VERSION ""

NS_ :

BS_:

BU_: WCM VPM VLM VKM UVM TIM TEST_TOOL_2 TEST_TOOL_1 TCP TCM TCCM3 TCCM STC SRR_SRR SRR_SLR SRR_RR SRR_RF SRR_LR_CR SRR_LF SIB SDM SCL SBZA_R SBZA_L SBM SADS RadioLow RSC RDCM PTM PDR PA NVM MTCM_R MTCM_L MSM_RR MSM_P MSM_LR MSM_D MSB2 MSB1 MRCM_R MRCM_L MFC LRR_HC LRR LIB1 IPC ICS_Info ICCM HVAC_FP_R HVAC_FP_F HUD_CAN HDLM FCM_LC FCM EPS EOCM_HCP2 EOCM_HCP1 EOCM ELM ECP_X1 ECP_MC ECP_E ECM EBCM DMS DEFC DCM CSM CMMb CMMa CGM BSM_MH BSM BCM ARS ARB APA AOS AMP ALC AHS AHL_AFL AGC

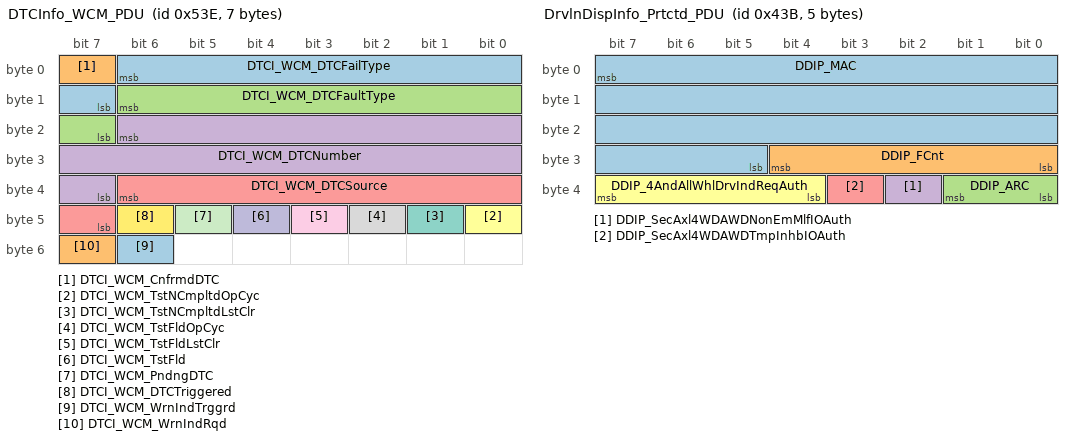
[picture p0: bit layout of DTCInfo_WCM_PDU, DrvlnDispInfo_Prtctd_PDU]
BO_ 1342 DTCInfo_WCM_PDU: 7 WCM
 SG_ DTCI_WCM_DTCFailType : 6|8@0+ (1,0) [0|255] "" CSM,TCP
 SG_ DTCI_WCM_CnfrmdDTC : 7|1@0+ (1,0) [0|1] "" CSM,TCP
 SG_ DTCI_WCM_DTCFaultType : 14|8@0+ (1,0) [0|3] "" CSM,TCP
 SG_ DTCI_WCM_DTCNumber : 22|16@0+ (1,0) [0|65535] "" CSM,TCP
 SG_ DTCI_WCM_DTCSource : 38|8@0+ (1,0) [0|255] "" CGM,CSM,TCP
 SG_ DTCI_WCM_TstNCmpltdOpCyc : 40|1@0+ (1,0) [0|1] "" CSM,TCP
 SG_ DTCI_WCM_TstNCmpltdLstClr : 41|1@0+ (1,0) [0|1] "" CSM,TCP
 SG_ DTCI_WCM_TstFldOpCyc : 42|1@0+ (1,0) [0|1] "" CSM,TCP
 SG_ DTCI_WCM_TstFldLstClr : 43|1@0+ (1,0) [0|1] "" CSM,TCP
 SG_ DTCI_WCM_TstFld : 44|1@0+ (1,0) [0|1] "" CSM,TCP
 SG_ DTCI_WCM_PndngDTC : 45|1@0+ (1,0) [0|1] "" CSM,TCP
 SG_ DTCI_WCM_DTCTriggered : 46|1@0+ (1,0) [0|1] "" CSM,TCP
 SG_ DTCI_WCM_WrnIndTrggrd : 54|1@0+ (1,0) [0|1] "" CSM,TCP
 SG_ DTCI_WCM_WrnIndRqd : 55|1@0+ (1,0) [0|1] "" CSM,TCP

BO_ 1085 DrvlnDispInfo_PCSM_PDU: 8 CGM
 SG_ DrvlnDispInfo_PCSM : 0|64@1+ (1,0) [0|1.84467e+019] "" IPC

BO_ 1083 DrvlnDispInfo_Prtctd_PDU: 5 CGM
 SG_ DDIP_MAC : 7|27@0+ (1,0) [0|1.34218e+008] "" IPC
 SG_ DDIP_FCnt : 28|5@0+ (1,0) [0|31] "" IPC
 SG_ DDIP_ARC : 33|2@0+ (1,0) [0|3] "" IPC
 SG_ DDIP_SecAxl4WDAWDNonEmMlfIOAuth : 34|1@0+ (1,0) [0|1] "" CSM,IPC
 SG_ DDIP_SecAxl4WDAWDTmpInhbIOAuth : 35|1@0+ (1,0) [0|1] "" CSM,IPC,TCP
 SG_ DDIP_4AndAllWhlDrvIndReqAuth : 39|4@0+ (1,0) [0|15] "" IPC

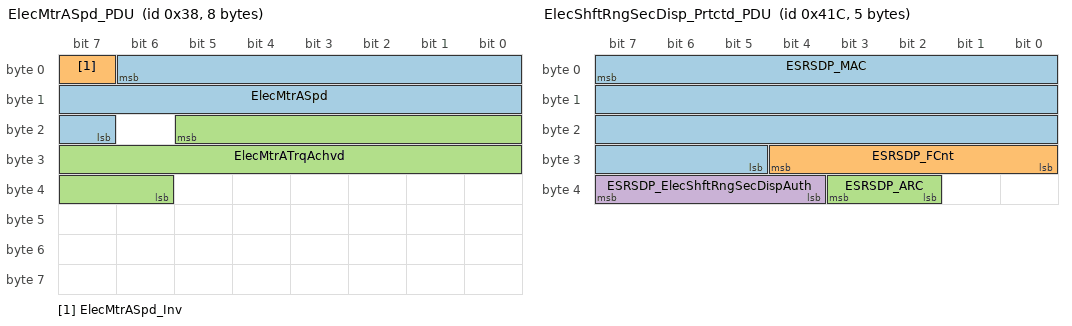
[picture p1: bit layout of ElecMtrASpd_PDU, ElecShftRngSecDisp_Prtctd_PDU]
BO_ 56 ElecMtrASpd_PDU: 8 CGM
 SG_ ElecMtrASpd : 6|16@0- (1,0) [-32768|32767] "RPM" AMP
 SG_ ElecMtrASpd_Inv : 7|1@0+ (1,0) [0|1] "" AMP
 SG_ ElecMtrATrqAchvd : 21|16@0- (0.125,0) [-4096|4095.88] "Nm" AMP

BO_ 1056 ElecShftRngSecDisp_PCSM_PDU: 8 CGM
 SG_ ElecShftRngSecDisp_PCSM : 0|64@1+ (1,0) [0|1.84467e+019] "" IPC

BO_ 1052 ElecShftRngSecDisp_Prtctd_PDU: 5 CGM
 SG_ ESRSDP_MAC : 7|27@0+ (1,0) [0|1.34218e+008] "" IPC
 SG_ ESRSDP_FCnt : 28|5@0+ (1,0) [0|31] "" IPC
 SG_ ESRSDP_ARC : 35|2@0+ (1,0) [0|3] "" IPC
 SG_ ESRSDP_ElecShftRngSecDispAuth : 39|4@0+ (1,0) [0|12] "" CSM,IPC

BO_ 592 ElecStrgColLck_PCSM_PDU: 8 CGM
 SG_ ElecStrgColLck_PCSM : 0|64@1+ (1,0) [0|1.84467e+019] "" IPC

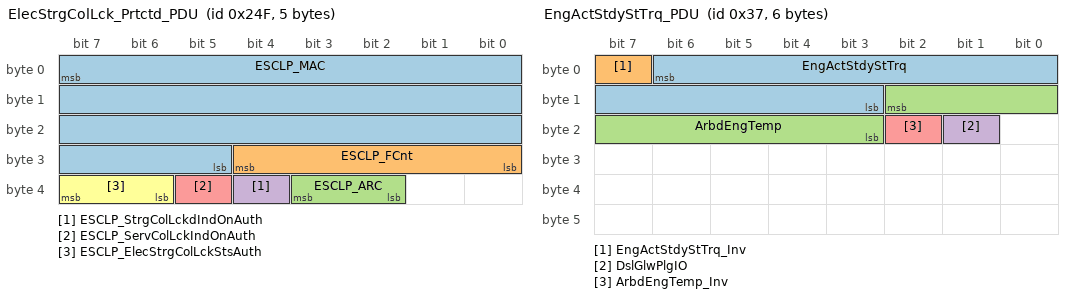
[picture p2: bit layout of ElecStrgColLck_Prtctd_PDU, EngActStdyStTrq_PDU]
BO_ 591 ElecStrgColLck_Prtctd_PDU: 5 CGM
 SG_ ESCLP_MAC : 7|27@0+ (1,0) [0|1.34218e+008] "" IPC
 SG_ ESCLP_FCnt : 28|5@0+ (1,0) [0|31] "" IPC
 SG_ ESCLP_ARC : 35|2@0+ (1,0) [0|3] "" IPC
 SG_ ESCLP_StrgColLckdIndOnAuth : 36|1@0+ (1,0) [0|1] "" IPC
 SG_ ESCLP_ServColLckIndOnAuth : 37|1@0+ (1,0) [0|1] "" IPC
 SG_ ESCLP_ElecStrgColLckStsAuth : 39|2@0+ (1,0) [0|3] "" CSM,IPC

BO_ 55 EngActStdyStTrq_PDU: 6 CGM
 SG_ EngActStdyStTrq : 6|12@0+ (0.5,-848) [-848|1199.5] "Nm" AMP,CSM,IPC,PDR,RadioLow
 SG_ EngActStdyStTrq_Inv : 7|1@0+ (1,0) [0|1] "" AMP,CSM,IPC,PDR
 SG_ ArbdEngTemp : 10|8@0+ (1,-40) [-40|215] "deg C" CSM,IPC,PDR
 SG_ DslGlwPlgIO : 17|1@0+ (1,0) [0|1] "" CSM,IPC
 SG_ ArbdEngTemp_Inv : 18|1@0+ (1,0) [0|1] "" CSM,IPC,PDR

BO_ 1812 EngIdleActvTm_PCSM_PDU: 8 IPC
 SG_ EngIdleActvTm_PCSM : 0|64@1+ (1,0) [0|1.84467e+019] "" CGM

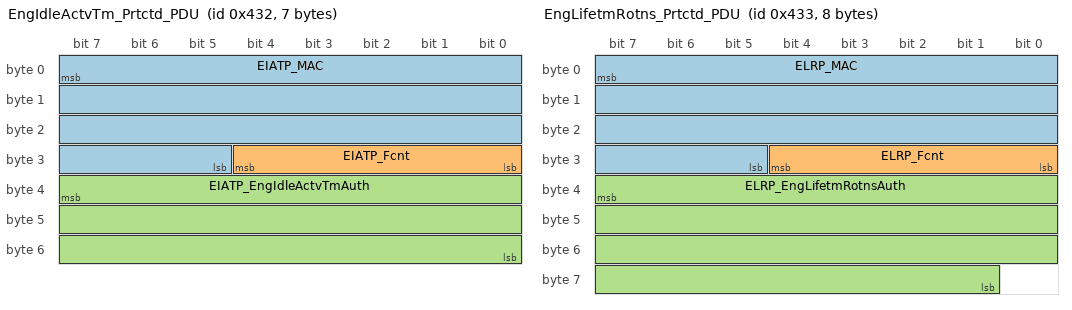
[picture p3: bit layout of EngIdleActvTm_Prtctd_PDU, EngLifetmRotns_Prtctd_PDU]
BO_ 1074 EngIdleActvTm_Prtctd_PDU: 7 IPC
 SG_ EIATP_MAC : 7|27@0+ (1,0) [0|1.34218e+008] "" CGM
 SG_ EIATP_Fcnt : 28|5@0+ (1,0) [0|31] "" CGM
 SG_ EIATP_EngIdleActvTmAuth : 39|24@0+ (1,0) [0|1.67772e+007] "min" CGM,CSM

BO_ 1813 EngLifetmRotns_PCSM_PDU: 8 IPC
 SG_ EngLifetmRotns_PCSM : 0|64@1+ (1,0) [0|1.84467e+019] "" CGM

BO_ 1075 EngLifetmRotns_Prtctd_PDU: 8 IPC
 SG_ ELRP_MAC : 7|27@0+ (1,0) [0|1.34218e+008] "" Vector__XXX
 SG_ ELRP_Fcnt : 28|5@0+ (1,0) [0|31] "" Vector__XXX
 SG_ ELRP_EngLifetmRotnsAuth : 39|31@0+ (1000,0) [0|2.14748e+012] "rotations" CSM

BO_ 1814 EngRunActvTm_PCSM_PDU: 8 IPC
 SG_ EngRunActvTm_PCSM : 0|64@1+ (1,0) [0|1.84467e+019] "" CGM

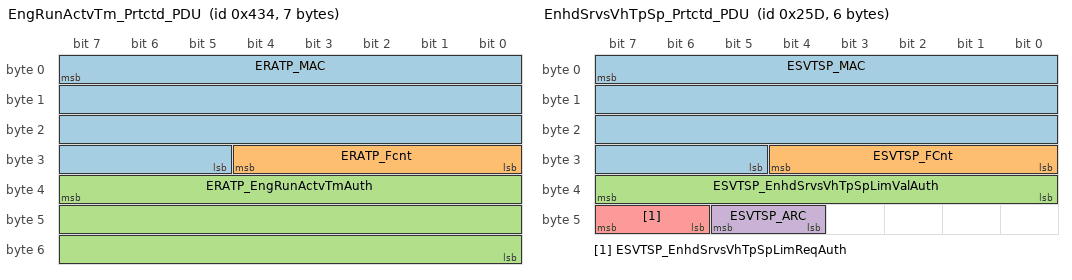
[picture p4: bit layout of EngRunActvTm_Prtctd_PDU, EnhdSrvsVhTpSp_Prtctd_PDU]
BO_ 1076 EngRunActvTm_Prtctd_PDU: 7 IPC
 SG_ ERATP_MAC : 7|27@0+ (1,0) [0|1.34218e+008] "" CGM
 SG_ ERATP_Fcnt : 28|5@0+ (1,0) [0|31] "" CGM
 SG_ ERATP_EngRunActvTmAuth : 39|24@0+ (1,0) [0|1.67772e+007] "min" CGM,CSM

BO_ 1817 EnhdSrvsVhTpSp_PCSM_PDU: 8 TCP
 SG_ EnhdSrvsVhTpSp_PCSM : 0|64@1+ (1,0) [0|1.84467e+019] "" Vector__XXX

BO_ 605 EnhdSrvsVhTpSp_Prtctd_PDU: 6 TCP
 SG_ ESVTSP_MAC : 7|27@0+ (1,0) [0|1.34218e+008] "" Vector__XXX
 SG_ ESVTSP_FCnt : 28|5@0+ (1,0) [0|31] "" Vector__XXX
 SG_ ESVTSP_EnhdSrvsVhTpSpLimValAuth : 39|8@0+ (2,0) [0|510] "km/h" Vector__XXX
 SG_ ESVTSP_ARC : 45|2@0+ (1,0) [0|3] "" Vector__XXX
 SG_ ESVTSP_EnhdSrvsVhTpSpLimReqAuth : 47|2@0+ (1,0) [0|2] "" Vector__XXX

BO_ 1795 FrtTirePrs_PCSM_PDU: 8 CGM
 SG_ FrtTirePrs_PCSM : 0|64@1+ (1,0) [0|1.84467e+019] "" IPC

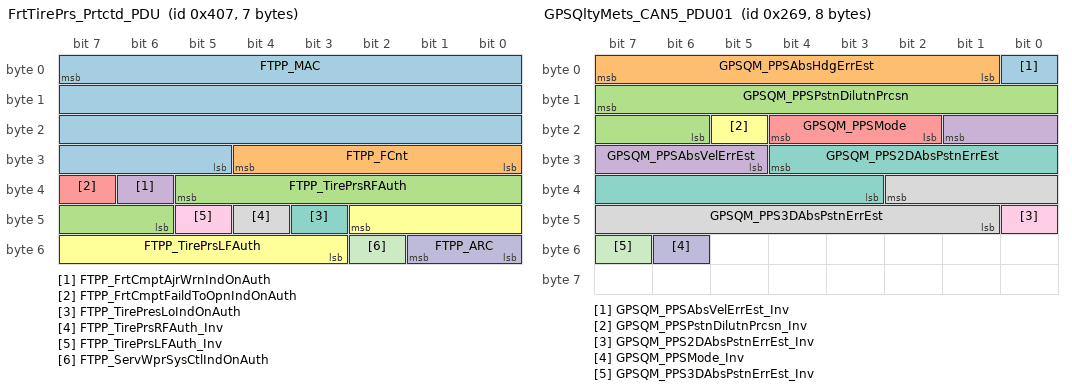
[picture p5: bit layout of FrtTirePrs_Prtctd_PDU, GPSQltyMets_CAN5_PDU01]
BO_ 1031 FrtTirePrs_Prtctd_PDU: 7 CGM
 SG_ FTPP_MAC : 7|27@0+ (1,0) [0|1.34218e+008] "" IPC
 SG_ FTPP_FCnt : 28|5@0+ (1,0) [0|31] "" IPC
 SG_ FTPP_TirePrsRFAuth : 37|8@0+ (4,0) [0|1020] "kPaG" CSM,IPC,PDR,RadioLow,TCP,VKM
 SG_ FTPP_FrtCmptAjrWrnIndOnAuth : 38|1@0+ (1,0) [0|1] "" IPC
 SG_ FTPP_FrtCmptFaildToOpnIndOnAuth : 39|1@0+ (1,0) [0|1] "" IPC
 SG_ FTPP_TirePrsLFAuth : 42|8@0+ (4,0) [0|1020] "kPaG" CSM,IPC,PDR,RadioLow,TCP,VKM
 SG_ FTPP_TirePresLoIndOnAuth : 43|1@0+ (1,0) [0|1] "" CSM,IPC
 SG_ FTPP_TirePrsRFAuth_Inv : 44|1@0+ (1,0) [0|1] "" CSM,IPC,PDR,RadioLow,TCP,VKM
 SG_ FTPP_TirePrsLFAuth_Inv : 45|1@0+ (1,0) [0|1] "" CSM,IPC,PDR,RadioLow,TCP,VKM
 SG_ FTPP_ARC : 49|2@0+ (1,0) [0|3] "" IPC
 SG_ FTPP_ServWprSysCtlIndOnAuth : 50|1@0+ (1,0) [0|1] "" IPC,TCP

BO_ 617 GPSQltyMets_CAN5_PDU01: 8 TCP
 SG_ GPSQM_PPSAbsVelErrEst_Inv : 0|1@0+ (1,0) [0|1] "" CGM
 SG_ GPSQM_PPSAbsHdgErrEst : 7|7@0+ (0.5,0) [0|63.5] "deg" CSM
 SG_ GPSQM_PPSPstnDilutnPrcsn : 15|10@0+ (0.1,0) [0|102.3] "m" CGM,CSM,RadioLow
 SG_ GPSQM_PPSAbsVelErrEst : 17|5@0+ (1,0) [0|31] "km/hr" CGM,CSM
 SG_ GPSQM_PPSMode : 20|3@0+ (1,0) [0|7] "" CSM
 SG_ GPSQM_PPSPstnDilutnPrcsn_Inv : 21|1@0+ (1,0) [0|1] "" CGM,CSM,RadioLow
 SG_ GPSQM_PPS2DAbsPstnErrEst : 28|10@0+ (0.1,0) [0|102.3] "m" CSM
 SG_ GPSQM_PPS3DAbsPstnErrEst : 34|10@0+ (0.1,0) [0|102.3] "m" CSM
 SG_ GPSQM_PPS2DAbsPstnErrEst_Inv : 40|1@0+ (1,0) [0|1] "" CSM
 SG_ GPSQM_PPSMode_Inv : 54|1@0+ (1,0) [0|1] "" CSM
 SG_ GPSQM_PPS3DAbsPstnErrEst_Inv : 55|1@0+ (1,0) [0|1] "" CSM

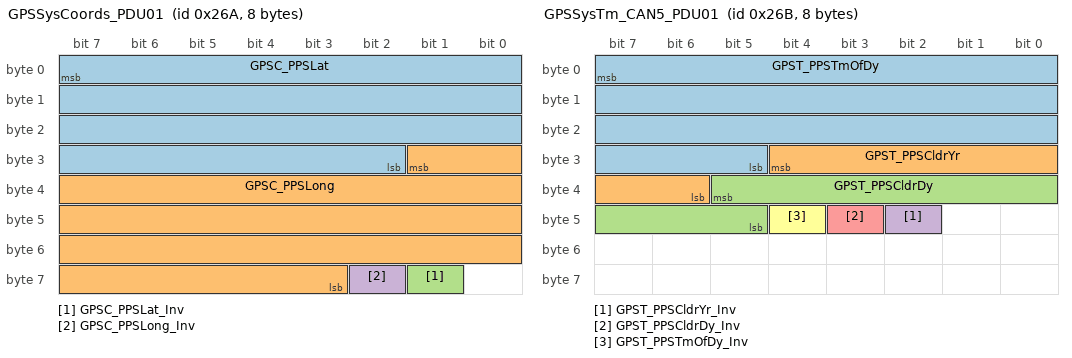
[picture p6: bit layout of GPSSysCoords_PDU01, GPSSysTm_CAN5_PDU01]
BO_ 618 GPSSysCoords_PDU01: 8 TCP
 SG_ GPSC_PPSLat : 7|30@0- (1,0) [-5.36871e+008|5.36871e+008] "ms arc" CGM,CSM,PDR,RadioLow,VKM
 SG_ GPSC_PPSLong : 25|31@0- (1,0) [-1.07374e+009|1.07374e+009] "ms arc" CGM,CSM,PDR,RadioLow,VKM
 SG_ GPSC_PPSLat_Inv : 57|1@0+ (1,0) [0|1] "" CGM,CSM,PDR,RadioLow,VKM
 SG_ GPSC_PPSLong_Inv : 58|1@0+ (1,0) [0|1] "" CGM,CSM,PDR,RadioLow,VKM

BO_ 619 GPSSysTm_CAN5_PDU01: 8 TCP
 SG_ GPST_PPSTmOfDy : 7|27@0+ (1,0) [0|1.34218e+008] "ms" CSM,RadioLow
 SG_ GPST_PPSCldrYr : 28|7@0+ (1,2014) [2014|2141] "year" CSM,RadioLow
 SG_ GPST_PPSCldrDy : 37|9@0+ (1,0) [0|511] "day" CSM,RadioLow
 SG_ GPST_PPSCldrYr_Inv : 42|1@0+ (1,0) [0|1] "" CSM,RadioLow
 SG_ GPST_PPSCldrDy_Inv : 43|1@0+ (1,0) [0|1] "" CSM,RadioLow
 SG_ GPST_PPSTmOfDy_Inv : 44|1@0+ (1,0) [0|1] "" CSM,RadioLow

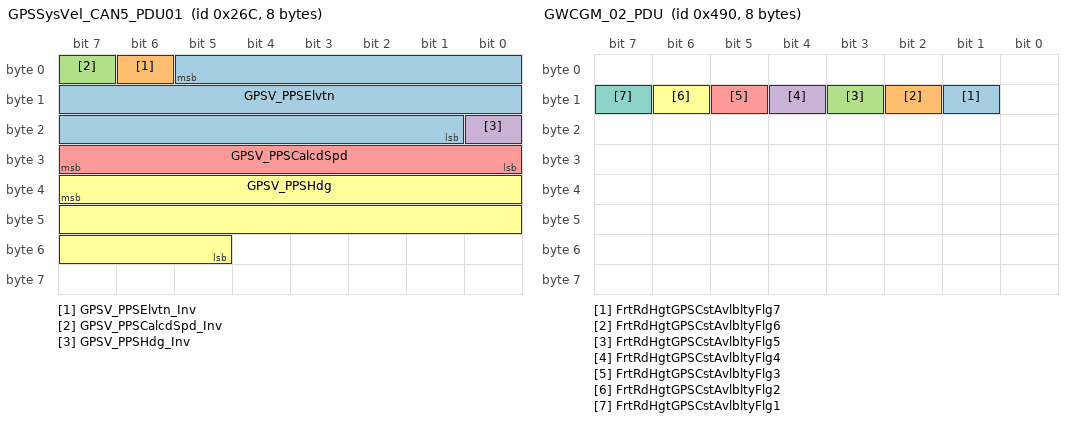
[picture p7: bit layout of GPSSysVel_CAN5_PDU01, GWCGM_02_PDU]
BO_ 620 GPSSysVel_CAN5_PDU01: 8 TCP
 SG_ GPSV_PPSElvtn : 5|21@0+ (1,-100000) [-100000|1.99715e+006] "cm" CGM,CSM,RadioLow
 SG_ GPSV_PPSElvtn_Inv : 6|1@0+ (1,0) [0|1] "" CGM,CSM,RadioLow
 SG_ GPSV_PPSCalcdSpd_Inv : 7|1@0+ (1,0) [0|1] "" CGM,CSM,RadioLow
 SG_ GPSV_PPSHdg_Inv : 16|1@0+ (1,0) [0|1] "" CGM,CSM,RadioLow
 SG_ GPSV_PPSCalcdSpd : 31|8@0+ (1,0) [0|255] "km/h" CGM,CSM,RadioLow
 SG_ GPSV_PPSHdg : 39|19@0+ (0.001,0) [0|524.287] "deg" CGM,CSM,RadioLow

BO_ 1168 GWCGM_02_PDU: 8 CGM
 SG_ FrtRdHgtGPSCstAvlbltyFlg7 : 9|1@0+ (1,0) [0|1] "" CSM,RadioLow
 SG_ FrtRdHgtGPSCstAvlbltyFlg6 : 10|1@0+ (1,0) [0|1] "" CSM,RadioLow
 SG_ FrtRdHgtGPSCstAvlbltyFlg5 : 11|1@0+ (1,0) [0|1] "" CSM,RadioLow
 SG_ FrtRdHgtGPSCstAvlbltyFlg4 : 12|1@0+ (1,0) [0|1] "" CSM,RadioLow
 SG_ FrtRdHgtGPSCstAvlbltyFlg3 : 13|1@0+ (1,0) [0|1] "" CSM,RadioLow
 SG_ FrtRdHgtGPSCstAvlbltyFlg2 : 14|1@0+ (1,0) [0|1] "" CSM,RadioLow
 SG_ FrtRdHgtGPSCstAvlbltyFlg1 : 15|1@0+ (1,0) [0|1] "" CSM,RadioLow

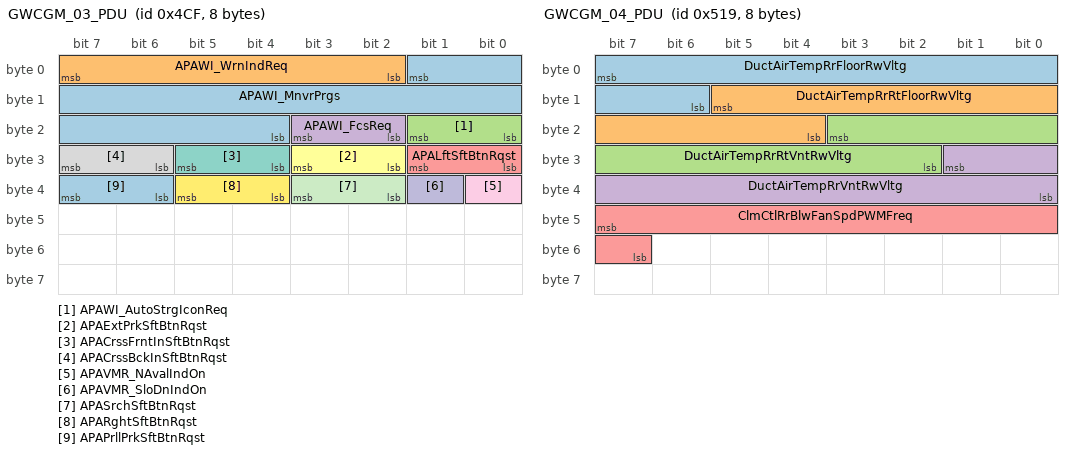
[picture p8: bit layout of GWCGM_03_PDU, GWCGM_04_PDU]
BO_ 1231 GWCGM_03_PDU: 8 CGM
 SG_ APAWI_MnvrPrgs : 1|14@0+ (0.01,0) [0|163.83] "" CSM,IPC,RadioLow
 SG_ APAWI_WrnIndReq : 7|6@0+ (1,0) [0|55] "" CSM,IPC,RadioLow,TCP
 SG_ APAWI_AutoStrgIconReq : 17|2@0+ (1,0) [0|2] "" CSM,IPC,RadioLow
 SG_ APAWI_FcsReq : 19|2@0+ (1,0) [0|2] "" CSM,IPC,RadioLow
 SG_ APALftSftBtnRqst : 25|2@0+ (1,0) [0|3] "" CSM,IPC,RadioLow
 SG_ APAExtPrkSftBtnRqst : 27|2@0+ (1,0) [0|3] "" CSM,RadioLow
 SG_ APACrssFrntInSftBtnRqst : 29|2@0+ (1,0) [0|3] "" CSM,RadioLow
 SG_ APACrssBckInSftBtnRqst : 31|2@0+ (1,0) [0|3] "" CSM,RadioLow
 SG_ APAVMR_NAvalIndOn : 32|1@0+ (1,0) [0|1] "" IPC,TCP
 SG_ APAVMR_SloDnIndOn : 33|1@0+ (1,0) [0|1] "" IPC
 SG_ APASrchSftBtnRqst : 35|2@0+ (1,0) [0|3] "" CSM,RadioLow
 SG_ APARghtSftBtnRqst : 37|2@0+ (1,0) [0|3] "" CSM,IPC,RadioLow
 SG_ APAPrllPrkSftBtnRqst : 39|2@0+ (1,0) [0|3] "" CSM,RadioLow

BO_ 1305 GWCGM_04_PDU: 8 HVAC_FP_R
 SG_ DuctAirTempRrFloorRwVltg : 7|10@0+ (0.005,0) [0|5.115] "Volts" Vector__XXX
 SG_ DuctAirTempRrRtFloorRwVltg : 13|10@0+ (0.005,0) [0|5.115] "Volts" Vector__XXX
 SG_ DuctAirTempRrRtVntRwVltg : 19|10@0+ (0.005,0) [0|5.115] "Volts" Vector__XXX
 SG_ DuctAirTempRrVntRwVltg : 25|10@0+ (0.005,0) [0|5.115] "Volts" Vector__XXX
 SG_ ClmCtlRrBlwFanSpdPWMFreq : 47|9@0+ (1.56863,0) [0|801.568] "Hz" Vector__XXX

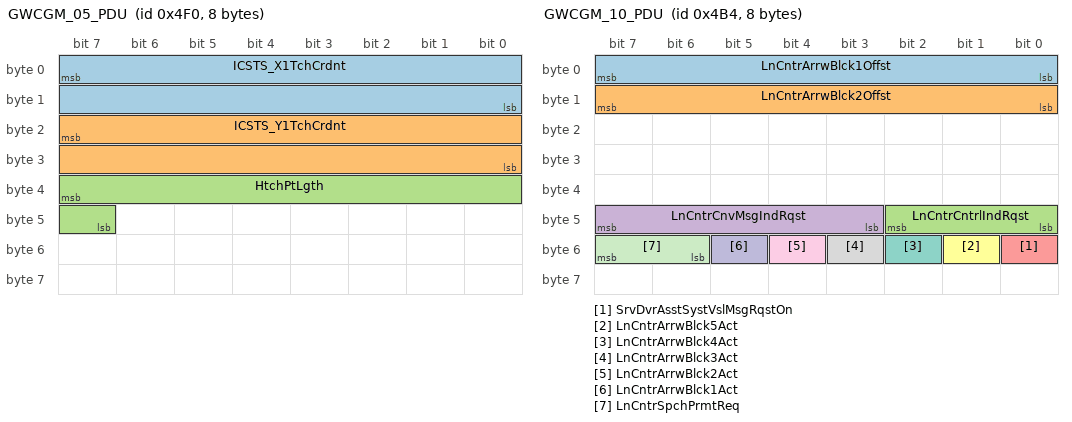
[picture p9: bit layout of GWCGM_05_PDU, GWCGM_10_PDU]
BO_ 1264 GWCGM_05_PDU: 8 CSM
 SG_ ICSTS_X1TchCrdnt : 7|16@0+ (0.001526,0) [0|100.006] "%" RadioLow
 SG_ ICSTS_Y1TchCrdnt : 23|16@0+ (0.001526,0) [0|100.006] "%" RadioLow
 SG_ HtchPtLgth : 39|9@0+ (1,0) [0|511] "cm" Vector__XXX

BO_ 1232 GWCGM_06_PDU: 8 CGM
 SG_ DM2Name : 2|5@0+ (1,0) [0|23] "" CSM,IPC,PDR
 SG_ DM1Name : 7|5@0+ (1,0) [0|23] "" CSM,IPC,PDR
 SG_ DM4Name : 8|5@0+ (1,0) [0|23] "" CSM,IPC,PDR
 SG_ DM3Name : 13|5@0+ (1,0) [0|23] "" CSM,IPC,PDR
 SG_ DM5Name : 19|5@0+ (1,0) [0|23] "" CSM,IPC,PDR
 SG_ DM7Name : 25|5@0+ (1,0) [0|23] "" CSM,IPC,PDR
 SG_ DM6Name : 30|5@0+ (1,0) [0|23] "" CSM,IPC,PDR
 SG_ DM8Name : 36|5@0+ (1,0) [0|23] "" CSM,IPC,PDR
 SG_ DM6Status : 40|1@0+ (1,0) [0|1] "" CSM,IPC,PDR
 SG_ DM5Status : 41|1@0+ (1,0) [0|1] "" CSM,IPC,PDR
 SG_ DM4Status : 42|1@0+ (1,0) [0|1] "" CSM,IPC,PDR
 SG_ DM3Status : 43|1@0+ (1,0) [0|1] "" CSM,IPC,PDR
 SG_ DM2Status : 44|1@0+ (1,0) [0|1] "" CSM,IPC,PDR
 SG_ DM1Status : 45|1@0+ (1,0) [0|1] "" CSM,IPC,PDR
 SG_ EngCmptAjr : 46|1@0+ (1,0) [0|1] "" CSM,IPC,TCP,VKM
 SG_ EngCmptAjr_Inv : 47|1@0+ (1,0) [0|1] "" IPC,VKM
 SG_ FrtStrgeCmptAjr : 53|1@0+ (1,0) [0|1] "" VKM
 SG_ DM8Status : 54|1@0+ (1,0) [0|1] "" CSM,IPC,PDR
 SG_ DM7Status : 55|1@0+ (1,0) [0|1] "" CSM,IPC,PDR

BO_ 1202 GWCGM_07_PDU: 8 CGM
 SG_ BrkPadLifeFrt : 6|7@0+ (1,0) [0|127] "%" CSM,IPC,TCP
 SG_ BrkPadLifeFrt_Inv : 7|1@0+ (1,0) [0|1] "" CSM,IPC,TCP
 SG_ BrkPadLifeRr : 14|7@0+ (1,0) [0|127] "%" CSM,IPC,TCP
 SG_ BrkPadLifeRr_Inv : 15|1@0+ (1,0) [0|1] "" CSM,IPC,TCP
 SG_ ElecPrkBrkSysDisIndReq : 17|3@0+ (1,0) [0|7] "" CSM,IPC
 SG_ EPBStpOnBrkToRelPrkBrkIndReq : 20|3@0+ (1,0) [0|7] "" CSM,IPC
 SG_ BrkPadLifeStsIndReq : 23|3@0+ (1,0) [0|6] "" CSM,IPC,TCP
 SG_ AutoHldDsbldDrOpnIndOn : 24|1@0+ (1,0) [0|1] "" IPC
 SG_ AutoHldAppBrkPedIndOn : 25|1@0+ (1,0) [0|1] "" IPC
 SG_ AutoHldActv : 26|1@0+ (1,0) [0|1] "" IPC
 SG_ ABSActvIndOn : 27|1@0+ (1,0) [0|1] "" CSM,IPC,TCP
 SG_ PerfMdMainMenuTy : 30|3@0+ (1,0) [0|7] "" CSM,RadioLow
 SG_ ESCOffIO : 32|1@0+ (1,0) [0|1] "" CSM,IPC
 SG_ ESCInitIO : 33|1@0+ (1,0) [0|1] "" IPC
 SG_ ESCCmptMdIO : 34|1@0+ (1,0) [0|1] "" IPC
 SG_ BrkPadWrnIO : 35|1@0+ (1,0) [0|1] "" CSM,IPC,TCP
 SG_ BrkPadLifeRrRstAval : 36|1@0+ (1,0) [0|1] "" IPC
 SG_ BrkPadLifeFrtRstAval : 37|1@0+ (1,0) [0|1] "" IPC
 SG_ AutoHldServIndOn : 38|1@0+ (1,0) [0|1] "" IPC
 SG_ AutoHldDsbldStBltIndOn : 39|1@0+ (1,0) [0|1] "" IPC
 SG_ TrlrStbAsstActIO : 40|1@0+ (1,0) [0|1] "" IPC
 SG_ SrvESCMdIO : 41|1@0+ (1,0) [0|1] "" IPC,TCP
 SG_ ServTracCtlIndOn : 42|1@0+ (1,0) [0|1] "" IPC,TCP
 SG_ HillStrtAstActIO : 45|1@0+ (1,0) [0|1] "" CSM,IPC
 SG_ HillRollCntrlActIO : 46|1@0+ (1,0) [0|1] "" CSM,IPC
 SG_ ESCPrfMdIO : 47|1@0+ (1,0) [0|1] "" IPC
 SG_ VehStbEnhcmntCustAv : 52|1@0+ (1,0) [0|1] "" IPC,TCP
 SG_ VehStbEnhcmntCurStat : 53|1@0+ (1,0) [0|1] "" CSM,IPC,PDR,TCP
 SG_ VehStbCompMdCustAv : 54|1@0+ (1,0) [0|1] "" IPC,TCP
 SG_ VehStbCompMdCurStat : 55|1@0+ (1,0) [0|1] "" IPC,TCP

BO_ 1203 GWCGM_08_PDU: 8 CGM
 SG_ FllwgTmDsplyMd : 0|5@0+ (1,0) [0|4] "" CSM,HUD_CAN,IPC
 SG_ FllwgTmIndVal : 7|7@0+ (0.1,0) [0|12.7] "s" CSM,HUD_CAN,IPC,TCP
 SG_ AdpAndCnvntlCruzCtlIndReq : 11|4@0+ (1,0) [0|9] "" CSM,IPC
 SG_ LtAstStsIndRq : 16|3@0+ (1,0) [0|4] "" IPC
 SG_ FCAGpSet : 19|3@0+ (1,0) [0|5] "" CSM,TCP
 SG_ LAOA_LatAsstLDWOptAval : 20|1@0+ (1,0) [0|1] "" IPC
 SG_ LAOA_LatAsstHoLFOptAval : 21|1@0+ (1,0) [0|1] "" IPC
 SG_ LAOA_LatAsstLKAOptAval : 22|1@0+ (1,0) [0|1] "" IPC
 SG_ LAOA_LatAsstOffOptAval : 23|1@0+ (1,0) [0|1] "" IPC
 SG_ PdWrnIndRqst : 25|2@0+ (1,0) [0|3] "" CSM,HUD_CAN,IPC
 SG_ FrwdHdwyVisIndCtl : 27|2@0+ (1,0) [0|2] "" IPC
 SG_ ACCHdwySttng : 29|2@0+ (1,0) [0|2] "" CSM,IPC,TCP
 SG_ FCA_ACCGapSetIndOn : 32|1@0+ (1,0) [0|1] "" IPC
 SG_ ACCTmpUnvIndOn : 33|1@0+ (1,0) [0|1] "" CSM,IPC,TCP
 SG_ ACCSysSlctdMdDspIndOn : 34|1@0+ (1,0) [0|1] "" IPC,TCP
 SG_ ACCShftToPrkBfrExIndOn : 35|1@0+ (1,0) [0|1] "" IPC,TCP
 SG_ ACCRtSpdAdVsIndOn : 36|1@0+ (1,0) [0|1] "" IPC,TCP
 SG_ ACCHdwySttngIndOn : 37|1@0+ (1,0) [0|1] "" TCP
 SG_ ACCDsngIndOn : 38|1@0+ (1,0) [0|1] "" CSM,IPC,TCP
 SG_ ACCDrSlctdSpdIndOn : 39|1@0+ (1,0) [0|1] "" CSM,IPC,TCP
 SG_ LnKpAsstUnAvIndOn : 40|1@0+ (1,0) [0|1] "" CSM,IPC,TCP
 SG_ LnDprtrWrngUnAvIndOn : 41|1@0+ (1,0) [0|1] "" CSM,IPC,TCP
 SG_ FrwdClsnSysIndOn : 42|1@0+ (1,0) [0|1] "" CSM,IPC
 SG_ FrwdCllsnSysUnIndOn : 43|1@0+ (1,0) [0|1] "" CSM,IPC,TCP
 SG_ FrwdCllsnSysRdIndOn : 44|1@0+ (1,0) [0|1] "" CSM,IPC,TCP
 SG_ FrwdCllsnSysOffIndOn : 45|1@0+ (1,0) [0|1] "" CSM,IPC,TCP
 SG_ FrwdCllsnAlrtOffIndOn : 46|1@0+ (1,0) [0|1] "" CSM,IPC,TCP
 SG_ FrtPedtrnBrkgWrnIndOn : 47|1@0+ (1,0) [0|1] "" IPC
 SG_ ACCDrSlctdSpd : 52|12@0+ (0.0625,0) [0|255.938] "km/h" CSM,IPC
 SG_ TnDrvGapAdjUnvIndOn : 53|1@0+ (1,0) [0|1] "" IPC
 SG_ TeenDrvrLnDprtrWrnOffUnvIndOn : 54|1@0+ (1,0) [0|1] "" IPC
 SG_ SrvFrwdCllsnSysIndOn : 55|1@0+ (1,0) [0|1] "" CSM,IPC,TCP

BO_ 1337 GWCGM_09_PDU: 8 TCP
 SG_ HVACTCR_BlwLvlFrt : 1|4@0+ (1,0) [0|15] "Counts" Vector__XXX
 SG_ HVACTCR_ARC : 3|2@0+ (1,0) [0|3] "" Vector__XXX
 SG_ HVACTCR_RrDfgSet : 5|2@0+ (1,0) [0|2] "" Vector__XXX
 SG_ HVACTCR_RecircSet : 7|2@0+ (1,0) [0|2] "" Vector__XXX
 SG_ HVACTCR_AirDstLtSet : 10|4@0+ (1,0) [0|8] "" Vector__XXX
 SG_ HVACTCR_CompSet : 12|2@0+ (1,0) [0|3] "" Vector__XXX
 SG_ HVACTCR_TempFrtLtLvlActv : 13|1@0+ (1,0) [0|1] "" Vector__XXX
 SG_ HVACTCR_AirDstRtSet : 16|4@0+ (1,0) [0|8] "" Vector__XXX
 SG_ HVACTCR_TempFrtRtLvlActv : 17|1@0+ (1,0) [0|1] "" Vector__XXX
 SG_ HVACTCR_RmtClmCtlReqingSets : 18|1@0+ (1,0) [0|1] "" Vector__XXX
 SG_ HVACTCR_FrtAutoSetChg : 19|1@0+ (1,0) [0|1] "" Vector__XXX
 SG_ HVACTCR_PwrSet : 22|3@0+ (1,0) [0|4] "" Vector__XXX
 SG_ HVACTCR_SyncSet : 26|3@0+ (1,0) [0|4] "" Vector__XXX
 SG_ HVACTCR_MaxDefrSet : 28|2@0+ (1,0) [0|2] "" Vector__XXX
 SG_ HVACTCR_TempFrtRtLvl : 32|7@0+ (1,-16) [-16|111] "Counts" Vector__XXX
 SG_ HVACTCR_TempFrtLtLvl : 39|7@0+ (1,-16) [-16|111] "Counts" Vector__XXX
 SG_ RmtTrlrLtngSeqReq : 40|2@0+ (1,0) [0|2] "" Vector__XXX
 SG_ HVACTCR_BlwLvlFrtActv : 41|1@0+ (1,0) [0|1] "" Vector__XXX
 SG_ TeleAlrmVisReq : 52|2@0+ (1,0) [0|2] "" Vector__XXX
 SG_ TeleAlrmHrnReq : 54|2@0+ (1,0) [0|2] "" Vector__XXX

BO_ 1204 GWCGM_10_PDU: 8 CGM
 SG_ LnCntrArrwBlck1Offst : 7|8@0- (1,0) [-128|127] "" TCP
 SG_ LnCntrArrwBlck2Offst : 15|8@0- (1,0) [-128|127] "" TCP
 SG_ LnCntrCntrlIndRqst : 42|3@0+ (1,0) [0|5] "" CSM,IPC
 SG_ LnCntrCnvMsgIndRqst : 47|5@0+ (1,0) [0|21] "" CSM,TCP
 SG_ SrvDvrAsstSystVslMsgRqstOn : 48|1@0+ (1,0) [0|1] "" IPC,TCP
 SG_ LnCntrArrwBlck5Act : 49|1@0+ (1,0) [0|1] "" TCP
 SG_ LnCntrArrwBlck4Act : 50|1@0+ (1,0) [0|1] "" TCP
 SG_ LnCntrArrwBlck3Act : 51|1@0+ (1,0) [0|1] "" TCP
 SG_ LnCntrArrwBlck2Act : 52|1@0+ (1,0) [0|1] "" TCP
 SG_ LnCntrArrwBlck1Act : 53|1@0+ (1,0) [0|1] "" TCP
 SG_ LnCntrSpchPrmtReq : 55|2@0+ (1,0) [0|2] "" CSM,TCP

BO_ 1306 GWCGM_11_PDU: 8 HVAC_FP_R
 SG_ ReqTmpChgRRRr : 0|7@0- (1,0) [-64|63] "" Vector__XXX
 SG_ ReqTmpChgRLRr : 7|7@0- (1,0) [-64|63] "" Vector__XXX
 SG_ ReqTmpLvlRLRr : 9|7@0+ (1,-16) [-16|111] "" Vector__XXX
 SG_ ReqTmpLvlRRRr : 18|7@0+ (1,-16) [-16|111] "" Vector__XXX
 SG_ ReqBlwLvlChgRrRr : 27|5@0- (1,0) [-16|15] "" Vector__XXX
 SG_ ReqAirDstRRRr : 34|4@0+ (1,0) [0|8] "" Vector__XXX
 SG_ ReqAirDstRLRr : 38|4@0+ (1,0) [0|8] "" Vector__XXX
 SG_ ReqAirDstChgNxtRLRr : 40|1@0+ (1,0) [0|1] "" Vector__XXX
 SG_ RrAirHandlingDrActrPwrFdbk : 42|2@0+ (1,0) [0|2] "" Vector__XXX
 SG_ ReqBlwLvlRrRr : 46|4@0+ (1,0) [0|15] "" Vector__XXX
 SG_ RrHVACCtrlInitFin : 48|1@0+ (1,0) [0|1] "" Vector__XXX
 SG_ ReqTmpLvlRRAtvRr : 49|1@0+ (1,0) [0|1] "" Vector__XXX
 SG_ ReqTmpLvlRLAtvRr : 50|1@0+ (1,0) [0|1] "" Vector__XXX
 SG_ ReqSYNC_RrChgRr : 51|1@0+ (1,0) [0|1] "" Vector__XXX
 SG_ ReqRrHVAC_PwrChgRr : 52|1@0+ (1,0) [0|1] "" Vector__XXX
 SG_ ReqRrAutoRr : 53|1@0+ (1,0) [0|1] "" Vector__XXX
 SG_ ReqBlwLvlRrAtvRr : 54|1@0+ (1,0) [0|1] "" Vector__XXX
 SG_ ReqAirDstChgNxtRRRr : 55|1@0+ (1,0) [0|1] "" Vector__XXX

BO_ 1205 GWCGM_12_PDU: 8 CGM
 SG_ TSMCurrSpdLim : 7|8@0+ (1,0) [0|255] "" CSM,HUD_CAN,IPC
 SG_ TSMEurDispSgn2Mn : 9|6@0+ (1,0) [0|54] "" HUD_CAN,IPC
 SG_ TSMEurDispSgn1Mn : 15|6@0+ (1,0) [0|54] "" HUD_CAN,IPC
 SG_ TSMUSAndCADispSgn1Mn : 19|6@0+ (1,0) [0|45] "" CSM,HUD_CAN,IPC
 SG_ TSMUSAndCADispSgn2Mn : 29|6@0+ (1,0) [0|45] "" CSM,HUD_CAN,IPC
 SG_ TSMEurDispSgn2AddOn : 35|4@0+ (1,0) [0|15] "" HUD_CAN,IPC
 SG_ TSMEurDispSgn1AddOn : 39|4@0+ (1,0) [0|15] "" HUD_CAN,IPC
 SG_ FrwdVsFlDtcnIndOn : 40|1@0+ (1,0) [0|1] "" CSM,IPC
 SG_ FrwdVsAdvWthrIndOn : 41|1@0+ (1,0) [0|1] "" CSM,IPC
 SG_ TSMUSAndCADispSgn2AddOn : 44|3@0+ (1,0) [0|5] "" CSM,HUD_CAN,IPC
 SG_ TSMUSAndCADispSgn1AddOn : 47|3@0+ (1,0) [0|5] "" CSM,HUD_CAN,IPC
 SG_ TrffcLgtAsstHUDWrnIndOn : 48|1@0+ (1,0) [0|1] "" HUD_CAN,IPC
 SG_ TrffcLgtAsstClstrWrnIndOn : 49|1@0+ (1,0) [0|1] "" HUD_CAN,IPC
 SG_ TSMSgnNtfnIndOn : 50|1@0+ (1,0) [0|1] "" HUD_CAN,IPC
 SG_ TSMPDAMnSgnFlshgReq : 51|1@0+ (1,0) [0|1] "" IPC
 SG_ TSMNoEntryIndOn : 52|1@0+ (1,0) [0|1] "" HUD_CAN,IPC
 SG_ TSMIcePsblIndOn : 53|1@0+ (1,0) [0|1] "" IPC
 SG_ TSMAddTrfSgnAvIndOn : 54|1@0+ (1,0) [0|1] "" HUD_CAN,IPC
 SG_ FrwdVsFllBlckIndOn : 55|1@0+ (1,0) [0|1] "" CSM,IPC
 SG_ TrffcLgtAsstRLADWrnIndOn : 63|1@0+ (1,0) [0|1] "" HUD_CAN,IPC

BO_ 1233 GWCGM_13_PDU: 8 CGM
 SG_ FrtRdHgtGPSCstCurrSetVal : 7|3@0+ (1,0) [0|7] "" CSM,RadioLow
 SG_ FrtRdHgtGPSCstSetAval : 35|1@0+ (1,0) [0|1] "" CSM,RadioLow

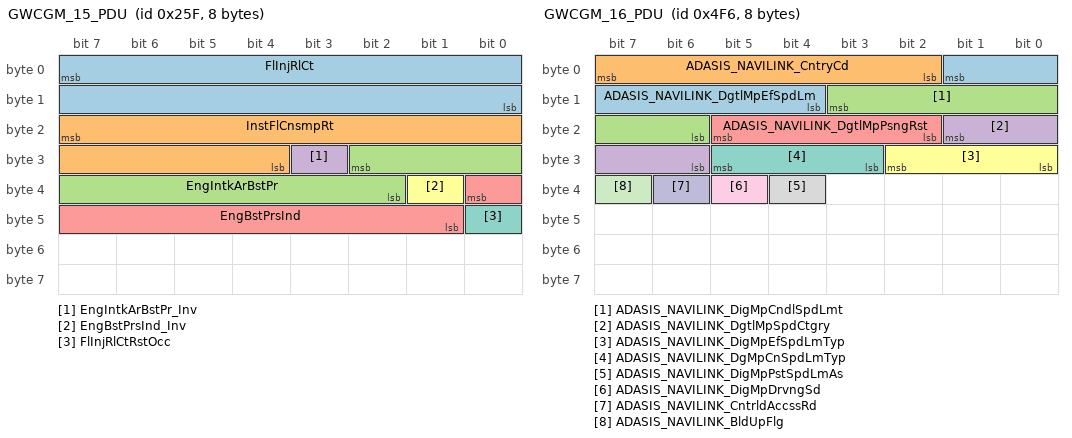
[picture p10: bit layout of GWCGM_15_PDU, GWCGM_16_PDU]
BO_ 607 GWCGM_15_PDU: 8 CGM
 SG_ FlInjRlCt : 7|16@0+ (3.05176e-05,0) [0|1.99997] "liters" CSM,IPC,TCP
 SG_ InstFlCnsmpRt : 23|12@0+ (0.025,0) [0|102.375] "ltrs/hr" CSM,IPC
 SG_ EngIntkArBstPr : 26|9@0+ (1,-110) [-110|401] "kPa" CSM,IPC,PDR
 SG_ EngIntkArBstPr_Inv : 27|1@0+ (1,0) [0|1] "" CSM,IPC,PDR
 SG_ EngBstPrsInd : 32|8@0+ (0.392157,0) [0|100] "%" CSM,IPC,PDR
 SG_ EngBstPrsInd_Inv : 33|1@0+ (1,0) [0|1] "" CSM,IPC,PDR
 SG_ FlInjRlCtRstOcc : 40|1@0+ (1,0) [0|1] "" CSM,IPC,TCP

BO_ 1270 GWCGM_16_PDU: 8 CSM
 SG_ ADASIS_NAVILINK_DgtlMpEfSpdLm : 1|6@0+ (1,0) [0|31] "" Vector__XXX
 SG_ ADASIS_NAVILINK_CntryCd : 7|6@0+ (1,0) [0|46] "" Vector__XXX
 SG_ ADASIS_NAVILINK_DigMpCndlSpdLmt : 11|6@0+ (1,0) [0|31] "" Vector__XXX
 SG_ ADASIS_NAVILINK_DgtlMpSpdCtgry : 17|4@0+ (1,0) [0|8] "" Vector__XXX
 SG_ ADASIS_NAVILINK_DgtlMpPsngRst : 21|4@0+ (1,0) [0|7] "" Vector__XXX
 SG_ ADASIS_NAVILINK_DigMpEfSpdLmTyp : 26|3@0+ (1,0) [0|7] "" Vector__XXX
 SG_ ADASIS_NAVILINK_DgMpCnSpdLmTyp : 29|3@0+ (1,0) [0|7] "" Vector__XXX
 SG_ ADASIS_NAVILINK_DigMpPstSpdLmAs : 36|1@0+ (1,0) [0|1] "" Vector__XXX
 SG_ ADASIS_NAVILINK_DigMpDrvngSd : 37|1@0+ (1,0) [0|1] "" Vector__XXX
 SG_ ADASIS_NAVILINK_CntrldAccssRd : 38|1@0+ (1,0) [0|1] "" Vector__XXX
 SG_ ADASIS_NAVILINK_BldUpFlg : 39|1@0+ (1,0) [0|1] "" Vector__XXX

BO_ 1234 GWCGM_17_PDU: 8 CGM
 SG_ CustMdDrvlCstmCurSetVal : 1|3@0+ (1,0) [0|7] "" CSM,RadioLow,TCP
 SG_ CustMdBrkPdlCstmCurSetVal : 4|3@0+ (1,0) [0|7] "" CSM,RadioLow
 SG_ CustMdActAeroCstmCurSetVal : 7|3@0+ (1,0) [0|7] "" CSM,RadioLow
 SG_ CustMdRideHghtCstmCurSetVal : 8|3@0+ (1,0) [0|7] "" CSM,RadioLow
 SG_ CustMdPTCstmPndSetVal : 11|3@0+ (1,0) [0|7] "" CSM,RadioLow
 SG_ CustMdPTCstmCurSetVal : 14|3@0+ (1,0) [0|7] "" CSM,RadioLow
 SG_ CustMdSpnCstmCurSetVal : 18|3@0+ (1,0) [0|7] "" CSM,RadioLow,TCP
 SG_ CustMdSndCstmCurSetVal : 21|3@0+ (1,0) [0|7] "" CSM,RadioLow
 SG_ CustMdBrkPdlCstmSetAv : 24|1@0+ (1,0) [0|1] "" CSM,RadioLow
 SG_ CustMdActAeroCstmSetAv : 25|1@0+ (1,0) [0|1] "" CSM,RadioLow
 SG_ CustMdTrcStbCstmCurSetVal : 28|3@0+ (1,0) [0|7] "" CSM,RadioLow
 SG_ CustMdStrCstmCurSetVal : 31|3@0+ (1,0) [0|7] "" CSM,RadioLow,TCP
 SG_ CustMdTrcStbCstmSetAv : 33|1@0+ (1,0) [0|1] "" CSM,RadioLow
 SG_ CustMdStrCstmSetAv : 34|1@0+ (1,0) [0|1] "" CSM,RadioLow,TCP
 SG_ CustMdSpnCstmSetAv : 35|1@0+ (1,0) [0|1] "" CSM,RadioLow,TCP
 SG_ CustMdSndCstmSetAv : 36|1@0+ (1,0) [0|1] "" CSM,RadioLow
 SG_ CustMdRideHghtCstmSetAv : 37|1@0+ (1,0) [0|1] "" CSM,RadioLow
 SG_ CustMdPTCstmSetAv : 38|1@0+ (1,0) [0|1] "" CSM,RadioLow
 SG_ CustMdDrvlCstmSetAv : 39|1@0+ (1,0) [0|1] "" CSM,RadioLow,TCP

BO_ 1235 GWCGM_18_PDU: 8 CGM
 SG_ PrsnlMdActAeroCstmCurSetVal : 1|3@0+ (1,0) [0|7] "" CSM,RadioLow
 SG_ ExtdHillStrtAstCustCurSetVal : 4|3@0+ (1,0) [0|7] "" CSM,RadioLow
 SG_ DisPrfMdRq : 7|3@0+ (1,0) [0|7] "" IPC
 SG_ PrsnlMdRideHghtCstmCurSetVal : 8|3@0+ (1,0) [0|7] "" CSM,RadioLow
 SG_ PrsnlMdDrvlCstmCurSetVal : 11|3@0+ (1,0) [0|7] "" CSM,RadioLow,TCP
 SG_ PrsnlMdBrkPdlCstmCurSetVal : 14|3@0+ (1,0) [0|7] "" CSM,RadioLow
 SG_ PrsnlMdSpnCstmCurSetVal : 18|3@0+ (1,0) [0|7] "" CSM,RadioLow,TCP
 SG_ PrsnlMdSndCstmCurSetVal : 21|3@0+ (1,0) [0|7] "" CSM,RadioLow
 SG_ PrsnlMdRideHghtCstmSetAv : 24|1@0+ (1,0) [0|1] "" CSM,RadioLow
 SG_ PrsnlMdDrvlCstmSetAv : 25|1@0+ (1,0) [0|1] "" CSM,RadioLow,TCP
 SG_ PrsnlMdBrkPdlCstmSetAv : 26|1@0+ (1,0) [0|1] "" CSM,RadioLow
 SG_ PrsnlMdActAeroCstmSetAv : 27|1@0+ (1,0) [0|1] "" CSM,RadioLow
 SG_ ExtdHillStrtAstCustSetAvl : 28|1@0+ (1,0) [0|1] "" CSM,RadioLow
 SG_ PrsnlMdStrCstmCurSetVal : 31|3@0+ (1,0) [0|7] "" CSM,RadioLow,TCP
 SG_ TrlrBrkDtd : 36|1@0+ (1,0) [0|1] "" CSM,IPC
 SG_ PrsnlMdStrCstmSetAv : 37|1@0+ (1,0) [0|1] "" CSM,RadioLow,TCP
 SG_ PrsnlMdSpnCstmSetAv : 38|1@0+ (1,0) [0|1] "" CSM,RadioLow,TCP
 SG_ PrsnlMdSndCstmSetAv : 39|1@0+ (1,0) [0|1] "" CSM,RadioLow

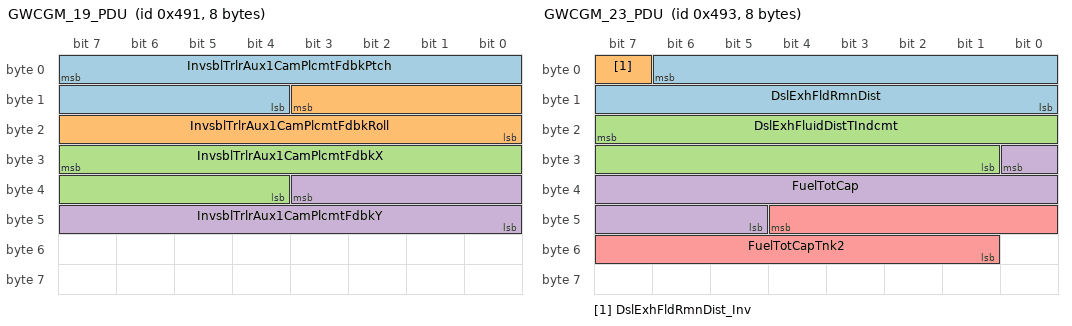
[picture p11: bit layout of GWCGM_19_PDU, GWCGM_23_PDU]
BO_ 1169 GWCGM_19_PDU: 8 CGM
 SG_ InvsblTrlrAux1CamPlcmtFdbkPtch : 7|12@0+ (0.1,-180) [-180|229.5] "degrees" CSM
 SG_ InvsblTrlrAux1CamPlcmtFdbkRoll : 11|12@0+ (0.1,-180) [-180|229.5] "degrees" CSM
 SG_ InvsblTrlrAux1CamPlcmtFdbkX : 31|12@0+ (0.1,-150) [-150|259.5] "cm" CSM
 SG_ InvsblTrlrAux1CamPlcmtFdbkY : 35|12@0+ (0.1,-200) [-200|209.5] "cm" CSM

BO_ 1170 GWCGM_20_PDU: 8 CGM
 SG_ JckKnfDtnCstAvlFlg1 : 0|1@0+ (1,0) [0|1] "" CSM,RadioLow
 SG_ CrgBedVwAutoLgtCstAvlFlg7 : 1|1@0+ (1,0) [0|1] "" CSM,RadioLow
 SG_ CrgBedVwAutoLgtCstAvlFlg6 : 2|1@0+ (1,0) [0|1] "" CSM,RadioLow
 SG_ CrgBedVwAutoLgtCstAvlFlg5 : 3|1@0+ (1,0) [0|1] "" CSM,RadioLow
 SG_ CrgBedVwAutoLgtCstAvlFlg4 : 4|1@0+ (1,0) [0|1] "" CSM,RadioLow
 SG_ CrgBedVwAutoLgtCstAvlFlg3 : 5|1@0+ (1,0) [0|1] "" CSM,RadioLow
 SG_ CrgBedVwAutoLgtCstAvlFlg2 : 6|1@0+ (1,0) [0|1] "" CSM,RadioLow
 SG_ CrgBedVwAutoLgtCstAvlFlg1 : 7|1@0+ (1,0) [0|1] "" CSM,RadioLow
 SG_ RrVwPrkAstSymCsAvlFlg2 : 8|1@0+ (1,0) [0|1] "" CSM,RadioLow
 SG_ RrVwPrkAstSymCsAvlFlg1 : 9|1@0+ (1,0) [0|1] "" CSM,RadioLow
 SG_ JckKnfDtnCstAvlFlg7 : 10|1@0+ (1,0) [0|1] "" CSM,RadioLow
 SG_ JckKnfDtnCstAvlFlg6 : 11|1@0+ (1,0) [0|1] "" CSM,RadioLow
 SG_ JckKnfDtnCstAvlFlg5 : 12|1@0+ (1,0) [0|1] "" CSM,RadioLow
 SG_ JckKnfDtnCstAvlFlg4 : 13|1@0+ (1,0) [0|1] "" CSM,RadioLow
 SG_ JckKnfDtnCstAvlFlg3 : 14|1@0+ (1,0) [0|1] "" CSM,RadioLow
 SG_ JckKnfDtnCstAvlFlg2 : 15|1@0+ (1,0) [0|1] "" CSM,RadioLow
 SG_ SrrndVwLghtCsAvlFlg3 : 16|1@0+ (1,0) [0|1] "" CSM,RadioLow
 SG_ SrrndVwLghtCsAvlFlg2 : 17|1@0+ (1,0) [0|1] "" CSM,RadioLow
 SG_ SrrndVwLghtCsAvlFlg1 : 18|1@0+ (1,0) [0|1] "" CSM,RadioLow
 SG_ RrVwPrkAstSymCsAvlFlg7 : 19|1@0+ (1,0) [0|1] "" CSM,RadioLow
 SG_ RrVwPrkAstSymCsAvlFlg6 : 20|1@0+ (1,0) [0|1] "" CSM,RadioLow
 SG_ RrVwPrkAstSymCsAvlFlg5 : 21|1@0+ (1,0) [0|1] "" CSM,RadioLow
 SG_ RrVwPrkAstSymCsAvlFlg4 : 22|1@0+ (1,0) [0|1] "" CSM,RadioLow
 SG_ RrVwPrkAstSymCsAvlFlg3 : 23|1@0+ (1,0) [0|1] "" CSM,RadioLow
 SG_ TrlrMirVidEnblCstAvlFlg4 : 24|1@0+ (1,0) [0|1] "" CSM,RadioLow
 SG_ TrlrMirVidEnblCstAvlFlg3 : 25|1@0+ (1,0) [0|1] "" CSM,RadioLow
 SG_ TrlrMirVidEnblCstAvlFlg2 : 26|1@0+ (1,0) [0|1] "" CSM,RadioLow
 SG_ TrlrMirVidEnblCstAvlFlg1 : 27|1@0+ (1,0) [0|1] "" CSM,RadioLow
 SG_ SrrndVwLghtCsAvlFlg7 : 28|1@0+ (1,0) [0|1] "" CSM,RadioLow
 SG_ SrrndVwLghtCsAvlFlg6 : 29|1@0+ (1,0) [0|1] "" CSM,RadioLow
 SG_ SrrndVwLghtCsAvlFlg5 : 30|1@0+ (1,0) [0|1] "" CSM,RadioLow
 SG_ SrrndVwLghtCsAvlFlg4 : 31|1@0+ (1,0) [0|1] "" CSM,RadioLow
 SG_ TrlrMirVidGdlnsCstAvlFlg5 : 32|1@0+ (1,0) [0|1] "" CSM,RadioLow
 SG_ TrlrMirVidGdlnsCstAvlFlg4 : 33|1@0+ (1,0) [0|1] "" CSM,RadioLow
 SG_ TrlrMirVidGdlnsCstAvlFlg3 : 34|1@0+ (1,0) [0|1] "" CSM,RadioLow
 SG_ TrlrMirVidGdlnsCstAvlFlg2 : 35|1@0+ (1,0) [0|1] "" CSM,RadioLow
 SG_ TrlrMirVidGdlnsCstAvlFlg1 : 36|1@0+ (1,0) [0|1] "" CSM,RadioLow
 SG_ TrlrMirVidEnblCstAvlFlg7 : 37|1@0+ (1,0) [0|1] "" CSM,RadioLow
 SG_ TrlrMirVidEnblCstAvlFlg6 : 38|1@0+ (1,0) [0|1] "" CSM,RadioLow
 SG_ TrlrMirVidEnblCstAvlFlg5 : 39|1@0+ (1,0) [0|1] "" CSM,RadioLow
 SG_ TrlrMirVidGdlnsCstAvlFlg7 : 46|1@0+ (1,0) [0|1] "" CSM,RadioLow
 SG_ TrlrMirVidGdlnsCstAvlFlg6 : 47|1@0+ (1,0) [0|1] "" CSM,RadioLow

BO_ 1195 GWCGM_21_PDU: 8 CGM
 SG_ IndTmpStngLvlFR : 0|7@0+ (1,0) [0|127] "" CSM,HVAC_FP_F,RadioLow
 SG_ IndTmpStngLvlFL : 7|7@0+ (1,0) [0|127] "" CSM,HVAC_FP_F,RadioLow
 SG_ IndTmpStngLvlRL : 9|7@0+ (1,0) [0|127] "" CSM,HVAC_FP_F,HVAC_FP_R,RadioLow
 SG_ IndTmpStngLvlRR : 18|7@0+ (1,0) [0|127] "" CSM,HVAC_FP_F,HVAC_FP_R,RadioLow
 SG_ IndTmpStngStFR : 24|3@0+ (1,0) [0|4] "" CSM,HVAC_FP_F,RadioLow
 SG_ IndTmpStngStFL : 27|3@0+ (1,0) [0|4] "" CSM,HVAC_FP_F,RadioLow
 SG_ IndTmpStngStRR : 34|3@0+ (1,0) [0|4] "" CSM,HVAC_FP_F,HVAC_FP_R,RadioLow
 SG_ IndTmpStngStRL : 37|3@0+ (1,0) [0|4] "" CSM,HVAC_FP_F,HVAC_FP_R,RadioLow
 SG_ NoRtDetWrngChmEvSt : 41|2@0+ (1,0) [0|2] "" IPC
 SG_ ManlPrkLmpChmEvtSt : 43|2@0+ (1,0) [0|2] "" IPC
 SG_ LDCLDlydLkChmEvSt : 45|2@0+ (1,0) [0|2] "" IPC
 SG_ KeyInRmdrChmEvntSt : 47|2@0+ (1,0) [0|2] "" IPC
 SG_ PwrRrClsrObstclChmEvntStat : 49|2@0+ (1,0) [0|2] "" CSM,IPC
 SG_ PwrRrClsrNtfnChmEvntStat : 51|2@0+ (1,0) [0|2] "" CSM,IPC
 SG_ PwrRrClsrNormOpChmEvntStat : 53|2@0+ (1,0) [0|2] "" CSM,IPC
 SG_ OneSidedPrkLmpActvnChmEvtSt : 55|2@0+ (1,0) [0|2] "" IPC
 SG_ StrgLckd : 57|1@0+ (1,0) [0|1] "" ICS_Info
 SG_ WlkAwyLkInhbtChmEvSt : 59|2@0+ (1,0) [0|2] "" IPC
 SG_ ShfttoPrkChmEvntSt : 61|2@0+ (1,0) [0|2] "" IPC
 SG_ RemLtInVhWrngChmEvSt : 63|2@0+ (1,0) [0|2] "" IPC

BO_ 1196 GWCGM_22_PDU: 8 CGM
 SG_ IndAirDstFR : 3|4@0+ (1,0) [0|9] "" CSM,HVAC_FP_F,HVAC_FP_R,RadioLow
 SG_ IndAirDstFL : 7|4@0+ (1,0) [0|9] "" CSM,HVAC_FP_F,HVAC_FP_R,IPC,RadioLow
 SG_ IndBlwStngLvlRr : 11|4@0+ (1,0) [0|15] "" CSM,HVAC_FP_F,HVAC_FP_R,RadioLow
 SG_ IndBlwStngLvlFrt : 15|4@0+ (1,0) [0|15] "" CSM,HVAC_FP_F,RadioLow
 SG_ IndBlwStngStFrt : 17|2@0+ (1,0) [0|2] "" CSM,HVAC_FP_F,RadioLow
 SG_ IndRecircStng : 25|2@0+ (1,0) [0|2] "" CSM,HVAC_FP_F,RadioLow
 SG_ IndCompStng : 27|2@0+ (1,0) [0|3] "" CSM,HVAC_FP_F,IPC,RadioLow
 SG_ IndClmMdStng : 29|2@0+ (1,0) [0|3] "" CSM,HVAC_FP_F,RadioLow
 SG_ IndBlwStngStRr : 31|2@0+ (1,0) [0|2] "" CSM,HVAC_FP_F,HVAC_FP_R,RadioLow
 SG_ IndAirDstRL : 32|4@0+ (1,0) [0|8] "" CSM,HVAC_FP_F,HVAC_FP_R,RadioLow
 SG_ IndSYNC_Rr : 33|1@0+ (1,0) [0|1] "" CSM,HVAC_FP_F,HVAC_FP_R,RadioLow
 SG_ IndSYNC_All : 34|1@0+ (1,0) [0|1] "" CSM,HVAC_FP_F,HVAC_FP_R,RadioLow
 SG_ IndRrWndDfgStng : 35|1@0+ (1,0) [0|1] "" CSM,HVAC_FP_F,IPC,RadioLow
 SG_ IndRrHVAC_On : 36|1@0+ (1,0) [0|1] "" CSM,HVAC_FP_F,HVAC_FP_R,RadioLow
 SG_ IndRrHVAC_Lckd : 37|1@0+ (1,0) [0|1] "" CSM,HVAC_FP_F,HVAC_FP_R,RadioLow
 SG_ IndHtdFrtWshldSet : 38|1@0+ (1,0) [0|1] "" HVAC_FP_F
 SG_ IndFrtHVAC_On : 39|1@0+ (1,0) [0|1] "" CSM,HVAC_FP_F,RadioLow
 SG_ IndAirDstRR : 44|4@0+ (1,0) [0|8] "" CSM,HVAC_FP_F,HVAC_FP_R,RadioLow

BO_ 1171 GWCGM_23_PDU: 8 CGM
 SG_ DslExhFldRmnDist : 6|15@0+ (2,0) [0|65534] "km" CSM,IPC,TCP
 SG_ DslExhFldRmnDist_Inv : 7|1@0+ (1,0) [0|1] "" CSM,IPC,TCP
 SG_ DslExhFluidDistTIndcmt : 23|15@0+ (2,0) [0|65534] "km" IPC
 SG_ FuelTotCap : 24|12@0+ (0.125,0) [0|511.875] "liters" CSM,IPC,TCP
 SG_ FuelTotCapTnk2 : 44|12@0+ (0.125,0) [0|511.875] "liters" CSM,IPC

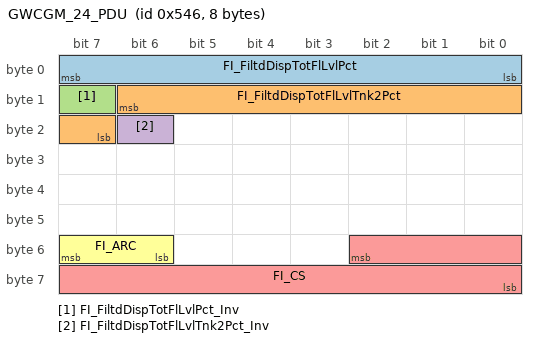
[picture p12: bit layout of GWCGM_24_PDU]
BO_ 1350 GWCGM_24_PDU: 8 CGM
 SG_ FI_FiltdDispTotFlLvlPct : 7|8@0+ (0.3921,0) [0|99.9855] "%" CSM,IPC,PDR,RadioLow,TCP,VKM
 SG_ FI_FiltdDispTotFlLvlTnk2Pct : 14|8@0+ (0.3921,0) [0|99.9855] "%" CSM,IPC,RadioLow,TCP,VKM
 SG_ FI_FiltdDispTotFlLvlPct_Inv : 15|1@0+ (1,0) [0|1] "" CSM,IPC,PDR,RadioLow,TCP,VKM
 SG_ FI_FiltdDispTotFlLvlTnk2Pct_Inv : 22|1@0+ (1,0) [0|1] "" CSM,IPC,TCP,VKM
 SG_ FI_CS : 50|11@0+ (1,0) [0|2047] "" IPC
 SG_ FI_ARC : 55|2@0+ (1,0) [0|3] "" IPC

BO_ 1206 GWCGM_25_PDU: 8 CGM
 SG_ EngIntAirTmp : 6|8@0+ (1,-40) [-40|215] "deg C" CSM,PDR,TCP
 SG_ EngIntAirTmp_Inv : 7|1@0+ (1,0) [0|1] "" CSM,PDR,TCP
 SG_ ASIRI_Ind08 : 8|1@0+ (1,0) [0|1] "" CSM,TCP
 SG_ ASIRI_Ind06 : 9|1@0+ (1,0) [0|1] "" CSM,TCP
 SG_ ASIRI_Ind04 : 10|1@0+ (1,0) [0|1] "" CSM,TCP
 SG_ ASIRI_Ind01 : 11|1@0+ (1,0) [0|1] "" CSM,TCP
 SG_ ASIRI_Ind05 : 12|1@0+ (1,0) [0|1] "" CSM,TCP
 SG_ ASIRI_Ind07 : 13|1@0+ (1,0) [0|1] "" CSM,TCP
 SG_ ASIRI_Ind02 : 14|1@0+ (1,0) [0|1] "" CSM,TCP
 SG_ VhSpdCntlSystmTyp : 16|3@0+ (1,0) [0|2] "" IPC
 SG_ MnlTrnsIndReq : 19|3@0+ (1,0) [0|3] "" IPC
 SG_ EngEmsRltMlfIndRq : 22|3@0+ (1,0) [0|4] "" CSM,IPC
 SG_ ASIRI_Ind03 : 23|1@0+ (1,0) [0|1] "" CSM,TCP
 SG_ ElecShfPriTransCtlrMalfIndOn : 24|1@0+ (1,0) [0|1] "" IPC
 SG_ ElecShfPriShfToDrvTryAgnIndOn : 25|1@0+ (1,0) [0|1] "" IPC
 SG_ EngCmptHotWrnIndReq : 27|2@0+ (1,0) [0|3] "" IPC
 SG_ ElecShftPrTwoGrsSelIndRq : 29|2@0+ (1,0) [0|3] "" IPC
 SG_ ElecShftPrLtdPrfMdIO : 32|1@0+ (1,0) [0|1] "" IPC
 SG_ ElecShftPrHldShftLevEngRngIO : 33|1@0+ (1,0) [0|1] "" IPC
 SG_ ElecShftPrDrPrkIntShftAtmpIO : 34|1@0+ (1,0) [0|1] "" IPC
 SG_ ElecShftPrDrIntShftAtmpIO : 35|1@0+ (1,0) [0|1] "" IPC
 SG_ ElecShftPrDrExitIO : 36|1@0+ (1,0) [0|1] "" IPC
 SG_ ElecShftPrDrDoorStIndIO : 37|1@0+ (1,0) [0|1] "" IPC
 SG_ ElecShftPrAtPrkIO : 38|1@0+ (1,0) [0|1] "" IPC
 SG_ ElecShfPriTrnVehOffForPrkIndOn : 39|1@0+ (1,0) [0|1] "" IPC
 SG_ EngOilChngIO : 40|1@0+ (1,0) [0|1] "" CSM,IPC,RadioLow,TCP,VKM
 SG_ EngNEmsnsRltMlfnAct : 41|1@0+ (1,0) [0|1] "" CSM,IPC
 SG_ EngHtStpEngIO : 42|1@0+ (1,0) [0|1] "" CSM,IPC,TCP
 SG_ EngHtFlEnrchmntIO : 43|1@0+ (1,0) [0|1] "" CSM,IPC,TCP
 SG_ EngCstFlCtOffAct : 44|1@0+ (1,0) [0|1] "" CSM,IPC
 SG_ ElecShftPrTrnMlfIO : 45|1@0+ (1,0) [0|1] "" IPC
 SG_ ElecShftPrRngInvRqIO : 46|1@0+ (1,0) [0|1] "" IPC
 SG_ ElecShftPrPrkInvRqIO : 47|1@0+ (1,0) [0|1] "" IPC
 SG_ GenFld : 48|1@0+ (1,0) [0|1] "" CSM,IPC,TCP
 SG_ EngWtrInFlIO : 49|1@0+ (1,0) [0|1] "" CSM,IPC,TCP
 SG_ EngSpdLmtnMdAct : 50|1@0+ (1,0) [0|1] "" CSM,IPC
 SG_ EngShtdwnPndgIO : 51|1@0+ (1,0) [0|1] "" CSM,IPC,TCP
 SG_ EngOilStrvtnIO : 52|1@0+ (1,0) [0|1] "" CSM,IPC
 SG_ EngOilPrsLwIO : 53|1@0+ (1,0) [0|1] "" CSM,IPC,TCP
 SG_ EngOilLvlLwIO : 54|1@0+ (1,0) [0|1] "" CSM,IPC,RadioLow,TCP,VKM
 SG_ EngOilHotIO : 55|1@0+ (1,0) [0|1] "" CSM,IPC
 SG_ TrnsSkpShftIO : 60|1@0+ (1,0) [0|1] "" CSM,IPC
 SG_ PTWrmgWtToShftIO : 61|1@0+ (1,0) [0|1] "" CSM
 SG_ PTExPrtclFltrWrnIO : 62|1@0+ (1,0) [0|1] "" CSM,IPC,TCP
 SG_ PTExPrtclFltrWrn2IO : 63|1@0+ (1,0) [0|1] "" CSM,IPC,TCP

BO_ 1207 GWCGM_26_PDU: 8 CGM
 SG_ CrsSpdLmtrDrvSelSpd : 7|12@0+ (0.0625,0) [0|255.938] "km / h" CSM,IPC
 SG_ DslExFldCnWrngIndRq : 11|4@0+ (1,0) [0|15] "" IPC
 SG_ DslExNxEmWrngIndRq : 19|4@0+ (1,0) [0|15] "" IPC
 SG_ DslExFldTpWrngIndRq : 23|4@0+ (1,0) [0|15] "" IPC
 SG_ DslExhFldWrngIdRqER : 27|4@0+ (1,0) [0|15] "" IPC,TCP
 SG_ DslExhFldQlyWrngIReq : 31|4@0+ (1,0) [0|15] "" IPC
 SG_ DslExhFldDiagWrnIdRq : 33|3@0+ (1,0) [0|7] "" IPC
 SG_ DrvrSeltdSpdLmtrIndReq : 36|3@0+ (1,0) [0|4] "" IPC
 SG_ CnvntlCruzCtlIndReq : 39|3@0+ (1,0) [0|5] "" CSM,IPC
 SG_ ACCompCmnd : 40|1@0+ (1,0) [0|1] "" CSM,TCP
 SG_ DslEmnsOBDMrkt : 42|2@0+ (1,0) [0|1] "" IPC
 SG_ DrSlctdSpdLmtrStSpdLmtRchd : 44|2@0+ (1,0) [0|3] "" IPC,TCP
 SG_ DrSlctdSpdLmtrSetTypActv : 46|2@0+ (1,0) [0|3] "" CSM,IPC,TCP
 SG_ ElecShfPriRdcSpdForReqdShfIndOn : 48|1@0+ (1,0) [0|1] "" IPC
 SG_ CbnHtrWrmUpIndOn : 49|1@0+ (1,0) [0|1] "" IPC
 SG_ DrSlctdSpdLmtrEnbld : 50|1@0+ (1,0) [0|1] "" CSM,IPC,TCP
 SG_ DrSlctdSpdLmtrActv : 51|1@0+ (1,0) [0|1] "" CSM,IPC,TCP
 SG_ CkFlFilrCapIO : 52|1@0+ (1,0) [0|1] "" CSM,IPC
 SG_ Bat12VSysUnStab : 53|1@0+ (1,0) [0|1] "" IPC
 SG_ AppCltchAutSrtIO : 54|1@0+ (1,0) [0|1] "" CSM,IPC
 SG_ AirCndOffIO : 55|1@0+ (1,0) [0|1] "" CSM,IPC,TCP

BO_ 1173 GWCGM_27_PDU: 8 CGM
 SG_ EBDFld : 0|1@0+ (1,0) [0|1] "" CSM
 SG_ CustMdTrcStbCstmAvFlg7 : 1|1@0+ (1,0) [0|1] "" CSM,RadioLow
 SG_ CustMdTrcStbCstmAvFlg6 : 2|1@0+ (1,0) [0|1] "" CSM,RadioLow
 SG_ CustMdTrcStbCstmAvFlg5 : 3|1@0+ (1,0) [0|1] "" CSM,RadioLow
 SG_ CustMdTrcStbCstmAvFlg4 : 4|1@0+ (1,0) [0|1] "" CSM,RadioLow
 SG_ CustMdTrcStbCstmAvFlg3 : 5|1@0+ (1,0) [0|1] "" CSM,RadioLow
 SG_ CustMdTrcStbCstmAvFlg2 : 6|1@0+ (1,0) [0|1] "" CSM,RadioLow
 SG_ CustMdTrcStbCstmAvFlg1 : 7|1@0+ (1,0) [0|1] "" CSM,RadioLow
 SG_ PrsnlMdActAeroCstmAvFlg1 : 8|1@0+ (1,0) [0|1] "" CSM,RadioLow
 SG_ ExtdHillStrtAstCustAvlFlg7 : 9|1@0+ (1,0) [0|1] "" CSM,RadioLow
 SG_ ExtdHillStrtAstCustAvlFlg6 : 10|1@0+ (1,0) [0|1] "" CSM,RadioLow
 SG_ ExtdHillStrtAstCustAvlFlg5 : 11|1@0+ (1,0) [0|1] "" CSM,RadioLow
 SG_ ExtdHillStrtAstCustAvlFlg4 : 12|1@0+ (1,0) [0|1] "" CSM,RadioLow
 SG_ ExtdHillStrtAstCustAvlFlg3 : 13|1@0+ (1,0) [0|1] "" CSM,RadioLow
 SG_ ExtdHillStrtAstCustAvlFlg2 : 14|1@0+ (1,0) [0|1] "" CSM,RadioLow
 SG_ ExtdHillStrtAstCustAvlFlg1 : 15|1@0+ (1,0) [0|1] "" CSM,RadioLow
 SG_ PrsnlMdBrkPdlCstmAvFlg2 : 16|1@0+ (1,0) [0|1] "" CSM,RadioLow
 SG_ PrsnlMdBrkPdlCstmAvFlg1 : 17|1@0+ (1,0) [0|1] "" CSM,RadioLow
 SG_ PrsnlMdActAeroCstmAvFlg7 : 18|1@0+ (1,0) [0|1] "" CSM,RadioLow
 SG_ PrsnlMdActAeroCstmAvFlg6 : 19|1@0+ (1,0) [0|1] "" CSM,RadioLow
 SG_ PrsnlMdActAeroCstmAvFlg5 : 20|1@0+ (1,0) [0|1] "" CSM,RadioLow
 SG_ PrsnlMdActAeroCstmAvFlg4 : 21|1@0+ (1,0) [0|1] "" CSM,RadioLow
 SG_ PrsnlMdActAeroCstmAvFlg3 : 22|1@0+ (1,0) [0|1] "" CSM,RadioLow
 SG_ PrsnlMdActAeroCstmAvFlg2 : 23|1@0+ (1,0) [0|1] "" CSM,RadioLow
 SG_ PrsnlMdDrvlCstmAvFlg3 : 24|1@0+ (1,0) [0|1] "" CSM,RadioLow,TCP
 SG_ PrsnlMdDrvlCstmAvFlg2 : 25|1@0+ (1,0) [0|1] "" CSM,RadioLow,TCP
 SG_ PrsnlMdDrvlCstmAvFlg1 : 26|1@0+ (1,0) [0|1] "" CSM,RadioLow,TCP
 SG_ PrsnlMdBrkPdlCstmAvFlg7 : 27|1@0+ (1,0) [0|1] "" CSM,RadioLow
 SG_ PrsnlMdBrkPdlCstmAvFlg6 : 28|1@0+ (1,0) [0|1] "" CSM,RadioLow
 SG_ PrsnlMdBrkPdlCstmAvFlg5 : 29|1@0+ (1,0) [0|1] "" CSM,RadioLow
 SG_ PrsnlMdBrkPdlCstmAvFlg4 : 30|1@0+ (1,0) [0|1] "" CSM,RadioLow
 SG_ PrsnlMdBrkPdlCstmAvFlg3 : 31|1@0+ (1,0) [0|1] "" CSM,RadioLow
 SG_ PrsnlMdRideHghtCstmAvFlg4 : 32|1@0+ (1,0) [0|1] "" CSM,RadioLow
 SG_ PrsnlMdRideHghtCstmAvFlg3 : 33|1@0+ (1,0) [0|1] "" CSM,RadioLow
 SG_ PrsnlMdRideHghtCstmAvFlg2 : 34|1@0+ (1,0) [0|1] "" CSM,RadioLow
 SG_ PrsnlMdRideHghtCstmAvFlg1 : 35|1@0+ (1,0) [0|1] "" CSM,RadioLow
 SG_ PrsnlMdDrvlCstmAvFlg7 : 36|1@0+ (1,0) [0|1] "" CSM,RadioLow,TCP
 SG_ PrsnlMdDrvlCstmAvFlg6 : 37|1@0+ (1,0) [0|1] "" CSM,RadioLow,TCP
 SG_ PrsnlMdDrvlCstmAvFlg5 : 38|1@0+ (1,0) [0|1] "" CSM,RadioLow,TCP
 SG_ PrsnlMdDrvlCstmAvFlg4 : 39|1@0+ (1,0) [0|1] "" CSM,RadioLow,TCP
 SG_ PrsnlMdSndCstmAvFlg5 : 40|1@0+ (1,0) [0|1] "" CSM,RadioLow
 SG_ PrsnlMdSndCstmAvFlg4 : 41|1@0+ (1,0) [0|1] "" CSM,RadioLow
 SG_ PrsnlMdSndCstmAvFlg3 : 42|1@0+ (1,0) [0|1] "" CSM,RadioLow
 SG_ PrsnlMdSndCstmAvFlg2 : 43|1@0+ (1,0) [0|1] "" CSM,RadioLow
 SG_ PrsnlMdSndCstmAvFlg1 : 44|1@0+ (1,0) [0|1] "" CSM,RadioLow
 SG_ PrsnlMdRideHghtCstmAvFlg7 : 45|1@0+ (1,0) [0|1] "" CSM,RadioLow
 SG_ PrsnlMdRideHghtCstmAvFlg6 : 46|1@0+ (1,0) [0|1] "" CSM,RadioLow
 SG_ PrsnlMdRideHghtCstmAvFlg5 : 47|1@0+ (1,0) [0|1] "" CSM,RadioLow
 SG_ PrsnlMdSpnCstmAvFlg6 : 48|1@0+ (1,0) [0|1] "" CSM,RadioLow,TCP
 SG_ PrsnlMdSpnCstmAvFlg5 : 49|1@0+ (1,0) [0|1] "" CSM,RadioLow,TCP
 SG_ PrsnlMdSpnCstmAvFlg4 : 50|1@0+ (1,0) [0|1] "" CSM,RadioLow,TCP
 SG_ PrsnlMdSpnCstmAvFlg3 : 51|1@0+ (1,0) [0|1] "" CSM,RadioLow,TCP
 SG_ PrsnlMdSpnCstmAvFlg2 : 52|1@0+ (1,0) [0|1] "" CSM,RadioLow,TCP
 SG_ PrsnlMdSpnCstmAvFlg1 : 53|1@0+ (1,0) [0|1] "" CSM,RadioLow,TCP
 SG_ PrsnlMdSndCstmAvFlg7 : 54|1@0+ (1,0) [0|1] "" CSM,RadioLow
 SG_ PrsnlMdSndCstmAvFlg6 : 55|1@0+ (1,0) [0|1] "" CSM,RadioLow
 SG_ PrsnlMdStrCstmAvFlg7 : 56|1@0+ (1,0) [0|1] "" CSM,RadioLow,TCP
 SG_ PrsnlMdStrCstmAvFlg6 : 57|1@0+ (1,0) [0|1] "" CSM,RadioLow,TCP
 SG_ PrsnlMdStrCstmAvFlg5 : 58|1@0+ (1,0) [0|1] "" CSM,RadioLow,TCP
 SG_ PrsnlMdStrCstmAvFlg4 : 59|1@0+ (1,0) [0|1] "" CSM,RadioLow,TCP
 SG_ PrsnlMdStrCstmAvFlg3 : 60|1@0+ (1,0) [0|1] "" CSM,RadioLow,TCP
 SG_ PrsnlMdStrCstmAvFlg2 : 61|1@0+ (1,0) [0|1] "" CSM,RadioLow,TCP
 SG_ PrsnlMdStrCstmAvFlg1 : 62|1@0+ (1,0) [0|1] "" CSM,RadioLow,TCP
 SG_ PrsnlMdSpnCstmAvFlg7 : 63|1@0+ (1,0) [0|1] "" CSM,RadioLow,TCP

BO_ 1174 GWCGM_28_PDU: 8 CGM
 SG_ CustMdActAeroCstmAvFlg6 : 0|1@0+ (1,0) [0|1] "" CSM,RadioLow
 SG_ CustMdActAeroCstmAvFlg5 : 1|1@0+ (1,0) [0|1] "" CSM,RadioLow
 SG_ CustMdActAeroCstmAvFlg4 : 2|1@0+ (1,0) [0|1] "" CSM,RadioLow
 SG_ CustMdActAeroCstmAvFlg3 : 3|1@0+ (1,0) [0|1] "" CSM,RadioLow
 SG_ CustMdActAeroCstmAvFlg2 : 4|1@0+ (1,0) [0|1] "" CSM,RadioLow
 SG_ CustMdActAeroCstmAvFlg1 : 5|1@0+ (1,0) [0|1] "" CSM,RadioLow
 SG_ BrkFldLvlSt : 7|2@0+ (1,0) [0|2] "" CSM,TCP
 SG_ CustMdBrkPdlCstmAvFlg7 : 8|1@0+ (1,0) [0|1] "" CSM,RadioLow
 SG_ CustMdBrkPdlCstmAvFlg6 : 9|1@0+ (1,0) [0|1] "" CSM,RadioLow
 SG_ CustMdBrkPdlCstmAvFlg5 : 10|1@0+ (1,0) [0|1] "" CSM,RadioLow
 SG_ CustMdBrkPdlCstmAvFlg4 : 11|1@0+ (1,0) [0|1] "" CSM,RadioLow
 SG_ CustMdBrkPdlCstmAvFlg3 : 12|1@0+ (1,0) [0|1] "" CSM,RadioLow
 SG_ CustMdBrkPdlCstmAvFlg2 : 13|1@0+ (1,0) [0|1] "" CSM,RadioLow
 SG_ CustMdBrkPdlCstmAvFlg1 : 14|1@0+ (1,0) [0|1] "" CSM,RadioLow
 SG_ CustMdActAeroCstmAvFlg7 : 15|1@0+ (1,0) [0|1] "" CSM,RadioLow
 SG_ CustMdPTCstmAvFlg1 : 16|1@0+ (1,0) [0|1] "" CSM,RadioLow
 SG_ CustMdDrvlCstmAvFlg7 : 17|1@0+ (1,0) [0|1] "" CSM,RadioLow,TCP
 SG_ CustMdDrvlCstmAvFlg6 : 18|1@0+ (1,0) [0|1] "" CSM,RadioLow,TCP
 SG_ CustMdDrvlCstmAvFlg5 : 19|1@0+ (1,0) [0|1] "" CSM,RadioLow,TCP
 SG_ CustMdDrvlCstmAvFlg4 : 20|1@0+ (1,0) [0|1] "" CSM,RadioLow,TCP
 SG_ CustMdDrvlCstmAvFlg3 : 21|1@0+ (1,0) [0|1] "" CSM,RadioLow,TCP
 SG_ CustMdDrvlCstmAvFlg2 : 22|1@0+ (1,0) [0|1] "" CSM,RadioLow,TCP
 SG_ CustMdDrvlCstmAvFlg1 : 23|1@0+ (1,0) [0|1] "" CSM,RadioLow,TCP
 SG_ CustMdRideHghtCstmAvFlg2 : 24|1@0+ (1,0) [0|1] "" CSM,RadioLow
 SG_ CustMdRideHghtCstmAvFlg1 : 25|1@0+ (1,0) [0|1] "" CSM,RadioLow
 SG_ CustMdPTCstmAvFlg7 : 26|1@0+ (1,0) [0|1] "" CSM,RadioLow
 SG_ CustMdPTCstmAvFlg6 : 27|1@0+ (1,0) [0|1] "" CSM,RadioLow
 SG_ CustMdPTCstmAvFlg5 : 28|1@0+ (1,0) [0|1] "" CSM,RadioLow
 SG_ CustMdPTCstmAvFlg4 : 29|1@0+ (1,0) [0|1] "" CSM,RadioLow
 SG_ CustMdPTCstmAvFlg3 : 30|1@0+ (1,0) [0|1] "" CSM,RadioLow
 SG_ CustMdPTCstmAvFlg2 : 31|1@0+ (1,0) [0|1] "" CSM,RadioLow
 SG_ CustMdSndCstmAvFlg3 : 32|1@0+ (1,0) [0|1] "" CSM,RadioLow
 SG_ CustMdSndCstmAvFlg2 : 33|1@0+ (1,0) [0|1] "" CSM,RadioLow
 SG_ CustMdSndCstmAvFlg1 : 34|1@0+ (1,0) [0|1] "" CSM,RadioLow
 SG_ CustMdRideHghtCstmAvFlg7 : 35|1@0+ (1,0) [0|1] "" CSM,RadioLow
 SG_ CustMdRideHghtCstmAvFlg6 : 36|1@0+ (1,0) [0|1] "" CSM,RadioLow
 SG_ CustMdRideHghtCstmAvFlg5 : 37|1@0+ (1,0) [0|1] "" CSM,RadioLow
 SG_ CustMdRideHghtCstmAvFlg4 : 38|1@0+ (1,0) [0|1] "" CSM,RadioLow
 SG_ CustMdRideHghtCstmAvFlg3 : 39|1@0+ (1,0) [0|1] "" CSM,RadioLow
 SG_ CustMdSpnCstmAvFlg4 : 40|1@0+ (1,0) [0|1] "" CSM,RadioLow,TCP
 SG_ CustMdSpnCstmAvFlg3 : 41|1@0+ (1,0) [0|1] "" CSM,RadioLow,TCP
 SG_ CustMdSpnCstmAvFlg2 : 42|1@0+ (1,0) [0|1] "" CSM,RadioLow,TCP
 SG_ CustMdSpnCstmAvFlg1 : 43|1@0+ (1,0) [0|1] "" CSM,RadioLow,TCP
 SG_ CustMdSndCstmAvFlg7 : 44|1@0+ (1,0) [0|1] "" CSM,RadioLow
 SG_ CustMdSndCstmAvFlg6 : 45|1@0+ (1,0) [0|1] "" CSM,RadioLow
 SG_ CustMdSndCstmAvFlg5 : 46|1@0+ (1,0) [0|1] "" CSM,RadioLow
 SG_ CustMdSndCstmAvFlg4 : 47|1@0+ (1,0) [0|1] "" CSM,RadioLow
 SG_ CustMdStrCstmAvFlg5 : 48|1@0+ (1,0) [0|1] "" CSM,RadioLow,TCP
 SG_ CustMdStrCstmAvFlg4 : 49|1@0+ (1,0) [0|1] "" CSM,RadioLow,TCP
 SG_ CustMdStrCstmAvFlg3 : 50|1@0+ (1,0) [0|1] "" CSM,RadioLow,TCP
 SG_ CustMdStrCstmAvFlg2 : 51|1@0+ (1,0) [0|1] "" CSM,RadioLow,TCP
 SG_ CustMdStrCstmAvFlg1 : 52|1@0+ (1,0) [0|1] "" CSM,RadioLow,TCP
 SG_ CustMdSpnCstmAvFlg7 : 53|1@0+ (1,0) [0|1] "" CSM,RadioLow,TCP
 SG_ CustMdSpnCstmAvFlg6 : 54|1@0+ (1,0) [0|1] "" CSM,RadioLow,TCP
 SG_ CustMdSpnCstmAvFlg5 : 55|1@0+ (1,0) [0|1] "" CSM,RadioLow,TCP
 SG_ CustMdStrCstmAvFlg7 : 62|1@0+ (1,0) [0|1] "" CSM,RadioLow,TCP
 SG_ CustMdStrCstmAvFlg6 : 63|1@0+ (1,0) [0|1] "" CSM,RadioLow,TCP

BA_DEF_ SG_  "SignalType" STRING ;
BA_DEF_ SG_  "SignalLongName" STRING ;
BA_DEF_ BO_  "GenMsgCycleTime" INT 0 10000;
BA_DEF_ BO_  "GenMsgSendType" ENUM "cyclicX","spontanX","cyclicIfActiveX","spontanWithDelay","cyclicAndSpontanX","cyclicAndSpontanWithDelay","spontanWithRepetition","cyclicIfActiveAndSpontanWD";
BA_DEF_DEF_  "SignalType" "";
BA_DEF_DEF_  "SignalLongName" "";
BA_DEF_DEF_  "GenMsgCycleTime" 0;
BA_DEF_DEF_  "GenMsgSendType" "cyclicX";
BA_ "GenMsgCycleTime" BO_ 1342 1000;
BA_ "GenMsgCycleTime" BO_ 1083 250;
BA_ "GenMsgCycleTime" BO_ 56 12.5;
BA_ "GenMsgCycleTime" BO_ 1052 250;
BA_ "GenMsgCycleTime" BO_ 591 250;
BA_ "GenMsgCycleTime" BO_ 55 12.5;
BA_ "GenMsgCycleTime" BO_ 1812 3500;
BA_ "GenMsgCycleTime" BO_ 1074 1000;
BA_ "GenMsgCycleTime" BO_ 1813 3500;
BA_ "GenMsgCycleTime" BO_ 1075 1000;
BA_ "GenMsgCycleTime" BO_ 1814 3500;
BA_ "GenMsgCycleTime" BO_ 1076 1000;
BA_ "GenMsgCycleTime" BO_ 605 250;
BA_ "GenMsgCycleTime" BO_ 1795 3500;
BA_ "GenMsgCycleTime" BO_ 1031 1000;
BA_ "GenMsgCycleTime" BO_ 617 100;
BA_ "GenMsgCycleTime" BO_ 618 100;
BA_ "GenMsgCycleTime" BO_ 619 100;
BA_ "GenMsgCycleTime" BO_ 620 100;
BA_ "GenMsgCycleTime" BO_ 1168 1000;
BA_ "GenMsgCycleTime" BO_ 1231 1000;
BA_ "GenMsgCycleTime" BO_ 1305 1000;
BA_ "GenMsgCycleTime" BO_ 1264 1000;
BA_ "GenMsgCycleTime" BO_ 1232 1000;
BA_ "GenMsgCycleTime" BO_ 1202 1000;
BA_ "GenMsgCycleTime" BO_ 1203 1000;
BA_ "GenMsgCycleTime" BO_ 1337 100;
BA_ "GenMsgCycleTime" BO_ 1204 1000;
BA_ "GenMsgCycleTime" BO_ 1306 1000;
BA_ "GenMsgCycleTime" BO_ 1205 1000;
BA_ "GenMsgCycleTime" BO_ 1233 1000;
BA_ "GenMsgCycleTime" BO_ 607 100;
BA_ "GenMsgCycleTime" BO_ 1270 1000;
BA_ "GenMsgCycleTime" BO_ 1234 1000;
BA_ "GenMsgCycleTime" BO_ 1235 1000;
BA_ "GenMsgCycleTime" BO_ 1169 1000;
BA_ "GenMsgCycleTime" BO_ 1170 1000;
BA_ "GenMsgCycleTime" BO_ 1195 1000;
BA_ "GenMsgCycleTime" BO_ 1196 1000;
BA_ "GenMsgCycleTime" BO_ 1171 1000;
BA_ "GenMsgCycleTime" BO_ 1350 1000;
BA_ "GenMsgCycleTime" BO_ 1206 1000;
BA_ "GenMsgCycleTime" BO_ 1207 1000;
BA_ "GenMsgCycleTime" BO_ 1173 1000;
BA_ "GenMsgCycleTime" BO_ 1174 1000;
BA_ "SignalLongName" SG_ 1342 DTCI_WCM_DTCFailType "Diagnostic Trouble Code Information Extended - WCM : Diagnostic Trouble Code Failure Type";
BA_ "SignalType" SG_ 1342 DTCI_WCM_CnfrmdDTC "ENM";
BA_ "SignalLongName" SG_ 1342 DTCI_WCM_CnfrmdDTC "Diagnostic Trouble Code Information Extended - WCM : Confirmed DTC";
BA_ "SignalType" SG_ 1342 DTCI_WCM_DTCFaultType "ENM";
BA_ "SignalLongName" SG_ 1342 DTCI_WCM_DTCFaultType "Diagnostic Trouble Code Information Extended - WCM : Diagnostic Trouble Code Fault Type";
BA_ "SignalLongName" SG_ 1342 DTCI_WCM_DTCNumber "Diagnostic Trouble Code Information Extended - WCM : Diagnostic Trouble Code Number";
BA_ "SignalLongName" SG_ 1342 DTCI_WCM_DTCSource "Diagnostic Trouble Code Information Extended - WCM : Diagnostic Trouble Code Source";
BA_ "SignalType" SG_ 1342 DTCI_WCM_TstNCmpltdOpCyc "ENM";
BA_ "SignalLongName" SG_ 1342 DTCI_WCM_TstNCmpltdOpCyc "Diagnostic Trouble Code Information Extended - WCM : Test Not Completed This Operation Cycle";
BA_ "SignalType" SG_ 1342 DTCI_WCM_TstNCmpltdLstClr "ENM";
BA_ "SignalLongName" SG_ 1342 DTCI_WCM_TstNCmpltdLstClr "Diagnostic Trouble Code Information Extended - WCM : Test Not Completed Since Last Clear";
BA_ "SignalType" SG_ 1342 DTCI_WCM_TstFldOpCyc "ENM";
BA_ "SignalLongName" SG_ 1342 DTCI_WCM_TstFldOpCyc "Diagnostic Trouble Code Information Extended - WCM : Test Failed This Operation Cycle";
BA_ "SignalType" SG_ 1342 DTCI_WCM_TstFldLstClr "ENM";
BA_ "SignalLongName" SG_ 1342 DTCI_WCM_TstFldLstClr "Diagnostic Trouble Code Information Extended - WCM : Test Failed Since Last Clear";
BA_ "SignalType" SG_ 1342 DTCI_WCM_TstFld "ENM";
BA_ "SignalLongName" SG_ 1342 DTCI_WCM_TstFld "Diagnostic Trouble Code Information Extended - WCM : Test Failed";
BA_ "SignalType" SG_ 1342 DTCI_WCM_PndngDTC "ENM";
BA_ "SignalLongName" SG_ 1342 DTCI_WCM_PndngDTC "Diagnostic Trouble Code Information Extended - WCM : Pending DTC";
BA_ "SignalType" SG_ 1342 DTCI_WCM_DTCTriggered "ENM";
BA_ "SignalLongName" SG_ 1342 DTCI_WCM_DTCTriggered "Diagnostic Trouble Code Information Extended - WCM : Diagnostic Trouble Code Triggered";
BA_ "SignalType" SG_ 1342 DTCI_WCM_WrnIndTrggrd "ENM";
BA_ "SignalLongName" SG_ 1342 DTCI_WCM_WrnIndTrggrd "Diagnostic Trouble Code Information Extended - WCM : Warning Indicator Triggered";
BA_ "SignalType" SG_ 1342 DTCI_WCM_WrnIndRqd "ENM";
BA_ "SignalLongName" SG_ 1342 DTCI_WCM_WrnIndRqd "Diagnostic Trouble Code Information Extended - WCM : Warning Indicator Requested";
BA_ "SignalLongName" SG_ 1085 DrvlnDispInfo_PCSM "Driveline Display Information Protected Counter Sync Message";
BA_ "SignalLongName" SG_ 1083 DDIP_MAC "Driveline Display Information Protected : MAC";
BA_ "SignalLongName" SG_ 1083 DDIP_FCnt "Driveline Display Information Protected : Freshness Counter";
BA_ "SignalLongName" SG_ 1083 DDIP_ARC "Driveline Display Information Protected : Alive Rolling Count";
BA_ "SignalType" SG_ 1083 DDIP_SecAxl4WDAWDNonEmMlfIOAuth "ENM";
BA_ "SignalLongName" SG_ 1083 DDIP_SecAxl4WDAWDNonEmMlfIOAuth "Driveline Display Information Protected : Secondary Axle 4WD AWD Non emissions Malfunction Indication On Authenticated";
BA_ "SignalType" SG_ 1083 DDIP_SecAxl4WDAWDTmpInhbIOAuth "ENM";
BA_ "SignalLongName" SG_ 1083 DDIP_SecAxl4WDAWDTmpInhbIOAuth "Driveline Display Information Protected : Secondary Axle 4WD AWD Temporary Inhibit Indication On Authenticated";
BA_ "SignalType" SG_ 1083 DDIP_4AndAllWhlDrvIndReqAuth "ENM";
BA_ "SignalLongName" SG_ 1083 DDIP_4AndAllWhlDrvIndReqAuth "Driveline Display Information Protected : Four and All Wheel Drive Indication Request Authenticated";
BA_ "SignalLongName" SG_ 56 ElecMtrASpd "Electric Motor A Speed";
BA_ "SignalType" SG_ 56 ElecMtrASpd_Inv "ENM";
BA_ "SignalLongName" SG_ 56 ElecMtrASpd_Inv "Electric Motor A Speed Invalid";
BA_ "SignalLongName" SG_ 56 ElecMtrATrqAchvd "Electric Motor A Torque Achieved";
BA_ "SignalLongName" SG_ 1056 ElecShftRngSecDisp_PCSM "Electronic Shift Range Secondary Display Protected Counter Sync Message";
BA_ "SignalLongName" SG_ 1052 ESRSDP_MAC "Electronic Shift Range Secondary Display Protected : MAC";
BA_ "SignalLongName" SG_ 1052 ESRSDP_FCnt "Electronic Shift Range Secondary Display Protected : Freshness Counter";
BA_ "SignalLongName" SG_ 1052 ESRSDP_ARC "Electronic Shift Range Secondary Display Protected : Alive Rolling Count";
BA_ "SignalType" SG_ 1052 ESRSDP_ElecShftRngSecDispAuth "ENM";
BA_ "SignalLongName" SG_ 1052 ESRSDP_ElecShftRngSecDispAuth "Electronic Shift Range Secondary Display Protected : Electronic Shift Range Secondary Display Authenticated";
BA_ "SignalLongName" SG_ 592 ElecStrgColLck_PCSM "Electric Steering Column Lock Protected Counter Sync Message";
BA_ "SignalLongName" SG_ 591 ESCLP_MAC "Electric Steering Column Lock Protected : MAC";
BA_ "SignalLongName" SG_ 591 ESCLP_FCnt "Electric Steering Column Lock Protected : Freshness Counter";
BA_ "SignalLongName" SG_ 591 ESCLP_ARC "Electric Steering Column Lock Protected : Alive Rolling Count";
BA_ "SignalType" SG_ 591 ESCLP_StrgColLckdIndOnAuth "ENM";
BA_ "SignalLongName" SG_ 591 ESCLP_StrgColLckdIndOnAuth "Electric Steering Column Lock Protected : Steering Column Locked Indication On Authenticated";
BA_ "SignalType" SG_ 591 ESCLP_ServColLckIndOnAuth "ENM";
BA_ "SignalLongName" SG_ 591 ESCLP_ServColLckIndOnAuth "Electric Steering Column Lock Protected : Service Column Lock Indication On Authenticated";
BA_ "SignalType" SG_ 591 ESCLP_ElecStrgColLckStsAuth "ENM";
BA_ "SignalLongName" SG_ 591 ESCLP_ElecStrgColLckStsAuth "Electric Steering Column Lock Protected : Electric Steering Column Lock Status Authenticated";
BA_ "SignalLongName" SG_ 55 EngActStdyStTrq "Engine Actual Steady State Torque";
BA_ "SignalType" SG_ 55 EngActStdyStTrq_Inv "ENM";
BA_ "SignalLongName" SG_ 55 EngActStdyStTrq_Inv "Engine Actual Steady State Torque Invalid";
BA_ "SignalLongName" SG_ 55 ArbdEngTemp "Arbitrated Engine Temperature";
BA_ "SignalType" SG_ 55 DslGlwPlgIO "ENM";
BA_ "SignalLongName" SG_ 55 DslGlwPlgIO "Diesel Glow Plug Indication On";
BA_ "SignalType" SG_ 55 ArbdEngTemp_Inv "ENM";
BA_ "SignalLongName" SG_ 55 ArbdEngTemp_Inv "Arbitrated Engine Temperature Invalid";
BA_ "SignalLongName" SG_ 1812 EngIdleActvTm_PCSM "Engine Idle Active Time Protected Counter Sync Message";
BA_ "SignalLongName" SG_ 1074 EIATP_MAC "Engine Idle Active Time Protected : MAC";
BA_ "SignalLongName" SG_ 1074 EIATP_Fcnt "Engine Idle Active Time Protected : Freshness Counter";
BA_ "SignalLongName" SG_ 1074 EIATP_EngIdleActvTmAuth "Engine Idle Active Time Protected : Engine Idle Active Time Authenticated";
BA_ "SignalLongName" SG_ 1813 EngLifetmRotns_PCSM "Engine Life time Rotations Protected Counter Sync Message";
BA_ "SignalLongName" SG_ 1075 ELRP_MAC "Engine Life time Rotations Protected : MAC";
BA_ "SignalLongName" SG_ 1075 ELRP_Fcnt "Engine Life time Rotations Protected : Freshness Counter";
BA_ "SignalLongName" SG_ 1075 ELRP_EngLifetmRotnsAuth "Engine Life time Rotations Protected : Engine Life time Rotations Authenticated";
BA_ "SignalLongName" SG_ 1814 EngRunActvTm_PCSM "Engine Run Active Time Protected Counter Sync Message";
BA_ "SignalLongName" SG_ 1076 ERATP_MAC "Engine Run Active Time Protected : MAC";
BA_ "SignalLongName" SG_ 1076 ERATP_Fcnt "Engine Run Active Time Protected : Freshness Counter";
BA_ "SignalLongName" SG_ 1076 ERATP_EngRunActvTmAuth "Engine Run Active Time Protected : Engine Run Active Time Authenticated";
BA_ "SignalLongName" SG_ 1817 EnhdSrvsVhTpSp_PCSM "Enhanced Services Vehicle Top Speed Protected Counter Sync Message";
BA_ "SignalLongName" SG_ 605 ESVTSP_MAC "Enhanced Services Vehicle Top Speed Protected : MAC";
BA_ "SignalLongName" SG_ 605 ESVTSP_FCnt "Enhanced Services Vehicle Top Speed Protected : Freshness Counter";
BA_ "SignalLongName" SG_ 605 ESVTSP_EnhdSrvsVhTpSpLimValAuth "Enhanced Services Vehicle Top Speed Protected : Enhanced Services Vehicle Top Speed Limit Value Authenticated";
BA_ "SignalLongName" SG_ 605 ESVTSP_ARC "Enhanced Services Vehicle Top Speed Protected : Alive Rolling Count";
BA_ "SignalType" SG_ 605 ESVTSP_EnhdSrvsVhTpSpLimReqAuth "ENM";
BA_ "SignalLongName" SG_ 605 ESVTSP_EnhdSrvsVhTpSpLimReqAuth "Enhanced Services Vehicle Top Speed Protected : Enhanced Services Vehicle Top Speed Limit Request Authenticated";
BA_ "SignalLongName" SG_ 1795 FrtTirePrs_PCSM "Front Tire Pressure Protected Counter Sync Message";
BA_ "SignalLongName" SG_ 1031 FTPP_MAC "Front Tire Pressure Protected : MAC";
BA_ "SignalLongName" SG_ 1031 FTPP_FCnt "Front Tire Pressure Protected : Freshness Counter";
BA_ "SignalLongName" SG_ 1031 FTPP_TirePrsRFAuth "Front Tire Pressure Protected : Tire Pressure Right Front Authenticated";
BA_ "SignalType" SG_ 1031 FTPP_FrtCmptAjrWrnIndOnAuth "ENM";
BA_ "SignalLongName" SG_ 1031 FTPP_FrtCmptAjrWrnIndOnAuth "Front Tire Pressure Protected : Front Compartment Ajar Warning Indication On Authenticated";
BA_ "SignalType" SG_ 1031 FTPP_FrtCmptFaildToOpnIndOnAuth "ENM";
BA_ "SignalLongName" SG_ 1031 FTPP_FrtCmptFaildToOpnIndOnAuth "Front Tire Pressure Protected : Front Compartment Failed to Open Indication On Authenticated";
BA_ "SignalLongName" SG_ 1031 FTPP_TirePrsLFAuth "Front Tire Pressure Protected : Tire Pressure Left Front Authenticated";
BA_ "SignalType" SG_ 1031 FTPP_TirePresLoIndOnAuth "ENM";
BA_ "SignalLongName" SG_ 1031 FTPP_TirePresLoIndOnAuth "Front Tire Pressure Protected : Tire Pressure Low Indication On Authenticated";
BA_ "SignalType" SG_ 1031 FTPP_TirePrsRFAuth_Inv "ENM";
BA_ "SignalLongName" SG_ 1031 FTPP_TirePrsRFAuth_Inv "Front Tire Pressure Protected : Tire Pressure Right Front Authenticated Invalid";
BA_ "SignalType" SG_ 1031 FTPP_TirePrsLFAuth_Inv "ENM";
BA_ "SignalLongName" SG_ 1031 FTPP_TirePrsLFAuth_Inv "Front Tire Pressure Protected : Tire Pressure Left Front Authenticated Invalid";
BA_ "SignalLongName" SG_ 1031 FTPP_ARC "Front Tire Pressure Protected : Alive Rolling Count";
BA_ "SignalType" SG_ 1031 FTPP_ServWprSysCtlIndOnAuth "ENM";
BA_ "SignalLongName" SG_ 1031 FTPP_ServWprSysCtlIndOnAuth "Front Tire Pressure Protected : Service Wiper System Control Indication On Authenticated";
BA_ "SignalType" SG_ 617 GPSQM_PPSAbsVelErrEst_Inv "ENM";
BA_ "SignalLongName" SG_ 617 GPSQM_PPSAbsVelErrEst_Inv "Global Positioning System Quality Metrics : Precise Positioning System Absolute Velocity Error Estimate Invalid";
BA_ "SignalLongName" SG_ 617 GPSQM_PPSAbsHdgErrEst "Global Positioning System Quality Metrics : Precise Positioning System Absolute Heading Error Estimate";
BA_ "SignalLongName" SG_ 617 GPSQM_PPSPstnDilutnPrcsn "Global Positioning System Quality Metrics : Precise Positioning System Position Dilution of Precision";
BA_ "SignalLongName" SG_ 617 GPSQM_PPSAbsVelErrEst "Global Positioning System Quality Metrics : Precise Positioning System Absolute Velocity Error Estimate";
BA_ "SignalType" SG_ 617 GPSQM_PPSMode "ENM";
BA_ "SignalLongName" SG_ 617 GPSQM_PPSMode "Global Positioning System Quality Metrics : Precise Positioning System Mode";
BA_ "SignalType" SG_ 617 GPSQM_PPSPstnDilutnPrcsn_Inv "ENM";
BA_ "SignalLongName" SG_ 617 GPSQM_PPSPstnDilutnPrcsn_Inv "Global Positioning System Quality Metrics : Precise Positioning System Position Dilution of Precision Invalid";
BA_ "SignalLongName" SG_ 617 GPSQM_PPS2DAbsPstnErrEst "Global Positioning System Quality Metrics : Precise Positioning System 2D Absolute Position Error Estimate";
BA_ "SignalLongName" SG_ 617 GPSQM_PPS3DAbsPstnErrEst "Global Positioning System Quality Metrics : Precise Positioning System 3D Absolute Position Error Estimate";
BA_ "SignalType" SG_ 617 GPSQM_PPS2DAbsPstnErrEst_Inv "ENM";
BA_ "SignalLongName" SG_ 617 GPSQM_PPS2DAbsPstnErrEst_Inv "Global Positioning System Quality Metrics : Precise Positioning System 2D Absolute Position Error Estimate Invalid";
BA_ "SignalType" SG_ 617 GPSQM_PPSMode_Inv "ENM";
BA_ "SignalLongName" SG_ 617 GPSQM_PPSMode_Inv "Global Positioning System Quality Metrics : Precise Positioning System Mode Invalid";
BA_ "SignalType" SG_ 617 GPSQM_PPS3DAbsPstnErrEst_Inv "ENM";
BA_ "SignalLongName" SG_ 617 GPSQM_PPS3DAbsPstnErrEst_Inv "Global Positioning System Quality Metrics : Precise Positioning System 3D Absolute Position Error Estimate Invalid";
BA_ "SignalLongName" SG_ 618 GPSC_PPSLat "Global Positioning System Coordinates : Precise Positioning System Latitude";
BA_ "SignalLongName" SG_ 618 GPSC_PPSLong "Global Positioning System Coordinates : Precise Positioning System Longitude";
BA_ "SignalType" SG_ 618 GPSC_PPSLat_Inv "ENM";
BA_ "SignalLongName" SG_ 618 GPSC_PPSLat_Inv "Global Positioning System Coordinates : Precise Positioning System Latitude Invalid";
BA_ "SignalType" SG_ 618 GPSC_PPSLong_Inv "ENM";
BA_ "SignalLongName" SG_ 618 GPSC_PPSLong_Inv "Global Positioning System Coordinates : Precise Positioning System Longitude Invalid";
BA_ "SignalLongName" SG_ 619 GPST_PPSTmOfDy "Global Positioning System Time : Precise Positioning System Time of Day";
BA_ "SignalLongName" SG_ 619 GPST_PPSCldrYr "Global Positioning System Time : Precise Positioning System Calendar Year";
BA_ "SignalLongName" SG_ 619 GPST_PPSCldrDy "Global Positioning System Time : Precise Positioning System Calendar Day";
BA_ "SignalType" SG_ 619 GPST_PPSCldrYr_Inv "ENM";
BA_ "SignalLongName" SG_ 619 GPST_PPSCldrYr_Inv "Global Positioning System Time : Precise Positioning System Calendar Year Invalid";
BA_ "SignalType" SG_ 619 GPST_PPSCldrDy_Inv "ENM";
BA_ "SignalLongName" SG_ 619 GPST_PPSCldrDy_Inv "Global Positioning System Time : Precise Positioning System Calendar Day Invalid";
BA_ "SignalType" SG_ 619 GPST_PPSTmOfDy_Inv "ENM";
BA_ "SignalLongName" SG_ 619 GPST_PPSTmOfDy_Inv "Global Positioning System Time : Precise Positioning System Time of Day Invalid";
BA_ "SignalLongName" SG_ 620 GPSV_PPSElvtn "Global Positioning System Velocity : Precise Positioning System Elevation";
BA_ "SignalType" SG_ 620 GPSV_PPSElvtn_Inv "ENM";
BA_ "SignalLongName" SG_ 620 GPSV_PPSElvtn_Inv "Global Positioning System Velocity : Precise Positioning System Elevation Invalid";
BA_ "SignalType" SG_ 620 GPSV_PPSCalcdSpd_Inv "ENM";
BA_ "SignalLongName" SG_ 620 GPSV_PPSCalcdSpd_Inv "Global Positioning System Velocity : Precise Positioning System Calculated Speed Invalid";
BA_ "SignalType" SG_ 620 GPSV_PPSHdg_Inv "ENM";
BA_ "SignalLongName" SG_ 620 GPSV_PPSHdg_Inv "Global Positioning System Velocity : Precise Positioning System Heading Invalid";
BA_ "SignalLongName" SG_ 620 GPSV_PPSCalcdSpd "Global Positioning System Velocity : Precise Positioning System Calculated Speed";
BA_ "SignalLongName" SG_ 620 GPSV_PPSHdg "Global Positioning System Velocity : Precise Positioning System Heading";
BA_ "SignalType" SG_ 1168 FrtRdHgtGPSCstAvlbltyFlg7 "ENM";
BA_ "SignalLongName" SG_ 1168 FrtRdHgtGPSCstAvlbltyFlg7 "Front Ride Height GPS Customization Availability Flag 7";
BA_ "SignalType" SG_ 1168 FrtRdHgtGPSCstAvlbltyFlg6 "ENM";
BA_ "SignalLongName" SG_ 1168 FrtRdHgtGPSCstAvlbltyFlg6 "Front Ride Height GPS Customization Availability Flag 6";
BA_ "SignalType" SG_ 1168 FrtRdHgtGPSCstAvlbltyFlg5 "ENM";
BA_ "SignalLongName" SG_ 1168 FrtRdHgtGPSCstAvlbltyFlg5 "Front Ride Height GPS Customization Availability Flag 5";
BA_ "SignalType" SG_ 1168 FrtRdHgtGPSCstAvlbltyFlg4 "ENM";
BA_ "SignalLongName" SG_ 1168 FrtRdHgtGPSCstAvlbltyFlg4 "Front Ride Height GPS Customization Availability Flag 4";
BA_ "SignalType" SG_ 1168 FrtRdHgtGPSCstAvlbltyFlg3 "ENM";
BA_ "SignalLongName" SG_ 1168 FrtRdHgtGPSCstAvlbltyFlg3 "Front Ride Height GPS Customization Availability Flag 3";
BA_ "SignalType" SG_ 1168 FrtRdHgtGPSCstAvlbltyFlg2 "ENM";
BA_ "SignalLongName" SG_ 1168 FrtRdHgtGPSCstAvlbltyFlg2 "Front Ride Height GPS Customization Availability Flag 2";
BA_ "SignalType" SG_ 1168 FrtRdHgtGPSCstAvlbltyFlg1 "ENM";
BA_ "SignalLongName" SG_ 1168 FrtRdHgtGPSCstAvlbltyFlg1 "Front Ride Height GPS Customization Availability Flag 1";
BA_ "SignalLongName" SG_ 1231 APAWI_MnvrPrgs "Advanced Park Assist Warning Indications : Advanced Park Assist Maneuver Progress";
BA_ "SignalType" SG_ 1231 APAWI_WrnIndReq "ENM";
BA_ "SignalLongName" SG_ 1231 APAWI_WrnIndReq "Advanced Park Assist Warning Indications : Advanced Park Assist Warning Indication Request";
BA_ "SignalType" SG_ 1231 APAWI_AutoStrgIconReq "ENM";
BA_ "SignalLongName" SG_ 1231 APAWI_AutoStrgIconReq "Advanced Park Assist Warning Indications : Advanced Park Assist Auto Steering Icon Request";
BA_ "SignalType" SG_ 1231 APAWI_FcsReq "ENM";
BA_ "SignalLongName" SG_ 1231 APAWI_FcsReq "Advanced Park Assist Warning Indications : Advanced Park Assist Focus Request";
BA_ "SignalType" SG_ 1231 APALftSftBtnRqst "ENM";
BA_ "SignalLongName" SG_ 1231 APALftSftBtnRqst "Advanced Park Assist Left Soft Button Request";
BA_ "SignalType" SG_ 1231 APAExtPrkSftBtnRqst "ENM";
BA_ "SignalLongName" SG_ 1231 APAExtPrkSftBtnRqst "Advanced Park Assist Exit Park Soft Button Request";
BA_ "SignalType" SG_ 1231 APACrssFrntInSftBtnRqst "ENM";
BA_ "SignalLongName" SG_ 1231 APACrssFrntInSftBtnRqst "Advanced Park Assist Cross Front-In Soft Button Reques";
BA_ "SignalType" SG_ 1231 APACrssBckInSftBtnRqst "ENM";
BA_ "SignalLongName" SG_ 1231 APACrssBckInSftBtnRqst "Advanced Park Assist Cross Back-In Soft Button Request";
BA_ "SignalType" SG_ 1231 APAVMR_NAvalIndOn "ENM";
BA_ "SignalLongName" SG_ 1231 APAVMR_NAvalIndOn "Advanced Park Assist Visual Message Requests : Advanced Park Assist Not Available Indication On";
BA_ "SignalType" SG_ 1231 APAVMR_SloDnIndOn "ENM";
BA_ "SignalLongName" SG_ 1231 APAVMR_SloDnIndOn "Advanced Park Assist Visual Message Requests : Advanced Park Assist Slow Down Indication On";
BA_ "SignalType" SG_ 1231 APASrchSftBtnRqst "ENM";
BA_ "SignalLongName" SG_ 1231 APASrchSftBtnRqst "Advanced Park Assist Searching Soft Button Request";
BA_ "SignalType" SG_ 1231 APARghtSftBtnRqst "ENM";
BA_ "SignalLongName" SG_ 1231 APARghtSftBtnRqst "Advanced Park Assist Right Soft Button Request";
BA_ "SignalType" SG_ 1231 APAPrllPrkSftBtnRqst "ENM";
BA_ "SignalLongName" SG_ 1231 APAPrllPrkSftBtnRqst "Advanced Park Assist Parallel Parking Soft Button Request";
BA_ "SignalLongName" SG_ 1305 DuctAirTempRrFloorRwVltg "Duct Air Temperature Rear Floor Raw Voltage";
BA_ "SignalLongName" SG_ 1305 DuctAirTempRrRtFloorRwVltg "Duct Air Temperature Rear Right Floor Raw Voltage";
BA_ "SignalLongName" SG_ 1305 DuctAirTempRrRtVntRwVltg "Duct Air Temperature Rear Right Vent Raw Voltage";
BA_ "SignalLongName" SG_ 1305 DuctAirTempRrVntRwVltg "Duct Air Temperature Rear Vent Raw Voltage";
BA_ "SignalLongName" SG_ 1305 ClmCtlRrBlwFanSpdPWMFreq "Climate Control Rear Blower Fan Speed PWM Frequency";
BA_ "SignalLongName" SG_ 1264 ICSTS_X1TchCrdnt "Integrated Center Stack Touch Status : X1 Touch Coordinate";
BA_ "SignalLongName" SG_ 1264 ICSTS_Y1TchCrdnt "Integrated Center Stack Touch Status : Y1 Touch Coordinate";
BA_ "SignalLongName" SG_ 1264 HtchPtLgth "Hitching Point Length";
BA_ "SignalType" SG_ 1232 DM2Name "ENM";
BA_ "SignalLongName" SG_ 1232 DM2Name "Drive Mode 2 Name";
BA_ "SignalType" SG_ 1232 DM1Name "ENM";
BA_ "SignalLongName" SG_ 1232 DM1Name "Drive Mode 1 Name";
BA_ "SignalType" SG_ 1232 DM4Name "ENM";
BA_ "SignalLongName" SG_ 1232 DM4Name "Drive Mode 4 Name";
BA_ "SignalType" SG_ 1232 DM3Name "ENM";
BA_ "SignalLongName" SG_ 1232 DM3Name "Drive Mode 3 Name";
BA_ "SignalType" SG_ 1232 DM5Name "ENM";
BA_ "SignalLongName" SG_ 1232 DM5Name "Drive Mode 5 Name";
BA_ "SignalType" SG_ 1232 DM7Name "ENM";
BA_ "SignalLongName" SG_ 1232 DM7Name "Drive Mode 7 Name";
BA_ "SignalType" SG_ 1232 DM6Name "ENM";
BA_ "SignalLongName" SG_ 1232 DM6Name "Drive Mode 6 Name";
BA_ "SignalType" SG_ 1232 DM8Name "ENM";
BA_ "SignalLongName" SG_ 1232 DM8Name "Drive Mode 8 Name";
BA_ "SignalType" SG_ 1232 DM6Status "ENM";
BA_ "SignalLongName" SG_ 1232 DM6Status "Drive Mode 6 Status";
BA_ "SignalType" SG_ 1232 DM5Status "ENM";
BA_ "SignalLongName" SG_ 1232 DM5Status "Drive Mode 5 Status";
BA_ "SignalType" SG_ 1232 DM4Status "ENM";
BA_ "SignalLongName" SG_ 1232 DM4Status "Drive Mode 4 Status";
BA_ "SignalType" SG_ 1232 DM3Status "ENM";
BA_ "SignalLongName" SG_ 1232 DM3Status "Drive Mode 3 Status";
BA_ "SignalType" SG_ 1232 DM2Status "ENM";
BA_ "SignalLongName" SG_ 1232 DM2Status "Drive Mode 2 Status";
BA_ "SignalType" SG_ 1232 DM1Status "ENM";
BA_ "SignalLongName" SG_ 1232 DM1Status "Drive Mode 1 Status";
BA_ "SignalType" SG_ 1232 EngCmptAjr "ENM";
BA_ "SignalLongName" SG_ 1232 EngCmptAjr "Engine Compartment Ajar";
BA_ "SignalType" SG_ 1232 EngCmptAjr_Inv "ENM";
BA_ "SignalLongName" SG_ 1232 EngCmptAjr_Inv "Engine Compartment Ajar Invalid";
BA_ "SignalType" SG_ 1232 FrtStrgeCmptAjr "ENM";
BA_ "SignalLongName" SG_ 1232 FrtStrgeCmptAjr "Front Storage Compartment Ajar";
BA_ "SignalType" SG_ 1232 DM8Status "ENM";
BA_ "SignalLongName" SG_ 1232 DM8Status "Drive Mode 8 Status";
BA_ "SignalType" SG_ 1232 DM7Status "ENM";
BA_ "SignalLongName" SG_ 1232 DM7Status "Drive Mode 7 Status";
BA_ "SignalLongName" SG_ 1202 BrkPadLifeFrt "Brake Pad Life Front";
BA_ "SignalType" SG_ 1202 BrkPadLifeFrt_Inv "ENM";
BA_ "SignalLongName" SG_ 1202 BrkPadLifeFrt_Inv "Brake Pad Life Front Invalid";
BA_ "SignalLongName" SG_ 1202 BrkPadLifeRr "Brake Pad Life Rear";
BA_ "SignalType" SG_ 1202 BrkPadLifeRr_Inv "ENM";
BA_ "SignalLongName" SG_ 1202 BrkPadLifeRr_Inv "Brake Pad Life Rear Invalid";
BA_ "SignalType" SG_ 1202 ElecPrkBrkSysDisIndReq "ENM";
BA_ "SignalLongName" SG_ 1202 ElecPrkBrkSysDisIndReq "Electric Park Brake System Display Indication Request";
BA_ "SignalType" SG_ 1202 EPBStpOnBrkToRelPrkBrkIndReq "ENM";
BA_ "SignalLongName" SG_ 1202 EPBStpOnBrkToRelPrkBrkIndReq "Electric Park Brake Step On Brake To Release Park Brake Indication Request";
BA_ "SignalType" SG_ 1202 BrkPadLifeStsIndReq "ENM";
BA_ "SignalLongName" SG_ 1202 BrkPadLifeStsIndReq "Brake Pad Life Status Indication Request";
BA_ "SignalType" SG_ 1202 AutoHldDsbldDrOpnIndOn "ENM";
BA_ "SignalLongName" SG_ 1202 AutoHldDsbldDrOpnIndOn "Auto Hold Disabled Door Open Indication On";
BA_ "SignalType" SG_ 1202 AutoHldAppBrkPedIndOn "ENM";
BA_ "SignalLongName" SG_ 1202 AutoHldAppBrkPedIndOn "Auto Hold Apply Brake Pedal Indication On";
BA_ "SignalType" SG_ 1202 AutoHldActv "ENM";
BA_ "SignalLongName" SG_ 1202 AutoHldActv "Auto Hold Active";
BA_ "SignalType" SG_ 1202 ABSActvIndOn "ENM";
BA_ "SignalLongName" SG_ 1202 ABSActvIndOn "Antilock Braking System Active Indication On";
BA_ "SignalType" SG_ 1202 PerfMdMainMenuTy "ENM";
BA_ "SignalLongName" SG_ 1202 PerfMdMainMenuTy "Performance Mode Main Menu Type";
BA_ "SignalType" SG_ 1202 ESCOffIO "ENM";
BA_ "SignalLongName" SG_ 1202 ESCOffIO "Electronic Stability Control Off Indication On";
BA_ "SignalType" SG_ 1202 ESCInitIO "ENM";
BA_ "SignalLongName" SG_ 1202 ESCInitIO "Electronic Stability Control Initializing Indication On";
BA_ "SignalType" SG_ 1202 ESCCmptMdIO "ENM";
BA_ "SignalLongName" SG_ 1202 ESCCmptMdIO "ElectronicStabilityControlCompetitiveModeIndicationOn";
BA_ "SignalType" SG_ 1202 BrkPadWrnIO "ENM";
BA_ "SignalLongName" SG_ 1202 BrkPadWrnIO "Brake Pad Worn Indication On";
BA_ "SignalType" SG_ 1202 BrkPadLifeRrRstAval "ENM";
BA_ "SignalLongName" SG_ 1202 BrkPadLifeRrRstAval "Brake Pad Life Rear Reset Available";
BA_ "SignalType" SG_ 1202 BrkPadLifeFrtRstAval "ENM";
BA_ "SignalLongName" SG_ 1202 BrkPadLifeFrtRstAval "Brake Pad Life Front Reset Available";
BA_ "SignalType" SG_ 1202 AutoHldServIndOn "ENM";
BA_ "SignalLongName" SG_ 1202 AutoHldServIndOn "Auto Hold Service Indication On";
BA_ "SignalType" SG_ 1202 AutoHldDsbldStBltIndOn "ENM";
BA_ "SignalLongName" SG_ 1202 AutoHldDsbldStBltIndOn "Auto Hold Disabled Seatbelt Indication On";
BA_ "SignalType" SG_ 1202 TrlrStbAsstActIO "ENM";
BA_ "SignalLongName" SG_ 1202 TrlrStbAsstActIO "TrailerStabilityAssistActiveIndicationOn";
BA_ "SignalType" SG_ 1202 SrvESCMdIO "ENM";
BA_ "SignalLongName" SG_ 1202 SrvESCMdIO "Service Electronic Stability Control Indication On";
BA_ "SignalType" SG_ 1202 ServTracCtlIndOn "ENM";
BA_ "SignalLongName" SG_ 1202 ServTracCtlIndOn "Service Traction Control Indication On";
BA_ "SignalType" SG_ 1202 HillStrtAstActIO "ENM";
BA_ "SignalLongName" SG_ 1202 HillStrtAstActIO "Hill Start Assist\??Active Indication On";
BA_ "SignalType" SG_ 1202 HillRollCntrlActIO "ENM";
BA_ "SignalLongName" SG_ 1202 HillRollCntrlActIO "Hill Rollback Control Active Indication On";
BA_ "SignalType" SG_ 1202 ESCPrfMdIO "ENM";
BA_ "SignalLongName" SG_ 1202 ESCPrfMdIO "Electronic Stability Control Performance Mode Indication On";
BA_ "SignalType" SG_ 1202 VehStbEnhcmntCustAv "ENM";
BA_ "SignalLongName" SG_ 1202 VehStbEnhcmntCustAv "Vehicle Stability Enhancement Customization Available";
BA_ "SignalType" SG_ 1202 VehStbEnhcmntCurStat "ENM";
BA_ "SignalLongName" SG_ 1202 VehStbEnhcmntCurStat "Vehicle Stability Enhancement Current State";
BA_ "SignalType" SG_ 1202 VehStbCompMdCustAv "ENM";
BA_ "SignalLongName" SG_ 1202 VehStbCompMdCustAv "Vehicle Stability Competitive Mode Customization Available";
BA_ "SignalType" SG_ 1202 VehStbCompMdCurStat "ENM";
BA_ "SignalLongName" SG_ 1202 VehStbCompMdCurStat "Vehicle Stability Competitive Mode Current State";
BA_ "SignalType" SG_ 1203 FllwgTmDsplyMd "ENM";
BA_ "SignalLongName" SG_ 1203 FllwgTmDsplyMd "Following Time Display Mode";
BA_ "SignalLongName" SG_ 1203 FllwgTmIndVal "Following Time Indicator Value";
BA_ "SignalType" SG_ 1203 AdpAndCnvntlCruzCtlIndReq "ENM";
BA_ "SignalLongName" SG_ 1203 AdpAndCnvntlCruzCtlIndReq "Adaptive and Conventional Cruise Control Indication Request";
BA_ "SignalType" SG_ 1203 LtAstStsIndRq "ENM";
BA_ "SignalLongName" SG_ 1203 LtAstStsIndRq "Lateral Assist Status Indication Request";
BA_ "SignalType" SG_ 1203 FCAGpSet "ENM";
BA_ "SignalLongName" SG_ 1203 FCAGpSet "Forward Collision Alert Gap Setting";
BA_ "SignalType" SG_ 1203 LAOA_LatAsstLDWOptAval "ENM";
BA_ "SignalLongName" SG_ 1203 LAOA_LatAsstLDWOptAval "Lateral Assist Options Available : LDW";
BA_ "SignalType" SG_ 1203 LAOA_LatAsstHoLFOptAval "ENM";
BA_ "SignalLongName" SG_ 1203 LAOA_LatAsstHoLFOptAval "Lateral Assist Options Available : HoLF";
BA_ "SignalType" SG_ 1203 LAOA_LatAsstLKAOptAval "ENM";
BA_ "SignalLongName" SG_ 1203 LAOA_LatAsstLKAOptAval "Lateral Assist Options Available : LKA";
BA_ "SignalType" SG_ 1203 LAOA_LatAsstOffOptAval "ENM";
BA_ "SignalLongName" SG_ 1203 LAOA_LatAsstOffOptAval "Lateral Assist Options Available : Off";
BA_ "SignalType" SG_ 1203 PdWrnIndRqst "ENM";
BA_ "SignalLongName" SG_ 1203 PdWrnIndRqst "Pedestrian Warning Indication Request";
BA_ "SignalType" SG_ 1203 FrwdHdwyVisIndCtl "ENM";
BA_ "SignalLongName" SG_ 1203 FrwdHdwyVisIndCtl "Forward Headway Visual Indicator Control";
BA_ "SignalType" SG_ 1203 ACCHdwySttng "ENM";
BA_ "SignalLongName" SG_ 1203 ACCHdwySttng "Adaptive Cruise Control Headway Setting";
BA_ "SignalType" SG_ 1203 FCA_ACCGapSetIndOn "ENM";
BA_ "SignalLongName" SG_ 1203 FCA_ACCGapSetIndOn "Forward Collision Alert Adaptive Cruise Control Gap Setting Indication On";
BA_ "SignalType" SG_ 1203 ACCTmpUnvIndOn "ENM";
BA_ "SignalLongName" SG_ 1203 ACCTmpUnvIndOn "Adaptive Cruise Control Temporary Unavailable Indication On";
BA_ "SignalType" SG_ 1203 ACCSysSlctdMdDspIndOn "ENM";
BA_ "SignalLongName" SG_ 1203 ACCSysSlctdMdDspIndOn "Adaptive Cruise Control System Selected Mode Display Indication On";
BA_ "SignalType" SG_ 1203 ACCShftToPrkBfrExIndOn "ENM";
BA_ "SignalLongName" SG_ 1203 ACCShftToPrkBfrExIndOn "Adaptive Cruise Control Shift To Park Before Exiting Vehicle Indication On";
BA_ "SignalType" SG_ 1203 ACCRtSpdAdVsIndOn "ENM";
BA_ "SignalLongName" SG_ 1203 ACCRtSpdAdVsIndOn "Adaptive Cruise Control Route Speed Adaptation Visual Indication On";
BA_ "SignalType" SG_ 1203 ACCHdwySttngIndOn "ENM";
BA_ "SignalLongName" SG_ 1203 ACCHdwySttngIndOn "Adaptive Cruise Control Headway Setting Indication On";
BA_ "SignalType" SG_ 1203 ACCDsngIndOn "ENM";
BA_ "SignalLongName" SG_ 1203 ACCDsngIndOn "Adaptive Cruise Control Disengaging Indication On";
BA_ "SignalType" SG_ 1203 ACCDrSlctdSpdIndOn "ENM";
BA_ "SignalLongName" SG_ 1203 ACCDrSlctdSpdIndOn "Adaptive Cruise Control Driver Selected Speed Indication On";
BA_ "SignalType" SG_ 1203 LnKpAsstUnAvIndOn "ENM";
BA_ "SignalLongName" SG_ 1203 LnKpAsstUnAvIndOn "LaneKeepAssistUnavailableIndicationOn";
BA_ "SignalType" SG_ 1203 LnDprtrWrngUnAvIndOn "ENM";
BA_ "SignalLongName" SG_ 1203 LnDprtrWrngUnAvIndOn "LaneDepartureWarningUnavailableIndicationOn";
BA_ "SignalType" SG_ 1203 FrwdClsnSysIndOn "ENM";
BA_ "SignalLongName" SG_ 1203 FrwdClsnSysIndOn "Forward Collision System Indication On";
BA_ "SignalType" SG_ 1203 FrwdCllsnSysUnIndOn "ENM";
BA_ "SignalLongName" SG_ 1203 FrwdCllsnSysUnIndOn "Forward Collision System Unavailable Indication On";
BA_ "SignalType" SG_ 1203 FrwdCllsnSysRdIndOn "ENM";
BA_ "SignalLongName" SG_ 1203 FrwdCllsnSysRdIndOn "Forward Collision System Reduced Indication On";
BA_ "SignalType" SG_ 1203 FrwdCllsnSysOffIndOn "ENM";
BA_ "SignalLongName" SG_ 1203 FrwdCllsnSysOffIndOn "Forward Collision System Off Indication On";
BA_ "SignalType" SG_ 1203 FrwdCllsnAlrtOffIndOn "ENM";
BA_ "SignalLongName" SG_ 1203 FrwdCllsnAlrtOffIndOn "Forward Collision Alert Off Indication On";
BA_ "SignalType" SG_ 1203 FrtPedtrnBrkgWrnIndOn "ENM";
BA_ "SignalLongName" SG_ 1203 FrtPedtrnBrkgWrnIndOn "Front Pedestrian Braking Warning Indication On";
BA_ "SignalLongName" SG_ 1203 ACCDrSlctdSpd "Adaptive Cruise Control Driver Selected Speed";
BA_ "SignalType" SG_ 1203 TnDrvGapAdjUnvIndOn "ENM";
BA_ "SignalLongName" SG_ 1203 TnDrvGapAdjUnvIndOn "Teen Driver Gap Adjust Unavailable Indication On";
BA_ "SignalType" SG_ 1203 TeenDrvrLnDprtrWrnOffUnvIndOn "ENM";
BA_ "SignalLongName" SG_ 1203 TeenDrvrLnDprtrWrnOffUnvIndOn "Teen Driver Lane Departure Warning Off Unavailable Indication On";
BA_ "SignalType" SG_ 1203 SrvFrwdCllsnSysIndOn "ENM";
BA_ "SignalLongName" SG_ 1203 SrvFrwdCllsnSysIndOn "Service Forward Collision System Indication On";
BA_ "SignalLongName" SG_ 1337 HVACTCR_BlwLvlFrt "HVAC Telematics Controls Request : Blower Level Front";
BA_ "SignalLongName" SG_ 1337 HVACTCR_ARC "HVAC Telematics Controls Request : Alive Rolling Count";
BA_ "SignalType" SG_ 1337 HVACTCR_RrDfgSet "ENM";
BA_ "SignalLongName" SG_ 1337 HVACTCR_RrDfgSet "HVAC Telematics Controls Request : Rear Defog Setting";
BA_ "SignalType" SG_ 1337 HVACTCR_RecircSet "ENM";
BA_ "SignalLongName" SG_ 1337 HVACTCR_RecircSet "HVAC Telematics Controls Request : Recirculation Setting";
BA_ "SignalType" SG_ 1337 HVACTCR_AirDstLtSet "ENM";
BA_ "SignalLongName" SG_ 1337 HVACTCR_AirDstLtSet "HVAC Telematics Controls Request : Air Distribution Left Setting";
BA_ "SignalType" SG_ 1337 HVACTCR_CompSet "ENM";
BA_ "SignalLongName" SG_ 1337 HVACTCR_CompSet "HVAC Telematics Controls Request : Compressor Setting";
BA_ "SignalType" SG_ 1337 HVACTCR_TempFrtLtLvlActv "ENM";
BA_ "SignalLongName" SG_ 1337 HVACTCR_TempFrtLtLvlActv "HVAC Telematics Controls Request : Temperature Front Left Level Active";
BA_ "SignalType" SG_ 1337 HVACTCR_AirDstRtSet "ENM";
BA_ "SignalLongName" SG_ 1337 HVACTCR_AirDstRtSet "HVAC Telematics Controls Request : Air Distribution Right Setting";
BA_ "SignalType" SG_ 1337 HVACTCR_TempFrtRtLvlActv "ENM";
BA_ "SignalLongName" SG_ 1337 HVACTCR_TempFrtRtLvlActv "HVAC Telematics Controls Request : Temperature Front Right Level Active";
BA_ "SignalType" SG_ 1337 HVACTCR_RmtClmCtlReqingSets "ENM";
BA_ "SignalLongName" SG_ 1337 HVACTCR_RmtClmCtlReqingSets "HVAC Telematics Controls Request : Remote Climate Control Requesting Settings";
BA_ "SignalType" SG_ 1337 HVACTCR_FrtAutoSetChg "ENM";
BA_ "SignalLongName" SG_ 1337 HVACTCR_FrtAutoSetChg "HVAC Telematics Controls Request : Front Auto Setting Change";
BA_ "SignalType" SG_ 1337 HVACTCR_PwrSet "ENM";
BA_ "SignalLongName" SG_ 1337 HVACTCR_PwrSet "HVAC Telematics Controls Request : Power Setting";
BA_ "SignalType" SG_ 1337 HVACTCR_SyncSet "ENM";
BA_ "SignalLongName" SG_ 1337 HVACTCR_SyncSet "HVAC Telematics Controls Request : Sync Setting";
BA_ "SignalType" SG_ 1337 HVACTCR_MaxDefrSet "ENM";
BA_ "SignalLongName" SG_ 1337 HVACTCR_MaxDefrSet "HVAC Telematics Controls Request : Max Defrost Setting";
BA_ "SignalLongName" SG_ 1337 HVACTCR_TempFrtRtLvl "HVAC Telematics Controls Request : Temperature Front Right Level";
BA_ "SignalLongName" SG_ 1337 HVACTCR_TempFrtLtLvl "HVAC Telematics Controls Request : Temperature Front Left Level";
BA_ "SignalType" SG_ 1337 RmtTrlrLtngSeqReq "ENM";
BA_ "SignalLongName" SG_ 1337 RmtTrlrLtngSeqReq "Remote Trailer Lighting Sequence Request";
BA_ "SignalType" SG_ 1337 HVACTCR_BlwLvlFrtActv "ENM";
BA_ "SignalLongName" SG_ 1337 HVACTCR_BlwLvlFrtActv "HVAC Telematics Controls Request : Blower Level Front Active";
BA_ "SignalType" SG_ 1337 TeleAlrmVisReq "ENM";
BA_ "SignalLongName" SG_ 1337 TeleAlrmVisReq "TelematicsAlarmVisualRequest";
BA_ "SignalType" SG_ 1337 TeleAlrmHrnReq "ENM";
BA_ "SignalLongName" SG_ 1337 TeleAlrmHrnReq "TelematicsAlarmHornRequest";
BA_ "SignalLongName" SG_ 1204 LnCntrArrwBlck1Offst "Lane Centering Arrow Block 1 Offset";
BA_ "SignalLongName" SG_ 1204 LnCntrArrwBlck2Offst "Lane Centering Arrow Block 2 Offset";
BA_ "SignalType" SG_ 1204 LnCntrCntrlIndRqst "ENM";
BA_ "SignalLongName" SG_ 1204 LnCntrCntrlIndRqst "Lane Centering Control Indication Request";
BA_ "SignalType" SG_ 1204 LnCntrCnvMsgIndRqst "ENM";
BA_ "SignalLongName" SG_ 1204 LnCntrCnvMsgIndRqst "Lane Centering Convenience Message Indication Request";
BA_ "SignalType" SG_ 1204 SrvDvrAsstSystVslMsgRqstOn "ENM";
BA_ "SignalLongName" SG_ 1204 SrvDvrAsstSystVslMsgRqstOn "Service Driver Assist System Visual Message Request On";
BA_ "SignalType" SG_ 1204 LnCntrArrwBlck5Act "ENM";
BA_ "SignalLongName" SG_ 1204 LnCntrArrwBlck5Act "Lane Centering Arrow Block 5 Active";
BA_ "SignalType" SG_ 1204 LnCntrArrwBlck4Act "ENM";
BA_ "SignalLongName" SG_ 1204 LnCntrArrwBlck4Act "Lane Centering Arrow Block 4 Active";
BA_ "SignalType" SG_ 1204 LnCntrArrwBlck3Act "ENM";
BA_ "SignalLongName" SG_ 1204 LnCntrArrwBlck3Act "Lane Centering Arrow Block 3 Active";
BA_ "SignalType" SG_ 1204 LnCntrArrwBlck2Act "ENM";
BA_ "SignalLongName" SG_ 1204 LnCntrArrwBlck2Act "Lane Centering Arrow Block 2 Active";
BA_ "SignalType" SG_ 1204 LnCntrArrwBlck1Act "ENM";
BA_ "SignalLongName" SG_ 1204 LnCntrArrwBlck1Act "Lane Centering Arrow Block 1 Active";
BA_ "SignalType" SG_ 1204 LnCntrSpchPrmtReq "ENM";
BA_ "SignalLongName" SG_ 1204 LnCntrSpchPrmtReq "Lane Centering Speech Prompt Request";
BA_ "SignalLongName" SG_ 1306 ReqTmpChgRRRr "Request Temperature Change Rear Right Rear";
BA_ "SignalLongName" SG_ 1306 ReqTmpChgRLRr "Request Temperature Change Rear Left Rear";
BA_ "SignalLongName" SG_ 1306 ReqTmpLvlRLRr "Request Temperature Level Rear Left Rear";
BA_ "SignalLongName" SG_ 1306 ReqTmpLvlRRRr "Request Temperature Level Rear Right Rear";
BA_ "SignalLongName" SG_ 1306 ReqBlwLvlChgRrRr "Request Blower Level Change Rear Rear";
BA_ "SignalType" SG_ 1306 ReqAirDstRRRr "ENM";
BA_ "SignalLongName" SG_ 1306 ReqAirDstRRRr "Request Air Distribution Rear Right Rear";
BA_ "SignalType" SG_ 1306 ReqAirDstRLRr "ENM";
BA_ "SignalLongName" SG_ 1306 ReqAirDstRLRr "Request Air Distribution Rear Left Rear";
BA_ "SignalType" SG_ 1306 ReqAirDstChgNxtRLRr "ENM";
BA_ "SignalLongName" SG_ 1306 ReqAirDstChgNxtRLRr "Request Air Distribution Change Next Rear Left Rear";
BA_ "SignalType" SG_ 1306 RrAirHandlingDrActrPwrFdbk "ENM";
BA_ "SignalLongName" SG_ 1306 RrAirHandlingDrActrPwrFdbk "Rear Air Handling Door Actuator Power Feedback";
BA_ "SignalLongName" SG_ 1306 ReqBlwLvlRrRr "Request Blower Level Rear Rear";
BA_ "SignalType" SG_ 1306 RrHVACCtrlInitFin "ENM";
BA_ "SignalLongName" SG_ 1306 RrHVACCtrlInitFin "Rear HVAC Control Initialization Finished";
BA_ "SignalType" SG_ 1306 ReqTmpLvlRRAtvRr "ENM";
BA_ "SignalLongName" SG_ 1306 ReqTmpLvlRRAtvRr "Request Temperature Level Rear Right Active Rear";
BA_ "SignalType" SG_ 1306 ReqTmpLvlRLAtvRr "ENM";
BA_ "SignalLongName" SG_ 1306 ReqTmpLvlRLAtvRr "Request Temperature Level Rear Left Active Rear";
BA_ "SignalType" SG_ 1306 ReqSYNC_RrChgRr "ENM";
BA_ "SignalLongName" SG_ 1306 ReqSYNC_RrChgRr "Request SYNC Rear Change Rear";
BA_ "SignalType" SG_ 1306 ReqRrHVAC_PwrChgRr "ENM";
BA_ "SignalLongName" SG_ 1306 ReqRrHVAC_PwrChgRr "Request Rear HVAC Power Change Rear";
BA_ "SignalType" SG_ 1306 ReqRrAutoRr "ENM";
BA_ "SignalLongName" SG_ 1306 ReqRrAutoRr "Request Rear Auto Rear";
BA_ "SignalType" SG_ 1306 ReqBlwLvlRrAtvRr "ENM";
BA_ "SignalLongName" SG_ 1306 ReqBlwLvlRrAtvRr "Request Blower Level Rear Active Rear";
BA_ "SignalType" SG_ 1306 ReqAirDstChgNxtRRRr "ENM";
BA_ "SignalLongName" SG_ 1306 ReqAirDstChgNxtRRRr "Request Air Distribution Change Next Rear Right Rear";
BA_ "SignalLongName" SG_ 1205 TSMCurrSpdLim "Traffic Sign Memory Current Speed Limit";
BA_ "SignalType" SG_ 1205 TSMEurDispSgn2Mn "ENM";
BA_ "SignalLongName" SG_ 1205 TSMEurDispSgn2Mn "Traffic Sign Memory Europe Display Europe Sign 2 Main";
BA_ "SignalType" SG_ 1205 TSMEurDispSgn1Mn "ENM";
BA_ "SignalLongName" SG_ 1205 TSMEurDispSgn1Mn "Traffic Sign Memory Europe Display Sign 1 Main";
BA_ "SignalType" SG_ 1205 TSMUSAndCADispSgn1Mn "ENM";
BA_ "SignalLongName" SG_ 1205 TSMUSAndCADispSgn1Mn "Traffic Sign Memory US and Canada Display Sign 1 Main";
BA_ "SignalType" SG_ 1205 TSMUSAndCADispSgn2Mn "ENM";
BA_ "SignalLongName" SG_ 1205 TSMUSAndCADispSgn2Mn "Traffic Sign Memory US and Canada Display Sign 2 Main";
BA_ "SignalType" SG_ 1205 TSMEurDispSgn2AddOn "ENM";
BA_ "SignalLongName" SG_ 1205 TSMEurDispSgn2AddOn "Traffic Sign Memory Display Sign 2 Add-On";
BA_ "SignalType" SG_ 1205 TSMEurDispSgn1AddOn "ENM";
BA_ "SignalLongName" SG_ 1205 TSMEurDispSgn1AddOn "Traffic Sign Memory Europe Display Sign 1 Add-On";
BA_ "SignalType" SG_ 1205 FrwdVsFlDtcnIndOn "ENM";
BA_ "SignalLongName" SG_ 1205 FrwdVsFlDtcnIndOn "Front Vision Failure Detection Indication On";
BA_ "SignalType" SG_ 1205 FrwdVsAdvWthrIndOn "ENM";
BA_ "SignalLongName" SG_ 1205 FrwdVsAdvWthrIndOn "Front Vision Adverse Weather Indication On";
BA_ "SignalType" SG_ 1205 TSMUSAndCADispSgn2AddOn "ENM";
BA_ "SignalLongName" SG_ 1205 TSMUSAndCADispSgn2AddOn "Traffic Sign Memory US and Canada Display Sign 2 Add On";
BA_ "SignalType" SG_ 1205 TSMUSAndCADispSgn1AddOn "ENM";
BA_ "SignalLongName" SG_ 1205 TSMUSAndCADispSgn1AddOn "Traffic Sign Memory US and Canada Display Sign 1 Add On";
BA_ "SignalType" SG_ 1205 TrffcLgtAsstHUDWrnIndOn "ENM";
BA_ "SignalLongName" SG_ 1205 TrffcLgtAsstHUDWrnIndOn "Traffic Light Assist Heads up Display Warning Indication On";
BA_ "SignalType" SG_ 1205 TrffcLgtAsstClstrWrnIndOn "ENM";
BA_ "SignalLongName" SG_ 1205 TrffcLgtAsstClstrWrnIndOn "Traffic Light Assist Cluster Warning Indication On";
BA_ "SignalType" SG_ 1205 TSMSgnNtfnIndOn "ENM";
BA_ "SignalLongName" SG_ 1205 TSMSgnNtfnIndOn "Traffic Sign Memory Sign Notification Indication On";
BA_ "SignalType" SG_ 1205 TSMPDAMnSgnFlshgReq "ENM";
BA_ "SignalLongName" SG_ 1205 TSMPDAMnSgnFlshgReq "Traffic Sign Memory PDA Main Sign Flashing Request";
BA_ "SignalType" SG_ 1205 TSMNoEntryIndOn "ENM";
BA_ "SignalLongName" SG_ 1205 TSMNoEntryIndOn "Traffic Sign Memory No Entry Indication On";
BA_ "SignalType" SG_ 1205 TSMIcePsblIndOn "ENM";
BA_ "SignalLongName" SG_ 1205 TSMIcePsblIndOn "Traffic Sign Memory Ice Possible Indication On";
BA_ "SignalType" SG_ 1205 TSMAddTrfSgnAvIndOn "ENM";
BA_ "SignalLongName" SG_ 1205 TSMAddTrfSgnAvIndOn "Traffic Sign Memory Additional Traffic Signs Available Indication On";
BA_ "SignalType" SG_ 1205 FrwdVsFllBlckIndOn "ENM";
BA_ "SignalLongName" SG_ 1205 FrwdVsFllBlckIndOn "Front Vision Full Blockage Indication On";
BA_ "SignalType" SG_ 1205 TrffcLgtAsstRLADWrnIndOn "ENM";
BA_ "SignalLongName" SG_ 1205 TrffcLgtAsstRLADWrnIndOn "Traffic Light Assist Reflective Light Auxiliary Display Warning Indication On";
BA_ "SignalType" SG_ 1233 FrtRdHgtGPSCstCurrSetVal "ENM";
BA_ "SignalLongName" SG_ 1233 FrtRdHgtGPSCstCurrSetVal "Front Ride Height GPS Customization Current Setting Value";
BA_ "SignalType" SG_ 1233 FrtRdHgtGPSCstSetAval "ENM";
BA_ "SignalLongName" SG_ 1233 FrtRdHgtGPSCstSetAval "Front Ride Height GPS Customization Setting Available";
BA_ "SignalLongName" SG_ 607 FlInjRlCt "Fuel Injected Rolling Count";
BA_ "SignalLongName" SG_ 607 InstFlCnsmpRt "Instantaneous Fuel Consumption Rate";
BA_ "SignalLongName" SG_ 607 EngIntkArBstPr "Engine Intake Air Boost Pressure";
BA_ "SignalType" SG_ 607 EngIntkArBstPr_Inv "ENM";
BA_ "SignalLongName" SG_ 607 EngIntkArBstPr_Inv "Engine Intake Air Boost Pressure Invalid";
BA_ "SignalLongName" SG_ 607 EngBstPrsInd "Engine Boost Pressure Indication";
BA_ "SignalType" SG_ 607 EngBstPrsInd_Inv "ENM";
BA_ "SignalLongName" SG_ 607 EngBstPrsInd_Inv "Engine Boost Pressure Indication Invalid";
BA_ "SignalType" SG_ 607 FlInjRlCtRstOcc "ENM";
BA_ "SignalLongName" SG_ 607 FlInjRlCtRstOcc "Fuel Injected Rolling Count Reset Occurred";
BA_ "SignalType" SG_ 1270 ADASIS_NAVILINK_DgtlMpEfSpdLm "ENM";
BA_ "SignalLongName" SG_ 1270 ADASIS_NAVILINK_DgtlMpEfSpdLm "ADASIS NAVILINK Digital Map Effective Speed Limit";
BA_ "SignalType" SG_ 1270 ADASIS_NAVILINK_CntryCd "ENM";
BA_ "SignalLongName" SG_ 1270 ADASIS_NAVILINK_CntryCd "ADASIS NAVILINK Country Code";
BA_ "SignalType" SG_ 1270 ADASIS_NAVILINK_DigMpCndlSpdLmt "ENM";
BA_ "SignalLongName" SG_ 1270 ADASIS_NAVILINK_DigMpCndlSpdLmt "ADASIS NAVILINK Digital Map Conditional Speed Limit";
BA_ "SignalType" SG_ 1270 ADASIS_NAVILINK_DgtlMpSpdCtgry "ENM";
BA_ "SignalLongName" SG_ 1270 ADASIS_NAVILINK_DgtlMpSpdCtgry "ADASIS NAVILINK Digital Map Speed Category";
BA_ "SignalType" SG_ 1270 ADASIS_NAVILINK_DgtlMpPsngRst "ENM";
BA_ "SignalLongName" SG_ 1270 ADASIS_NAVILINK_DgtlMpPsngRst "ADASIS NAVILINK Digital Map Passing Restriction";
BA_ "SignalType" SG_ 1270 ADASIS_NAVILINK_DigMpEfSpdLmTyp "ENM";
BA_ "SignalLongName" SG_ 1270 ADASIS_NAVILINK_DigMpEfSpdLmTyp "ADASIS NAVILINK Digital Map Effective Speed Limit Type";
BA_ "SignalType" SG_ 1270 ADASIS_NAVILINK_DgMpCnSpdLmTyp "ENM";
BA_ "SignalLongName" SG_ 1270 ADASIS_NAVILINK_DgMpCnSpdLmTyp "ADASIS NAVILINK Digital Map Conditional Speed Limit Type";
BA_ "SignalType" SG_ 1270 ADASIS_NAVILINK_DigMpPstSpdLmAs "ENM";
BA_ "SignalLongName" SG_ 1270 ADASIS_NAVILINK_DigMpPstSpdLmAs "ADASIS NAVILINK Digital Map Posted Speed Limit Assured";
BA_ "SignalType" SG_ 1270 ADASIS_NAVILINK_DigMpDrvngSd "ENM";
BA_ "SignalLongName" SG_ 1270 ADASIS_NAVILINK_DigMpDrvngSd "ADASIS NAVILINK Digital Map Driving Side";
BA_ "SignalType" SG_ 1270 ADASIS_NAVILINK_CntrldAccssRd "ENM";
BA_ "SignalLongName" SG_ 1270 ADASIS_NAVILINK_CntrldAccssRd "ADASIS NAVILINK Controlled Access Road";
BA_ "SignalType" SG_ 1270 ADASIS_NAVILINK_BldUpFlg "ENM";
BA_ "SignalLongName" SG_ 1270 ADASIS_NAVILINK_BldUpFlg "ADASIS NAVILINK Build Up Flag";
BA_ "SignalType" SG_ 1234 CustMdDrvlCstmCurSetVal "ENM";
BA_ "SignalLongName" SG_ 1234 CustMdDrvlCstmCurSetVal "Custom Mode Driveline Customization Current Setting Value";
BA_ "SignalType" SG_ 1234 CustMdBrkPdlCstmCurSetVal "ENM";
BA_ "SignalLongName" SG_ 1234 CustMdBrkPdlCstmCurSetVal "Custom Mode Brake Pedal Customization Current Setting Value";
BA_ "SignalType" SG_ 1234 CustMdActAeroCstmCurSetVal "ENM";
BA_ "SignalLongName" SG_ 1234 CustMdActAeroCstmCurSetVal "Custom Mode Active Aero Customization Current Setting Value";
BA_ "SignalType" SG_ 1234 CustMdRideHghtCstmCurSetVal "ENM";
BA_ "SignalLongName" SG_ 1234 CustMdRideHghtCstmCurSetVal "Custom Mode Ride Height Customization Current Setting Value";
BA_ "SignalType" SG_ 1234 CustMdPTCstmPndSetVal "ENM";
BA_ "SignalLongName" SG_ 1234 CustMdPTCstmPndSetVal "Custom Mode Powertrain Customization Pending Setting Value";
BA_ "SignalType" SG_ 1234 CustMdPTCstmCurSetVal "ENM";
BA_ "SignalLongName" SG_ 1234 CustMdPTCstmCurSetVal "Custom Mode Powertrain Customization Current Setting Value";
BA_ "SignalType" SG_ 1234 CustMdSpnCstmCurSetVal "ENM";
BA_ "SignalLongName" SG_ 1234 CustMdSpnCstmCurSetVal "Custom Mode Suspension Customization Current Setting Value";
BA_ "SignalType" SG_ 1234 CustMdSndCstmCurSetVal "ENM";
BA_ "SignalLongName" SG_ 1234 CustMdSndCstmCurSetVal "Custom Mode Sound Customization Current Setting Value";
BA_ "SignalType" SG_ 1234 CustMdBrkPdlCstmSetAv "ENM";
BA_ "SignalLongName" SG_ 1234 CustMdBrkPdlCstmSetAv "Custom Mode Brake Pedal Customization Setting Available";
BA_ "SignalType" SG_ 1234 CustMdActAeroCstmSetAv "ENM";
BA_ "SignalLongName" SG_ 1234 CustMdActAeroCstmSetAv "Custom Mode Active Aero Customization Setting Available";
BA_ "SignalType" SG_ 1234 CustMdTrcStbCstmCurSetVal "ENM";
BA_ "SignalLongName" SG_ 1234 CustMdTrcStbCstmCurSetVal "Custom Mode Traction Stability Customization Current Setting Value";
BA_ "SignalType" SG_ 1234 CustMdStrCstmCurSetVal "ENM";
BA_ "SignalLongName" SG_ 1234 CustMdStrCstmCurSetVal "Custom Mode Steering Customization Current Setting Value";
BA_ "SignalType" SG_ 1234 CustMdTrcStbCstmSetAv "ENM";
BA_ "SignalLongName" SG_ 1234 CustMdTrcStbCstmSetAv "Custom Mode Traction Stability Customization Setting Available";
BA_ "SignalType" SG_ 1234 CustMdStrCstmSetAv "ENM";
BA_ "SignalLongName" SG_ 1234 CustMdStrCstmSetAv "Custom Mode Steering Customization Setting Available";
BA_ "SignalType" SG_ 1234 CustMdSpnCstmSetAv "ENM";
BA_ "SignalLongName" SG_ 1234 CustMdSpnCstmSetAv "Custom Mode Suspension Customization Setting Available";
BA_ "SignalType" SG_ 1234 CustMdSndCstmSetAv "ENM";
BA_ "SignalLongName" SG_ 1234 CustMdSndCstmSetAv "Custom Mode Sound Customization Setting Available";
BA_ "SignalType" SG_ 1234 CustMdRideHghtCstmSetAv "ENM";
BA_ "SignalLongName" SG_ 1234 CustMdRideHghtCstmSetAv "Custom Mode Ride Height Customization Setting Available";
BA_ "SignalType" SG_ 1234 CustMdPTCstmSetAv "ENM";
BA_ "SignalLongName" SG_ 1234 CustMdPTCstmSetAv "Custom Mode Powertrain Customization Setting Available";
BA_ "SignalType" SG_ 1234 CustMdDrvlCstmSetAv "ENM";
BA_ "SignalLongName" SG_ 1234 CustMdDrvlCstmSetAv "Custom Mode Driveline Customization Setting Available";
BA_ "SignalType" SG_ 1235 PrsnlMdActAeroCstmCurSetVal "ENM";
BA_ "SignalLongName" SG_ 1235 PrsnlMdActAeroCstmCurSetVal "Personal Mode Active Aero Customization Current Setting Value";
BA_ "SignalType" SG_ 1235 ExtdHillStrtAstCustCurSetVal "ENM";
BA_ "SignalLongName" SG_ 1235 ExtdHillStrtAstCustCurSetVal "Extended Hill Start Assist Customization Current Setting Value";
BA_ "SignalType" SG_ 1235 DisPrfMdRq "ENM";
BA_ "SignalLongName" SG_ 1235 DisPrfMdRq "Display Performance Mode Request";
BA_ "SignalType" SG_ 1235 PrsnlMdRideHghtCstmCurSetVal "ENM";
BA_ "SignalLongName" SG_ 1235 PrsnlMdRideHghtCstmCurSetVal "Personal Mode Ride Height Customization Current Setting Value";
BA_ "SignalType" SG_ 1235 PrsnlMdDrvlCstmCurSetVal "ENM";
BA_ "SignalLongName" SG_ 1235 PrsnlMdDrvlCstmCurSetVal "Personal Mode Driveline Customization Current Setting Value";
BA_ "SignalType" SG_ 1235 PrsnlMdBrkPdlCstmCurSetVal "ENM";
BA_ "SignalLongName" SG_ 1235 PrsnlMdBrkPdlCstmCurSetVal "Personal Mode Brake Pedal Customization Current Setting Value";
BA_ "SignalType" SG_ 1235 PrsnlMdSpnCstmCurSetVal "ENM";
BA_ "SignalLongName" SG_ 1235 PrsnlMdSpnCstmCurSetVal "Personal Mode Suspension Customization Current Setting Value";
BA_ "SignalType" SG_ 1235 PrsnlMdSndCstmCurSetVal "ENM";
BA_ "SignalLongName" SG_ 1235 PrsnlMdSndCstmCurSetVal "Personal Mode Sound Customization Current Setting Value";
BA_ "SignalType" SG_ 1235 PrsnlMdRideHghtCstmSetAv "ENM";
BA_ "SignalLongName" SG_ 1235 PrsnlMdRideHghtCstmSetAv "Personal Mode Ride Height Customization Setting Available";
BA_ "SignalType" SG_ 1235 PrsnlMdDrvlCstmSetAv "ENM";
BA_ "SignalLongName" SG_ 1235 PrsnlMdDrvlCstmSetAv "Personal Mode Driveline Customization Setting Available";
BA_ "SignalType" SG_ 1235 PrsnlMdBrkPdlCstmSetAv "ENM";
BA_ "SignalLongName" SG_ 1235 PrsnlMdBrkPdlCstmSetAv "Personal Mode Brake Pedal Customization Setting Available";
BA_ "SignalType" SG_ 1235 PrsnlMdActAeroCstmSetAv "ENM";
BA_ "SignalLongName" SG_ 1235 PrsnlMdActAeroCstmSetAv "Personal Mode Active Aero Customization Setting Available";
BA_ "SignalType" SG_ 1235 ExtdHillStrtAstCustSetAvl "ENM";
BA_ "SignalLongName" SG_ 1235 ExtdHillStrtAstCustSetAvl "Extended Hill Start Assist Customization Setting Available";
BA_ "SignalType" SG_ 1235 PrsnlMdStrCstmCurSetVal "ENM";
BA_ "SignalLongName" SG_ 1235 PrsnlMdStrCstmCurSetVal "Personal Mode Steering Customization Current Setting Value";
BA_ "SignalType" SG_ 1235 TrlrBrkDtd "ENM";
BA_ "SignalLongName" SG_ 1235 TrlrBrkDtd "Trailer Brakes Detected";
BA_ "SignalType" SG_ 1235 PrsnlMdStrCstmSetAv "ENM";
BA_ "SignalLongName" SG_ 1235 PrsnlMdStrCstmSetAv "Personal Mode Steering Customization Setting Available";
BA_ "SignalType" SG_ 1235 PrsnlMdSpnCstmSetAv "ENM";
BA_ "SignalLongName" SG_ 1235 PrsnlMdSpnCstmSetAv "Personal Mode Suspension Customization Setting Available";
BA_ "SignalType" SG_ 1235 PrsnlMdSndCstmSetAv "ENM";
BA_ "SignalLongName" SG_ 1235 PrsnlMdSndCstmSetAv "Personal Mode Sound Customization Setting Available";
BA_ "SignalLongName" SG_ 1169 InvsblTrlrAux1CamPlcmtFdbkPtch "Invisible Trailer Aux1 Camera Placement Feedback Pitch";
BA_ "SignalLongName" SG_ 1169 InvsblTrlrAux1CamPlcmtFdbkRoll "Invisible Trailer Aux1 Camera Placement Feedback Roll";
BA_ "SignalLongName" SG_ 1169 InvsblTrlrAux1CamPlcmtFdbkX "Invisible Trailer Aux1 Camera Placement Feedback X";
BA_ "SignalLongName" SG_ 1169 InvsblTrlrAux1CamPlcmtFdbkY "Invisible Trailer Aux1 Camera Placement Feedback Y";
BA_ "SignalType" SG_ 1170 JckKnfDtnCstAvlFlg1 "ENM";
BA_ "SignalLongName" SG_ 1170 JckKnfDtnCstAvlFlg1 "Jack Knife Detection Customization Availability Flag 1";
BA_ "SignalType" SG_ 1170 CrgBedVwAutoLgtCstAvlFlg7 "ENM";
BA_ "SignalLongName" SG_ 1170 CrgBedVwAutoLgtCstAvlFlg7 "Cargo Bed View Auto Lighting Customization Availability Flag 7";
BA_ "SignalType" SG_ 1170 CrgBedVwAutoLgtCstAvlFlg6 "ENM";
BA_ "SignalLongName" SG_ 1170 CrgBedVwAutoLgtCstAvlFlg6 "Cargo Bed View Auto Lighting Customization Availability Flag 6";
BA_ "SignalType" SG_ 1170 CrgBedVwAutoLgtCstAvlFlg5 "ENM";
BA_ "SignalLongName" SG_ 1170 CrgBedVwAutoLgtCstAvlFlg5 "Cargo Bed View Auto Lighting Customization Availability Flag 5";
BA_ "SignalType" SG_ 1170 CrgBedVwAutoLgtCstAvlFlg4 "ENM";
BA_ "SignalLongName" SG_ 1170 CrgBedVwAutoLgtCstAvlFlg4 "Cargo Bed View Auto Lighting Customization Availability Flag 4";
BA_ "SignalType" SG_ 1170 CrgBedVwAutoLgtCstAvlFlg3 "ENM";
BA_ "SignalLongName" SG_ 1170 CrgBedVwAutoLgtCstAvlFlg3 "Cargo Bed View Auto Lighting Customization Availability Flag 3";
BA_ "SignalType" SG_ 1170 CrgBedVwAutoLgtCstAvlFlg2 "ENM";
BA_ "SignalLongName" SG_ 1170 CrgBedVwAutoLgtCstAvlFlg2 "Cargo Bed View Auto Lighting Customization Availability Flag 2";
BA_ "SignalType" SG_ 1170 CrgBedVwAutoLgtCstAvlFlg1 "ENM";
BA_ "SignalLongName" SG_ 1170 CrgBedVwAutoLgtCstAvlFlg1 "Cargo Bed View Auto Lighting Customization Availability Flag 1";
BA_ "SignalType" SG_ 1170 RrVwPrkAstSymCsAvlFlg2 "ENM";
BA_ "SignalLongName" SG_ 1170 RrVwPrkAstSymCsAvlFlg2 "RearViewParkAssistSymbolCustomizationAvailabilityFlag2";
BA_ "SignalType" SG_ 1170 RrVwPrkAstSymCsAvlFlg1 "ENM";
BA_ "SignalLongName" SG_ 1170 RrVwPrkAstSymCsAvlFlg1 "RearViewParkAssistSymbolCustomizationAvailabilityFlag1";
BA_ "SignalType" SG_ 1170 JckKnfDtnCstAvlFlg7 "ENM";
BA_ "SignalLongName" SG_ 1170 JckKnfDtnCstAvlFlg7 "Jack Knife Detection Customization Availability Flag 7";
BA_ "SignalType" SG_ 1170 JckKnfDtnCstAvlFlg6 "ENM";
BA_ "SignalLongName" SG_ 1170 JckKnfDtnCstAvlFlg6 "Jack Knife Detection Customization Availability Flag 6";
BA_ "SignalType" SG_ 1170 JckKnfDtnCstAvlFlg5 "ENM";
BA_ "SignalLongName" SG_ 1170 JckKnfDtnCstAvlFlg5 "Jack Knife Detection Customization Availability Flag 5";
BA_ "SignalType" SG_ 1170 JckKnfDtnCstAvlFlg4 "ENM";
BA_ "SignalLongName" SG_ 1170 JckKnfDtnCstAvlFlg4 "Jack Knife Detection Customization Availability Flag 4";
BA_ "SignalType" SG_ 1170 JckKnfDtnCstAvlFlg3 "ENM";
BA_ "SignalLongName" SG_ 1170 JckKnfDtnCstAvlFlg3 "Jack Knife Detection Customization Availability Flag 3";
BA_ "SignalType" SG_ 1170 JckKnfDtnCstAvlFlg2 "ENM";
BA_ "SignalLongName" SG_ 1170 JckKnfDtnCstAvlFlg2 "Jack Knife Detection Customization Availability Flag 2";
BA_ "SignalType" SG_ 1170 SrrndVwLghtCsAvlFlg3 "ENM";
BA_ "SignalLongName" SG_ 1170 SrrndVwLghtCsAvlFlg3 "Surround View Lighting Customization Availability Flag 3";
BA_ "SignalType" SG_ 1170 SrrndVwLghtCsAvlFlg2 "ENM";
BA_ "SignalLongName" SG_ 1170 SrrndVwLghtCsAvlFlg2 "Surround View Lighting Customization Availability Flag 2";
BA_ "SignalType" SG_ 1170 SrrndVwLghtCsAvlFlg1 "ENM";
BA_ "SignalLongName" SG_ 1170 SrrndVwLghtCsAvlFlg1 "Surround View Lighting Customization Availability Flag 1";
BA_ "SignalType" SG_ 1170 RrVwPrkAstSymCsAvlFlg7 "ENM";
BA_ "SignalLongName" SG_ 1170 RrVwPrkAstSymCsAvlFlg7 "RearViewParkAssistSymbolCustomizationAvailabilityFlag7";
BA_ "SignalType" SG_ 1170 RrVwPrkAstSymCsAvlFlg6 "ENM";
BA_ "SignalLongName" SG_ 1170 RrVwPrkAstSymCsAvlFlg6 "RearViewParkAssistSymbolCustomizationAvailabilityFlag6";
BA_ "SignalType" SG_ 1170 RrVwPrkAstSymCsAvlFlg5 "ENM";
BA_ "SignalLongName" SG_ 1170 RrVwPrkAstSymCsAvlFlg5 "RearViewParkAssistSymbolCustomizationAvailabilityFlag5";
BA_ "SignalType" SG_ 1170 RrVwPrkAstSymCsAvlFlg4 "ENM";
BA_ "SignalLongName" SG_ 1170 RrVwPrkAstSymCsAvlFlg4 "RearViewParkAssistSymbolCustomizationAvailabilityFlag4";
BA_ "SignalType" SG_ 1170 RrVwPrkAstSymCsAvlFlg3 "ENM";
BA_ "SignalLongName" SG_ 1170 RrVwPrkAstSymCsAvlFlg3 "RearViewParkAssistSymbolCustomizationAvailabilityFlag3";
BA_ "SignalType" SG_ 1170 TrlrMirVidEnblCstAvlFlg4 "ENM";
BA_ "SignalLongName" SG_ 1170 TrlrMirVidEnblCstAvlFlg4 "Trailering Mirror Video Enable Customization Availability Flag 4";
BA_ "SignalType" SG_ 1170 TrlrMirVidEnblCstAvlFlg3 "ENM";
BA_ "SignalLongName" SG_ 1170 TrlrMirVidEnblCstAvlFlg3 "Trailering Mirror Video Enable Customization Availability Flag 3";
BA_ "SignalType" SG_ 1170 TrlrMirVidEnblCstAvlFlg2 "ENM";
BA_ "SignalLongName" SG_ 1170 TrlrMirVidEnblCstAvlFlg2 "Trailering Mirror Video Enable Customization Availability Flag 2";
BA_ "SignalType" SG_ 1170 TrlrMirVidEnblCstAvlFlg1 "ENM";
BA_ "SignalLongName" SG_ 1170 TrlrMirVidEnblCstAvlFlg1 "Trailering Mirror Video Enable Customization Availability Flag 1";
BA_ "SignalType" SG_ 1170 SrrndVwLghtCsAvlFlg7 "ENM";
BA_ "SignalLongName" SG_ 1170 SrrndVwLghtCsAvlFlg7 "Surround View Lighting Customization Availability Flag 7";
BA_ "SignalType" SG_ 1170 SrrndVwLghtCsAvlFlg6 "ENM";
BA_ "SignalLongName" SG_ 1170 SrrndVwLghtCsAvlFlg6 "Surround View Lighting Customization Availability Flag 6";
BA_ "SignalType" SG_ 1170 SrrndVwLghtCsAvlFlg5 "ENM";
BA_ "SignalLongName" SG_ 1170 SrrndVwLghtCsAvlFlg5 "Surround View Lighting Customization Availability Flag 5";
BA_ "SignalType" SG_ 1170 SrrndVwLghtCsAvlFlg4 "ENM";
BA_ "SignalLongName" SG_ 1170 SrrndVwLghtCsAvlFlg4 "Surround View Lighting Customization Availability Flag 4";
BA_ "SignalType" SG_ 1170 TrlrMirVidGdlnsCstAvlFlg5 "ENM";
BA_ "SignalLongName" SG_ 1170 TrlrMirVidGdlnsCstAvlFlg5 "Trailering Mirror Video Guidelines Customization Availability Flag 5";
BA_ "SignalType" SG_ 1170 TrlrMirVidGdlnsCstAvlFlg4 "ENM";
BA_ "SignalLongName" SG_ 1170 TrlrMirVidGdlnsCstAvlFlg4 "Trailering Mirror Video Guidelines Customization Availability Flag 4";
BA_ "SignalType" SG_ 1170 TrlrMirVidGdlnsCstAvlFlg3 "ENM";
BA_ "SignalLongName" SG_ 1170 TrlrMirVidGdlnsCstAvlFlg3 "Trailering Mirror Video Guidelines Customization Availability Flag 3";
BA_ "SignalType" SG_ 1170 TrlrMirVidGdlnsCstAvlFlg2 "ENM";
BA_ "SignalLongName" SG_ 1170 TrlrMirVidGdlnsCstAvlFlg2 "Trailering Mirror Video Guidelines Customization Availability Flag 2";
BA_ "SignalType" SG_ 1170 TrlrMirVidGdlnsCstAvlFlg1 "ENM";
BA_ "SignalLongName" SG_ 1170 TrlrMirVidGdlnsCstAvlFlg1 "Trailering Mirror Video Guidelines Customization Availability Flag 1";
BA_ "SignalType" SG_ 1170 TrlrMirVidEnblCstAvlFlg7 "ENM";
BA_ "SignalLongName" SG_ 1170 TrlrMirVidEnblCstAvlFlg7 "Trailering Mirror Video Enable Customization Availability Flag 7";
BA_ "SignalType" SG_ 1170 TrlrMirVidEnblCstAvlFlg6 "ENM";
BA_ "SignalLongName" SG_ 1170 TrlrMirVidEnblCstAvlFlg6 "Trailering Mirror Video Enable Customization Availability Flag 6";
BA_ "SignalType" SG_ 1170 TrlrMirVidEnblCstAvlFlg5 "ENM";
BA_ "SignalLongName" SG_ 1170 TrlrMirVidEnblCstAvlFlg5 "Trailering Mirror Video Enable Customization Availability Flag 5";
BA_ "SignalType" SG_ 1170 TrlrMirVidGdlnsCstAvlFlg7 "ENM";
BA_ "SignalLongName" SG_ 1170 TrlrMirVidGdlnsCstAvlFlg7 "Trailering Mirror Video Guidelines Customization Availability Flag 7";
BA_ "SignalType" SG_ 1170 TrlrMirVidGdlnsCstAvlFlg6 "ENM";
BA_ "SignalLongName" SG_ 1170 TrlrMirVidGdlnsCstAvlFlg6 "Trailering Mirror Video Guidelines Customization Availability Flag 6";
BA_ "SignalLongName" SG_ 1195 IndTmpStngLvlFR "Indication Temperature Setting Level Front Right";
BA_ "SignalLongName" SG_ 1195 IndTmpStngLvlFL "Indication Temperature Setting Level Front Left";
BA_ "SignalLongName" SG_ 1195 IndTmpStngLvlRL "Indication Temperature Setting Level Rear Left";
BA_ "SignalLongName" SG_ 1195 IndTmpStngLvlRR "Indication Temperature Setting Level Rear Right";
BA_ "SignalType" SG_ 1195 IndTmpStngStFR "ENM";
BA_ "SignalLongName" SG_ 1195 IndTmpStngStFR "Indication Temperature Setting State Front Right";
BA_ "SignalType" SG_ 1195 IndTmpStngStFL "ENM";
BA_ "SignalLongName" SG_ 1195 IndTmpStngStFL "Indication Temperature Setting State Front Left";
BA_ "SignalType" SG_ 1195 IndTmpStngStRR "ENM";
BA_ "SignalLongName" SG_ 1195 IndTmpStngStRR "Indication Temperature Setting State Rear Right";
BA_ "SignalType" SG_ 1195 IndTmpStngStRL "ENM";
BA_ "SignalLongName" SG_ 1195 IndTmpStngStRL "Indication Temperature Setting State Rear Left";
BA_ "SignalType" SG_ 1195 NoRtDetWrngChmEvSt "ENM";
BA_ "SignalLongName" SG_ 1195 NoRtDetWrngChmEvSt "No Remote Detected Warning Chime Event State";
BA_ "SignalType" SG_ 1195 ManlPrkLmpChmEvtSt "ENM";
BA_ "SignalLongName" SG_ 1195 ManlPrkLmpChmEvtSt "Manual Parklamps On ChimeEventState";
BA_ "SignalType" SG_ 1195 LDCLDlydLkChmEvSt "ENM";
BA_ "SignalLongName" SG_ 1195 LDCLDlydLkChmEvSt "Last Door Closed Locking Delayed Locking Chime Event State";
BA_ "SignalType" SG_ 1195 KeyInRmdrChmEvntSt "ENM";
BA_ "SignalLongName" SG_ 1195 KeyInRmdrChmEvntSt "Key In Reminder Chime Event State";
BA_ "SignalType" SG_ 1195 PwrRrClsrObstclChmEvntStat "ENM";
BA_ "SignalLongName" SG_ 1195 PwrRrClsrObstclChmEvntStat "Power Rear Closure Obstacle Chime Event State";
BA_ "SignalType" SG_ 1195 PwrRrClsrNtfnChmEvntStat "ENM";
BA_ "SignalLongName" SG_ 1195 PwrRrClsrNtfnChmEvntStat "Power Rear Closure Notification Chime Event State";
BA_ "SignalType" SG_ 1195 PwrRrClsrNormOpChmEvntStat "ENM";
BA_ "SignalLongName" SG_ 1195 PwrRrClsrNormOpChmEvntStat "Power Rear Closure Normal Operation Chime Event State";
BA_ "SignalType" SG_ 1195 OneSidedPrkLmpActvnChmEvtSt "ENM";
BA_ "SignalLongName" SG_ 1195 OneSidedPrkLmpActvnChmEvtSt "OneSidedParkLampActivationChimeEventState";
BA_ "SignalType" SG_ 1195 StrgLckd "ENM";
BA_ "SignalLongName" SG_ 1195 StrgLckd "Storage Locked";
BA_ "SignalType" SG_ 1195 WlkAwyLkInhbtChmEvSt "ENM";
BA_ "SignalLongName" SG_ 1195 WlkAwyLkInhbtChmEvSt "Walk Away Lock Inhibit Chime Request";
BA_ "SignalType" SG_ 1195 ShfttoPrkChmEvntSt "ENM";
BA_ "SignalLongName" SG_ 1195 ShfttoPrkChmEvntSt "Shift To Park Chime Event State";
BA_ "SignalType" SG_ 1195 RemLtInVhWrngChmEvSt "ENM";
BA_ "SignalLongName" SG_ 1195 RemLtInVhWrngChmEvSt "Remote Left In Vehicle Warning Chime Event State";
BA_ "SignalType" SG_ 1196 IndAirDstFR "ENM";
BA_ "SignalLongName" SG_ 1196 IndAirDstFR "Indication Air Distribution Front Right";
BA_ "SignalType" SG_ 1196 IndAirDstFL "ENM";
BA_ "SignalLongName" SG_ 1196 IndAirDstFL "Indication Air Distribution Front Left";
BA_ "SignalLongName" SG_ 1196 IndBlwStngLvlRr "Indication Blower Setting Level Rear";
BA_ "SignalLongName" SG_ 1196 IndBlwStngLvlFrt "Indication Blower Setting Level Front";
BA_ "SignalType" SG_ 1196 IndBlwStngStFrt "ENM";
BA_ "SignalLongName" SG_ 1196 IndBlwStngStFrt "Indication Blower Setting State Front";
BA_ "SignalType" SG_ 1196 IndRecircStng "ENM";
BA_ "SignalLongName" SG_ 1196 IndRecircStng "Indication Recirculation Setting";
BA_ "SignalType" SG_ 1196 IndCompStng "ENM";
BA_ "SignalLongName" SG_ 1196 IndCompStng "Indication Compressor Setting";
BA_ "SignalType" SG_ 1196 IndClmMdStng "ENM";
BA_ "SignalLongName" SG_ 1196 IndClmMdStng "Indication Climate Mode Setting";
BA_ "SignalType" SG_ 1196 IndBlwStngStRr "ENM";
BA_ "SignalLongName" SG_ 1196 IndBlwStngStRr "Indication Blower Setting State Rear";
BA_ "SignalType" SG_ 1196 IndAirDstRL "ENM";
BA_ "SignalLongName" SG_ 1196 IndAirDstRL "Indication Air Distribution Rear Left";
BA_ "SignalType" SG_ 1196 IndSYNC_Rr "ENM";
BA_ "SignalLongName" SG_ 1196 IndSYNC_Rr "Indication SYNC Rear";
BA_ "SignalType" SG_ 1196 IndSYNC_All "ENM";
BA_ "SignalLongName" SG_ 1196 IndSYNC_All "Indication SYNC All";
BA_ "SignalType" SG_ 1196 IndRrWndDfgStng "ENM";
BA_ "SignalLongName" SG_ 1196 IndRrWndDfgStng "Indication Rear Window Defog Setting";
BA_ "SignalType" SG_ 1196 IndRrHVAC_On "ENM";
BA_ "SignalLongName" SG_ 1196 IndRrHVAC_On "Indication Rear HVAC On";
BA_ "SignalType" SG_ 1196 IndRrHVAC_Lckd "ENM";
BA_ "SignalLongName" SG_ 1196 IndRrHVAC_Lckd "Indication Rear HVAC Locked";
BA_ "SignalType" SG_ 1196 IndHtdFrtWshldSet "ENM";
BA_ "SignalLongName" SG_ 1196 IndHtdFrtWshldSet "Indication Heated Front Windshield Setting";
BA_ "SignalType" SG_ 1196 IndFrtHVAC_On "ENM";
BA_ "SignalLongName" SG_ 1196 IndFrtHVAC_On "Indication Front HVAC On";
BA_ "SignalType" SG_ 1196 IndAirDstRR "ENM";
BA_ "SignalLongName" SG_ 1196 IndAirDstRR "Indication Air Distribution Rear Right";
BA_ "SignalLongName" SG_ 1171 DslExhFldRmnDist "Diesel Exhaust Fluid Remaining Distance";
BA_ "SignalType" SG_ 1171 DslExhFldRmnDist_Inv "ENM";
BA_ "SignalLongName" SG_ 1171 DslExhFldRmnDist_Inv "Diesel Exhaust Fluid Remaining Distance Invalid";
BA_ "SignalLongName" SG_ 1171 DslExhFluidDistTIndcmt "Diesel Exhaust Fluid Distance To Inducement";
BA_ "SignalLongName" SG_ 1171 FuelTotCap "Fuel Total Capacity";
BA_ "SignalLongName" SG_ 1171 FuelTotCapTnk2 "Fuel Total Capacity Tank 2";
BA_ "SignalLongName" SG_ 1350 FI_FiltdDispTotFlLvlPct "Fuel Information : Filtered Display Total Fuel Level Percent";
BA_ "SignalLongName" SG_ 1350 FI_FiltdDispTotFlLvlTnk2Pct "Fuel Information : Filtered Display Total Fuel Level Tank 2 Percent";
BA_ "SignalType" SG_ 1350 FI_FiltdDispTotFlLvlPct_Inv "ENM";
BA_ "SignalLongName" SG_ 1350 FI_FiltdDispTotFlLvlPct_Inv "Fuel Information : Filtered Display Total Fuel Level Percent Invalid";
BA_ "SignalType" SG_ 1350 FI_FiltdDispTotFlLvlTnk2Pct_Inv "ENM";
BA_ "SignalLongName" SG_ 1350 FI_FiltdDispTotFlLvlTnk2Pct_Inv "Fuel Information : Filtered Display Total Fuel Level Tank 2 Percent Invalid";
BA_ "SignalLongName" SG_ 1350 FI_CS "Fuel Information : Checksum";
BA_ "SignalLongName" SG_ 1350 FI_ARC "Fuel Information : Alive Rolling Count";
BA_ "SignalLongName" SG_ 1206 EngIntAirTmp "Engine Intake Air Temperature";
BA_ "SignalType" SG_ 1206 EngIntAirTmp_Inv "ENM";
BA_ "SignalLongName" SG_ 1206 EngIntAirTmp_Inv "Engine Intake Air Temperature Invalid";
BA_ "SignalType" SG_ 1206 ASIRI_Ind08 "ENM";
BA_ "SignalLongName" SG_ 1206 ASIRI_Ind08 "Auto Stop Inhibit Reason Indication : Indication 8";
BA_ "SignalType" SG_ 1206 ASIRI_Ind06 "ENM";
BA_ "SignalLongName" SG_ 1206 ASIRI_Ind06 "Auto Stop Inhibit Reason Indication : Indication 6";
BA_ "SignalType" SG_ 1206 ASIRI_Ind04 "ENM";
BA_ "SignalLongName" SG_ 1206 ASIRI_Ind04 "Auto Stop Inhibit Reason Indication : Indication 4";
BA_ "SignalType" SG_ 1206 ASIRI_Ind01 "ENM";
BA_ "SignalLongName" SG_ 1206 ASIRI_Ind01 "Auto Stop Inhibit Reason Indication : Indication 1";
BA_ "SignalType" SG_ 1206 ASIRI_Ind05 "ENM";
BA_ "SignalLongName" SG_ 1206 ASIRI_Ind05 "Auto Stop Inhibit Reason Indication : Indication 5";
BA_ "SignalType" SG_ 1206 ASIRI_Ind07 "ENM";
BA_ "SignalLongName" SG_ 1206 ASIRI_Ind07 "Auto Stop Inhibit Reason Indication : Indication 7";
BA_ "SignalType" SG_ 1206 ASIRI_Ind02 "ENM";
BA_ "SignalLongName" SG_ 1206 ASIRI_Ind02 "Auto Stop Inhibit Reason Indication : Indication 2";
BA_ "SignalType" SG_ 1206 VhSpdCntlSystmTyp "ENM";
BA_ "SignalLongName" SG_ 1206 VhSpdCntlSystmTyp "Vehicle Speed Control System Type";
BA_ "SignalType" SG_ 1206 MnlTrnsIndReq "ENM";
BA_ "SignalLongName" SG_ 1206 MnlTrnsIndReq "Manual Transmission Indication Request";
BA_ "SignalType" SG_ 1206 EngEmsRltMlfIndRq "ENM";
BA_ "SignalLongName" SG_ 1206 EngEmsRltMlfIndRq "Engine Emissions Related Malfunction Indication Request";
BA_ "SignalType" SG_ 1206 ASIRI_Ind03 "ENM";
BA_ "SignalLongName" SG_ 1206 ASIRI_Ind03 "Auto Stop Inhibit Reason Indication : Indication 3";
BA_ "SignalType" SG_ 1206 ElecShfPriTransCtlrMalfIndOn "ENM";
BA_ "SignalLongName" SG_ 1206 ElecShfPriTransCtlrMalfIndOn "Electronic Shift Primary Transmission Controller Malfunction Indication On";
BA_ "SignalType" SG_ 1206 ElecShfPriShfToDrvTryAgnIndOn "ENM";
BA_ "SignalLongName" SG_ 1206 ElecShfPriShfToDrvTryAgnIndOn "Electronic Shift Primary Shift To Drive Try Again Indication On";
BA_ "SignalType" SG_ 1206 EngCmptHotWrnIndReq "ENM";
BA_ "SignalLongName" SG_ 1206 EngCmptHotWrnIndReq "Engine Compartment Hot Warning Indication Request";
BA_ "SignalType" SG_ 1206 ElecShftPrTwoGrsSelIndRq "ENM";
BA_ "SignalLongName" SG_ 1206 ElecShftPrTwoGrsSelIndRq "Electronic Shift Primary Two Gears Selected Indication Request";
BA_ "SignalType" SG_ 1206 ElecShftPrLtdPrfMdIO "ENM";
BA_ "SignalLongName" SG_ 1206 ElecShftPrLtdPrfMdIO "Electronic Shift Primary Limited Performance Mode Indication On";
BA_ "SignalType" SG_ 1206 ElecShftPrHldShftLevEngRngIO "ENM";
BA_ "SignalLongName" SG_ 1206 ElecShftPrHldShftLevEngRngIO "Electronic Shift Primary Hold Shift Lever to Engage Range Indication On";
BA_ "SignalType" SG_ 1206 ElecShftPrDrPrkIntShftAtmpIO "ENM";
BA_ "SignalLongName" SG_ 1206 ElecShftPrDrPrkIntShftAtmpIO "Electronic Shift Primary Driver Park Interlock Shift Attempted Indication On";
BA_ "SignalType" SG_ 1206 ElecShftPrDrIntShftAtmpIO "ENM";
BA_ "SignalLongName" SG_ 1206 ElecShftPrDrIntShftAtmpIO "Electronic Shift Primary Driver Interlock Shift Attempted Indication On";
BA_ "SignalType" SG_ 1206 ElecShftPrDrExitIO "ENM";
BA_ "SignalLongName" SG_ 1206 ElecShftPrDrExitIO "Electronic Shift Primary Driver Exit Indication On";
BA_ "SignalType" SG_ 1206 ElecShftPrDrDoorStIndIO "ENM";
BA_ "SignalLongName" SG_ 1206 ElecShftPrDrDoorStIndIO "ETRS Driver Door State Indeterminate Indication On";
BA_ "SignalType" SG_ 1206 ElecShftPrAtPrkIO "ENM";
BA_ "SignalLongName" SG_ 1206 ElecShftPrAtPrkIO "Electronic Shift Primary Auto Park Indication On";
BA_ "SignalType" SG_ 1206 ElecShfPriTrnVehOffForPrkIndOn "ENM";
BA_ "SignalLongName" SG_ 1206 ElecShfPriTrnVehOffForPrkIndOn "Electronic Shift Primary Turn Vehicle Off For Park Indication On";
BA_ "SignalType" SG_ 1206 EngOilChngIO "ENM";
BA_ "SignalLongName" SG_ 1206 EngOilChngIO "Engine Oil Change Indication On";
BA_ "SignalType" SG_ 1206 EngNEmsnsRltMlfnAct "ENM";
BA_ "SignalLongName" SG_ 1206 EngNEmsnsRltMlfnAct "Engine Non Emissions Related Malfunction Active";
BA_ "SignalType" SG_ 1206 EngHtStpEngIO "ENM";
BA_ "SignalLongName" SG_ 1206 EngHtStpEngIO "Engine Hot / Stop Engine Indication On";
BA_ "SignalType" SG_ 1206 EngHtFlEnrchmntIO "ENM";
BA_ "SignalLongName" SG_ 1206 EngHtFlEnrchmntIO "Engine Hot Fuel Enrichment Indication On";
BA_ "SignalType" SG_ 1206 EngCstFlCtOffAct "ENM";
BA_ "SignalLongName" SG_ 1206 EngCstFlCtOffAct "Engine Coast Fuel Cut Off Active";
BA_ "SignalType" SG_ 1206 ElecShftPrTrnMlfIO "ENM";
BA_ "SignalLongName" SG_ 1206 ElecShftPrTrnMlfIO "Electronic Shift Primary Transmission Malfunction Indication On";
BA_ "SignalType" SG_ 1206 ElecShftPrRngInvRqIO "ENM";
BA_ "SignalLongName" SG_ 1206 ElecShftPrRngInvRqIO "Electronic Shift Primary Range Invalid Request Indication On";
BA_ "SignalType" SG_ 1206 ElecShftPrPrkInvRqIO "ENM";
BA_ "SignalLongName" SG_ 1206 ElecShftPrPrkInvRqIO "Electronic Shift Primary Park Invalid Request Indication On";
BA_ "SignalType" SG_ 1206 GenFld "ENM";
BA_ "SignalLongName" SG_ 1206 GenFld "Generator Failed";
BA_ "SignalType" SG_ 1206 EngWtrInFlIO "ENM";
BA_ "SignalLongName" SG_ 1206 EngWtrInFlIO "Engine Water In Fuel Indication On";
BA_ "SignalType" SG_ 1206 EngSpdLmtnMdAct "ENM";
BA_ "SignalLongName" SG_ 1206 EngSpdLmtnMdAct "Engine Speed Limitation Mode Active";
BA_ "SignalType" SG_ 1206 EngShtdwnPndgIO "ENM";
BA_ "SignalLongName" SG_ 1206 EngShtdwnPndgIO "Engine Shutdown Pending Indication On";
BA_ "SignalType" SG_ 1206 EngOilStrvtnIO "ENM";
BA_ "SignalLongName" SG_ 1206 EngOilStrvtnIO "Engine Oil Starvation Indication On";
BA_ "SignalType" SG_ 1206 EngOilPrsLwIO "ENM";
BA_ "SignalLongName" SG_ 1206 EngOilPrsLwIO "Engine Oil Pressure Low Indication On";
BA_ "SignalType" SG_ 1206 EngOilLvlLwIO "ENM";
BA_ "SignalLongName" SG_ 1206 EngOilLvlLwIO "Engine Oil Level Low Indication On";
BA_ "SignalType" SG_ 1206 EngOilHotIO "ENM";
BA_ "SignalLongName" SG_ 1206 EngOilHotIO "Engine Oil Hot Indication On";
BA_ "SignalType" SG_ 1206 TrnsSkpShftIO "ENM";
BA_ "SignalLongName" SG_ 1206 TrnsSkpShftIO "Transmission Skip Shift Indication On";
BA_ "SignalType" SG_ 1206 PTWrmgWtToShftIO "ENM";
BA_ "SignalLongName" SG_ 1206 PTWrmgWtToShftIO "Powertrain Warming Wait to Shift Indication On";
BA_ "SignalType" SG_ 1206 PTExPrtclFltrWrnIO "ENM";
BA_ "SignalLongName" SG_ 1206 PTExPrtclFltrWrnIO "Powertrain Exhaust Particle Filter Warning Indication On";
BA_ "SignalType" SG_ 1206 PTExPrtclFltrWrn2IO "ENM";
BA_ "SignalLongName" SG_ 1206 PTExPrtclFltrWrn2IO "Powertrain Exhaust Particle Filter Warning 2 Indication On";
BA_ "SignalLongName" SG_ 1207 CrsSpdLmtrDrvSelSpd "Cruise and Speed Limiter Driver Selected Speed";
BA_ "SignalType" SG_ 1207 DslExFldCnWrngIndRq "ENM";
BA_ "SignalLongName" SG_ 1207 DslExFldCnWrngIndRq "Diesel Exhaust Fluid Consumption Monitoring Warning Indication Request";
BA_ "SignalType" SG_ 1207 DslExNxEmWrngIndRq "ENM";
BA_ "SignalLongName" SG_ 1207 DslExNxEmWrngIndRq "Diesel Exhaust NOx Emissions Too High Warning Indication Request";
BA_ "SignalType" SG_ 1207 DslExFldTpWrngIndRq "ENM";
BA_ "SignalLongName" SG_ 1207 DslExFldTpWrngIndRq "Diesel Exhaust Fluid Tampering Warning Indication Request";
BA_ "SignalType" SG_ 1207 DslExhFldWrngIdRqER "ENM";
BA_ "SignalLongName" SG_ 1207 DslExhFldWrngIdRqER "Diesel Exhaust Fluid Level Warning Indication Request Extended Range";
BA_ "SignalType" SG_ 1207 DslExhFldQlyWrngIReq "ENM";
BA_ "SignalLongName" SG_ 1207 DslExhFldQlyWrngIReq "Diesel Exhaust Fluid Quality Warning Indication Request";
BA_ "SignalType" SG_ 1207 DslExhFldDiagWrnIdRq "ENM";
BA_ "SignalLongName" SG_ 1207 DslExhFldDiagWrnIdRq "Diesel Exhaust Fluid System Diagnostic Warning Indication Request";
BA_ "SignalType" SG_ 1207 DrvrSeltdSpdLmtrIndReq "ENM";
BA_ "SignalLongName" SG_ 1207 DrvrSeltdSpdLmtrIndReq "Driver Selected Speed Limiter Indication Request";
BA_ "SignalType" SG_ 1207 CnvntlCruzCtlIndReq "ENM";
BA_ "SignalLongName" SG_ 1207 CnvntlCruzCtlIndReq "Conventional Cruise Control Indication Request";
BA_ "SignalType" SG_ 1207 ACCompCmnd "ENM";
BA_ "SignalLongName" SG_ 1207 ACCompCmnd "Air Conditioning Compressor Command";
BA_ "SignalType" SG_ 1207 DslEmnsOBDMrkt "ENM";
BA_ "SignalLongName" SG_ 1207 DslEmnsOBDMrkt "Diesel Emissions OBD Market";
BA_ "SignalType" SG_ 1207 DrSlctdSpdLmtrStSpdLmtRchd "ENM";
BA_ "SignalLongName" SG_ 1207 DrSlctdSpdLmtrStSpdLmtRchd "Driver Selected Speed Limiter Set Speed Limit Reached";
BA_ "SignalType" SG_ 1207 DrSlctdSpdLmtrSetTypActv "ENM";
BA_ "SignalLongName" SG_ 1207 DrSlctdSpdLmtrSetTypActv "Driver Selected Speed Limiter Setting Type Active";
BA_ "SignalType" SG_ 1207 ElecShfPriRdcSpdForReqdShfIndOn "ENM";
BA_ "SignalLongName" SG_ 1207 ElecShfPriRdcSpdForReqdShfIndOn "Electronic Shift Primary Reduce Speed For Requested Shift Indication On";
BA_ "SignalType" SG_ 1207 CbnHtrWrmUpIndOn "ENM";
BA_ "SignalLongName" SG_ 1207 CbnHtrWrmUpIndOn "Cabin Heater Warm Up Indication On";
BA_ "SignalType" SG_ 1207 DrSlctdSpdLmtrEnbld "ENM";
BA_ "SignalLongName" SG_ 1207 DrSlctdSpdLmtrEnbld "Driver Selected Speed Limiter Enabled";
BA_ "SignalType" SG_ 1207 DrSlctdSpdLmtrActv "ENM";
BA_ "SignalLongName" SG_ 1207 DrSlctdSpdLmtrActv "Driver Selected Speed Limiter Active";
BA_ "SignalType" SG_ 1207 CkFlFilrCapIO "ENM";
BA_ "SignalLongName" SG_ 1207 CkFlFilrCapIO "Check Fuel Filler Cap Indication On";
BA_ "SignalType" SG_ 1207 Bat12VSysUnStab "ENM";
BA_ "SignalLongName" SG_ 1207 Bat12VSysUnStab "Battery 12V System Unstable";
BA_ "SignalType" SG_ 1207 AppCltchAutSrtIO "ENM";
BA_ "SignalLongName" SG_ 1207 AppCltchAutSrtIO "Apply Clutch For Automatic Start Indication On";
BA_ "SignalType" SG_ 1207 AirCndOffIO "ENM";
BA_ "SignalLongName" SG_ 1207 AirCndOffIO "Air Conditioning Off Indication On";
BA_ "SignalType" SG_ 1173 EBDFld "ENM";
BA_ "SignalLongName" SG_ 1173 EBDFld "Electronic Brake Distribution Failed";
BA_ "SignalType" SG_ 1173 CustMdTrcStbCstmAvFlg7 "ENM";
BA_ "SignalLongName" SG_ 1173 CustMdTrcStbCstmAvFlg7 "Custom Mode Traction Stability Customization Availability Flag 7";
BA_ "SignalType" SG_ 1173 CustMdTrcStbCstmAvFlg6 "ENM";
BA_ "SignalLongName" SG_ 1173 CustMdTrcStbCstmAvFlg6 "Custom Mode Traction Stability Customization Availability Flag 6";
BA_ "SignalType" SG_ 1173 CustMdTrcStbCstmAvFlg5 "ENM";
BA_ "SignalLongName" SG_ 1173 CustMdTrcStbCstmAvFlg5 "Custom Mode Traction Stability Customization Availability Flag 5";
BA_ "SignalType" SG_ 1173 CustMdTrcStbCstmAvFlg4 "ENM";
BA_ "SignalLongName" SG_ 1173 CustMdTrcStbCstmAvFlg4 "Custom Mode Traction Stability Customization Availability Flag 4";
BA_ "SignalType" SG_ 1173 CustMdTrcStbCstmAvFlg3 "ENM";
BA_ "SignalLongName" SG_ 1173 CustMdTrcStbCstmAvFlg3 "Custom Mode Traction Stability Customization Availability Flag 3";
BA_ "SignalType" SG_ 1173 CustMdTrcStbCstmAvFlg2 "ENM";
BA_ "SignalLongName" SG_ 1173 CustMdTrcStbCstmAvFlg2 "Custom Mode Traction Stability Customization Availability Flag 2";
BA_ "SignalType" SG_ 1173 CustMdTrcStbCstmAvFlg1 "ENM";
BA_ "SignalLongName" SG_ 1173 CustMdTrcStbCstmAvFlg1 "Custom Mode Traction Stability Customization Availability Flag 1";
BA_ "SignalType" SG_ 1173 PrsnlMdActAeroCstmAvFlg1 "ENM";
BA_ "SignalLongName" SG_ 1173 PrsnlMdActAeroCstmAvFlg1 "Personal Mode Active Aero Customization Availability Flag 1";
BA_ "SignalType" SG_ 1173 ExtdHillStrtAstCustAvlFlg7 "ENM";
BA_ "SignalLongName" SG_ 1173 ExtdHillStrtAstCustAvlFlg7 "Extended Hill Start Assist Customization Availability Flag 7";
BA_ "SignalType" SG_ 1173 ExtdHillStrtAstCustAvlFlg6 "ENM";
BA_ "SignalLongName" SG_ 1173 ExtdHillStrtAstCustAvlFlg6 "Extended Hill Start Assist Customization Availability Flag 6";
BA_ "SignalType" SG_ 1173 ExtdHillStrtAstCustAvlFlg5 "ENM";
BA_ "SignalLongName" SG_ 1173 ExtdHillStrtAstCustAvlFlg5 "Extended Hill Start Assist Customization Availability Flag 5";
BA_ "SignalType" SG_ 1173 ExtdHillStrtAstCustAvlFlg4 "ENM";
BA_ "SignalLongName" SG_ 1173 ExtdHillStrtAstCustAvlFlg4 "Extended Hill Start Assist Customization Availability Flag 4";
BA_ "SignalType" SG_ 1173 ExtdHillStrtAstCustAvlFlg3 "ENM";
BA_ "SignalLongName" SG_ 1173 ExtdHillStrtAstCustAvlFlg3 "Extended Hill Start Assist Customization Availability Flag 3";
BA_ "SignalType" SG_ 1173 ExtdHillStrtAstCustAvlFlg2 "ENM";
BA_ "SignalLongName" SG_ 1173 ExtdHillStrtAstCustAvlFlg2 "Extended Hill Start Assist Customization Availability Flag 2";
BA_ "SignalType" SG_ 1173 ExtdHillStrtAstCustAvlFlg1 "ENM";
BA_ "SignalLongName" SG_ 1173 ExtdHillStrtAstCustAvlFlg1 "Extended Hill Start Assist Customization Availability Flag 1";
BA_ "SignalType" SG_ 1173 PrsnlMdBrkPdlCstmAvFlg2 "ENM";
BA_ "SignalLongName" SG_ 1173 PrsnlMdBrkPdlCstmAvFlg2 "Personal Mode Brake Pedal Customization Availability Flag 2";
BA_ "SignalType" SG_ 1173 PrsnlMdBrkPdlCstmAvFlg1 "ENM";
BA_ "SignalLongName" SG_ 1173 PrsnlMdBrkPdlCstmAvFlg1 "Personal Mode Brake Pedal Customization Availability Flag 1";
BA_ "SignalType" SG_ 1173 PrsnlMdActAeroCstmAvFlg7 "ENM";
BA_ "SignalLongName" SG_ 1173 PrsnlMdActAeroCstmAvFlg7 "Personal Mode Active Aero Customization Availability Flag 7";
BA_ "SignalType" SG_ 1173 PrsnlMdActAeroCstmAvFlg6 "ENM";
BA_ "SignalLongName" SG_ 1173 PrsnlMdActAeroCstmAvFlg6 "Personal Mode Active Aero Customization Availability Flag 6";
BA_ "SignalType" SG_ 1173 PrsnlMdActAeroCstmAvFlg5 "ENM";
BA_ "SignalLongName" SG_ 1173 PrsnlMdActAeroCstmAvFlg5 "Personal Mode Active Aero Customization Availability Flag 5";
BA_ "SignalType" SG_ 1173 PrsnlMdActAeroCstmAvFlg4 "ENM";
BA_ "SignalLongName" SG_ 1173 PrsnlMdActAeroCstmAvFlg4 "Personal Mode Active Aero Customization Availability Flag 4";
BA_ "SignalType" SG_ 1173 PrsnlMdActAeroCstmAvFlg3 "ENM";
BA_ "SignalLongName" SG_ 1173 PrsnlMdActAeroCstmAvFlg3 "Personal Mode Active Aero Customization Availability Flag 3";
BA_ "SignalType" SG_ 1173 PrsnlMdActAeroCstmAvFlg2 "ENM";
BA_ "SignalLongName" SG_ 1173 PrsnlMdActAeroCstmAvFlg2 "Personal Mode Active Aero Customization Availability Flag 2";
BA_ "SignalType" SG_ 1173 PrsnlMdDrvlCstmAvFlg3 "ENM";
BA_ "SignalLongName" SG_ 1173 PrsnlMdDrvlCstmAvFlg3 "Personal Mode Driveline Customization Availability Flag 3";
BA_ "SignalType" SG_ 1173 PrsnlMdDrvlCstmAvFlg2 "ENM";
BA_ "SignalLongName" SG_ 1173 PrsnlMdDrvlCstmAvFlg2 "Personal Mode Driveline Customization Availability Flag 2";
BA_ "SignalType" SG_ 1173 PrsnlMdDrvlCstmAvFlg1 "ENM";
BA_ "SignalLongName" SG_ 1173 PrsnlMdDrvlCstmAvFlg1 "Personal Mode Driveline Customization Availability Flag 1";
BA_ "SignalType" SG_ 1173 PrsnlMdBrkPdlCstmAvFlg7 "ENM";
BA_ "SignalLongName" SG_ 1173 PrsnlMdBrkPdlCstmAvFlg7 "Personal Mode Brake Pedal Customization Availability Flag 7";
BA_ "SignalType" SG_ 1173 PrsnlMdBrkPdlCstmAvFlg6 "ENM";
BA_ "SignalLongName" SG_ 1173 PrsnlMdBrkPdlCstmAvFlg6 "Personal Mode Brake Pedal Customization Availability Flag 6";
BA_ "SignalType" SG_ 1173 PrsnlMdBrkPdlCstmAvFlg5 "ENM";
BA_ "SignalLongName" SG_ 1173 PrsnlMdBrkPdlCstmAvFlg5 "Personal Mode Brake Pedal Customization Availability Flag 5";
BA_ "SignalType" SG_ 1173 PrsnlMdBrkPdlCstmAvFlg4 "ENM";
BA_ "SignalLongName" SG_ 1173 PrsnlMdBrkPdlCstmAvFlg4 "Personal Mode Brake Pedal Customization Availability Flag 4";
BA_ "SignalType" SG_ 1173 PrsnlMdBrkPdlCstmAvFlg3 "ENM";
BA_ "SignalLongName" SG_ 1173 PrsnlMdBrkPdlCstmAvFlg3 "Personal Mode Brake Pedal Customization Availability Flag 3";
BA_ "SignalType" SG_ 1173 PrsnlMdRideHghtCstmAvFlg4 "ENM";
BA_ "SignalLongName" SG_ 1173 PrsnlMdRideHghtCstmAvFlg4 "Personal Mode Ride Height Customization Availability Flag 4";
BA_ "SignalType" SG_ 1173 PrsnlMdRideHghtCstmAvFlg3 "ENM";
BA_ "SignalLongName" SG_ 1173 PrsnlMdRideHghtCstmAvFlg3 "Personal Mode Ride Height Customization Availability Flag 3";
BA_ "SignalType" SG_ 1173 PrsnlMdRideHghtCstmAvFlg2 "ENM";
BA_ "SignalLongName" SG_ 1173 PrsnlMdRideHghtCstmAvFlg2 "Personal Mode Ride Height Customization Availability Flag 2";
BA_ "SignalType" SG_ 1173 PrsnlMdRideHghtCstmAvFlg1 "ENM";
BA_ "SignalLongName" SG_ 1173 PrsnlMdRideHghtCstmAvFlg1 "Personal Mode Ride Height Customization Availability Flag 1";
BA_ "SignalType" SG_ 1173 PrsnlMdDrvlCstmAvFlg7 "ENM";
BA_ "SignalLongName" SG_ 1173 PrsnlMdDrvlCstmAvFlg7 "Personal Mode Driveline Customization Availability Flag 7";
BA_ "SignalType" SG_ 1173 PrsnlMdDrvlCstmAvFlg6 "ENM";
BA_ "SignalLongName" SG_ 1173 PrsnlMdDrvlCstmAvFlg6 "Personal Mode Driveline Customization Availability Flag 6";
BA_ "SignalType" SG_ 1173 PrsnlMdDrvlCstmAvFlg5 "ENM";
BA_ "SignalLongName" SG_ 1173 PrsnlMdDrvlCstmAvFlg5 "Personal Mode Driveline Customization Availability Flag 5";
BA_ "SignalType" SG_ 1173 PrsnlMdDrvlCstmAvFlg4 "ENM";
BA_ "SignalLongName" SG_ 1173 PrsnlMdDrvlCstmAvFlg4 "Personal Mode Driveline Customization Availability Flag 4";
BA_ "SignalType" SG_ 1173 PrsnlMdSndCstmAvFlg5 "ENM";
BA_ "SignalLongName" SG_ 1173 PrsnlMdSndCstmAvFlg5 "Personal Mode Sound Customization Availability Flag 5";
BA_ "SignalType" SG_ 1173 PrsnlMdSndCstmAvFlg4 "ENM";
BA_ "SignalLongName" SG_ 1173 PrsnlMdSndCstmAvFlg4 "Personal Mode Sound Customization Availability Flag 4";
BA_ "SignalType" SG_ 1173 PrsnlMdSndCstmAvFlg3 "ENM";
BA_ "SignalLongName" SG_ 1173 PrsnlMdSndCstmAvFlg3 "Personal Mode Sound Customization Availability Flag 3";
BA_ "SignalType" SG_ 1173 PrsnlMdSndCstmAvFlg2 "ENM";
BA_ "SignalLongName" SG_ 1173 PrsnlMdSndCstmAvFlg2 "Personal Mode Sound Customization Availability Flag 2";
BA_ "SignalType" SG_ 1173 PrsnlMdSndCstmAvFlg1 "ENM";
BA_ "SignalLongName" SG_ 1173 PrsnlMdSndCstmAvFlg1 "Personal Mode Sound Customization Availability Flag 1";
BA_ "SignalType" SG_ 1173 PrsnlMdRideHghtCstmAvFlg7 "ENM";
BA_ "SignalLongName" SG_ 1173 PrsnlMdRideHghtCstmAvFlg7 "Personal Mode Ride Height Customization Availability Flag 7";
BA_ "SignalType" SG_ 1173 PrsnlMdRideHghtCstmAvFlg6 "ENM";
BA_ "SignalLongName" SG_ 1173 PrsnlMdRideHghtCstmAvFlg6 "Personal Mode Ride Height Customization Availability Flag 6";
BA_ "SignalType" SG_ 1173 PrsnlMdRideHghtCstmAvFlg5 "ENM";
BA_ "SignalLongName" SG_ 1173 PrsnlMdRideHghtCstmAvFlg5 "Personal Mode Ride Height Customization Availability Flag 5";
BA_ "SignalType" SG_ 1173 PrsnlMdSpnCstmAvFlg6 "ENM";
BA_ "SignalLongName" SG_ 1173 PrsnlMdSpnCstmAvFlg6 "Personal Mode Suspension Customization Availability Flag 6";
BA_ "SignalType" SG_ 1173 PrsnlMdSpnCstmAvFlg5 "ENM";
BA_ "SignalLongName" SG_ 1173 PrsnlMdSpnCstmAvFlg5 "Personal Mode Suspension Customization Availability Flag 5";
BA_ "SignalType" SG_ 1173 PrsnlMdSpnCstmAvFlg4 "ENM";
BA_ "SignalLongName" SG_ 1173 PrsnlMdSpnCstmAvFlg4 "Personal Mode Suspension Customization Availability Flag 4";
BA_ "SignalType" SG_ 1173 PrsnlMdSpnCstmAvFlg3 "ENM";
BA_ "SignalLongName" SG_ 1173 PrsnlMdSpnCstmAvFlg3 "Personal Mode Suspension Customization Availability Flag 3";
BA_ "SignalType" SG_ 1173 PrsnlMdSpnCstmAvFlg2 "ENM";
BA_ "SignalLongName" SG_ 1173 PrsnlMdSpnCstmAvFlg2 "Personal Mode Suspension Customization Availability Flag 2";
BA_ "SignalType" SG_ 1173 PrsnlMdSpnCstmAvFlg1 "ENM";
BA_ "SignalLongName" SG_ 1173 PrsnlMdSpnCstmAvFlg1 "Personal Mode Suspension Customization Availability Flag 1";
BA_ "SignalType" SG_ 1173 PrsnlMdSndCstmAvFlg7 "ENM";
BA_ "SignalLongName" SG_ 1173 PrsnlMdSndCstmAvFlg7 "Personal Mode Sound Customization Availability Flag 7";
BA_ "SignalType" SG_ 1173 PrsnlMdSndCstmAvFlg6 "ENM";
BA_ "SignalLongName" SG_ 1173 PrsnlMdSndCstmAvFlg6 "Personal Mode Sound Customization Availability Flag 6";
BA_ "SignalType" SG_ 1173 PrsnlMdStrCstmAvFlg7 "ENM";
BA_ "SignalLongName" SG_ 1173 PrsnlMdStrCstmAvFlg7 "Personal Mode Steering Customization Availability Flag 7";
BA_ "SignalType" SG_ 1173 PrsnlMdStrCstmAvFlg6 "ENM";
BA_ "SignalLongName" SG_ 1173 PrsnlMdStrCstmAvFlg6 "Personal Mode Steering Customization Availability Flag 6";
BA_ "SignalType" SG_ 1173 PrsnlMdStrCstmAvFlg5 "ENM";
BA_ "SignalLongName" SG_ 1173 PrsnlMdStrCstmAvFlg5 "Personal Mode Steering Customization Availability Flag 5";
BA_ "SignalType" SG_ 1173 PrsnlMdStrCstmAvFlg4 "ENM";
BA_ "SignalLongName" SG_ 1173 PrsnlMdStrCstmAvFlg4 "Personal Mode Steering Customization Availability Flag 4";
BA_ "SignalType" SG_ 1173 PrsnlMdStrCstmAvFlg3 "ENM";
BA_ "SignalLongName" SG_ 1173 PrsnlMdStrCstmAvFlg3 "Personal Mode Steering Customization Availability Flag 3";
BA_ "SignalType" SG_ 1173 PrsnlMdStrCstmAvFlg2 "ENM";
BA_ "SignalLongName" SG_ 1173 PrsnlMdStrCstmAvFlg2 "Personal Mode Steering Customization Availability Flag 2";
BA_ "SignalType" SG_ 1173 PrsnlMdStrCstmAvFlg1 "ENM";
BA_ "SignalLongName" SG_ 1173 PrsnlMdStrCstmAvFlg1 "Personal Mode Steering Customization Availability Flag 1";
BA_ "SignalType" SG_ 1173 PrsnlMdSpnCstmAvFlg7 "ENM";
BA_ "SignalLongName" SG_ 1173 PrsnlMdSpnCstmAvFlg7 "Personal Mode Suspension Customization Availability Flag 7";
BA_ "SignalType" SG_ 1174 CustMdActAeroCstmAvFlg6 "ENM";
BA_ "SignalLongName" SG_ 1174 CustMdActAeroCstmAvFlg6 "Custom Mode Active Aero Customization Availability Flag 6";
BA_ "SignalType" SG_ 1174 CustMdActAeroCstmAvFlg5 "ENM";
BA_ "SignalLongName" SG_ 1174 CustMdActAeroCstmAvFlg5 "Custom Mode Active Aero Customization Availability Flag 5";
BA_ "SignalType" SG_ 1174 CustMdActAeroCstmAvFlg4 "ENM";
BA_ "SignalLongName" SG_ 1174 CustMdActAeroCstmAvFlg4 "Custom Mode Active Aero Customization Availability Flag 4";
BA_ "SignalType" SG_ 1174 CustMdActAeroCstmAvFlg3 "ENM";
BA_ "SignalLongName" SG_ 1174 CustMdActAeroCstmAvFlg3 "Custom Mode Active Aero Customization Availability Flag 3";
BA_ "SignalType" SG_ 1174 CustMdActAeroCstmAvFlg2 "ENM";
BA_ "SignalLongName" SG_ 1174 CustMdActAeroCstmAvFlg2 "Custom Mode Active Aero Customization Availability Flag 2";
BA_ "SignalType" SG_ 1174 CustMdActAeroCstmAvFlg1 "ENM";
BA_ "SignalLongName" SG_ 1174 CustMdActAeroCstmAvFlg1 "Custom Mode Active Aero Customization Availability Flag 1";
BA_ "SignalType" SG_ 1174 BrkFldLvlSt "ENM";
BA_ "SignalLongName" SG_ 1174 BrkFldLvlSt "Brake Fluid Level Status";
BA_ "SignalType" SG_ 1174 CustMdBrkPdlCstmAvFlg7 "ENM";
BA_ "SignalLongName" SG_ 1174 CustMdBrkPdlCstmAvFlg7 "Custom Mode Brake Pedal Customization Availability Flag 7";
BA_ "SignalType" SG_ 1174 CustMdBrkPdlCstmAvFlg6 "ENM";
BA_ "SignalLongName" SG_ 1174 CustMdBrkPdlCstmAvFlg6 "Custom Mode Brake Pedal Customization Availability Flag 6";
BA_ "SignalType" SG_ 1174 CustMdBrkPdlCstmAvFlg5 "ENM";
BA_ "SignalLongName" SG_ 1174 CustMdBrkPdlCstmAvFlg5 "Custom Mode Brake Pedal Customization Availability Flag 5";
BA_ "SignalType" SG_ 1174 CustMdBrkPdlCstmAvFlg4 "ENM";
BA_ "SignalLongName" SG_ 1174 CustMdBrkPdlCstmAvFlg4 "Custom Mode Brake Pedal Customization Availability Flag 4";
BA_ "SignalType" SG_ 1174 CustMdBrkPdlCstmAvFlg3 "ENM";
BA_ "SignalLongName" SG_ 1174 CustMdBrkPdlCstmAvFlg3 "Custom Mode Brake Pedal Customization Availability Flag 3";
BA_ "SignalType" SG_ 1174 CustMdBrkPdlCstmAvFlg2 "ENM";
BA_ "SignalLongName" SG_ 1174 CustMdBrkPdlCstmAvFlg2 "Custom Mode Brake Pedal Customization Availability Flag 2";
BA_ "SignalType" SG_ 1174 CustMdBrkPdlCstmAvFlg1 "ENM";
BA_ "SignalLongName" SG_ 1174 CustMdBrkPdlCstmAvFlg1 "Custom Mode Brake Pedal Customization Availability Flag 1";
BA_ "SignalType" SG_ 1174 CustMdActAeroCstmAvFlg7 "ENM";
BA_ "SignalLongName" SG_ 1174 CustMdActAeroCstmAvFlg7 "Custom Mode Active Aero Customization Availability Flag 7";
BA_ "SignalType" SG_ 1174 CustMdPTCstmAvFlg1 "ENM";
BA_ "SignalLongName" SG_ 1174 CustMdPTCstmAvFlg1 "Custom Mode Powertrain Customization Availability Flag 1";
BA_ "SignalType" SG_ 1174 CustMdDrvlCstmAvFlg7 "ENM";
BA_ "SignalLongName" SG_ 1174 CustMdDrvlCstmAvFlg7 "Custom Mode Driveline Customization Availability Flag 7";
BA_ "SignalType" SG_ 1174 CustMdDrvlCstmAvFlg6 "ENM";
BA_ "SignalLongName" SG_ 1174 CustMdDrvlCstmAvFlg6 "Custom Mode Driveline Customization Availability Flag 6";
BA_ "SignalType" SG_ 1174 CustMdDrvlCstmAvFlg5 "ENM";
BA_ "SignalLongName" SG_ 1174 CustMdDrvlCstmAvFlg5 "Custom Mode Driveline Customization Availability Flag 5";
BA_ "SignalType" SG_ 1174 CustMdDrvlCstmAvFlg4 "ENM";
BA_ "SignalLongName" SG_ 1174 CustMdDrvlCstmAvFlg4 "Custom Mode Driveline Customization Availability Flag 4";
BA_ "SignalType" SG_ 1174 CustMdDrvlCstmAvFlg3 "ENM";
BA_ "SignalLongName" SG_ 1174 CustMdDrvlCstmAvFlg3 "Custom Mode Driveline Customization Availability Flag 3";
BA_ "SignalType" SG_ 1174 CustMdDrvlCstmAvFlg2 "ENM";
BA_ "SignalLongName" SG_ 1174 CustMdDrvlCstmAvFlg2 "Custom Mode Driveline Customization Availability Flag 2";
BA_ "SignalType" SG_ 1174 CustMdDrvlCstmAvFlg1 "ENM";
BA_ "SignalLongName" SG_ 1174 CustMdDrvlCstmAvFlg1 "Custom Mode Driveline Customization Availability Flag 1";
BA_ "SignalType" SG_ 1174 CustMdRideHghtCstmAvFlg2 "ENM";
BA_ "SignalLongName" SG_ 1174 CustMdRideHghtCstmAvFlg2 "Custom Mode Ride Height Customization Availability Flag 2";
BA_ "SignalType" SG_ 1174 CustMdRideHghtCstmAvFlg1 "ENM";
BA_ "SignalLongName" SG_ 1174 CustMdRideHghtCstmAvFlg1 "Custom Mode Ride Height Customization Availability Flag 1";
BA_ "SignalType" SG_ 1174 CustMdPTCstmAvFlg7 "ENM";
BA_ "SignalLongName" SG_ 1174 CustMdPTCstmAvFlg7 "Custom Mode Powertrain Customization Availability Flag 7";
BA_ "SignalType" SG_ 1174 CustMdPTCstmAvFlg6 "ENM";
BA_ "SignalLongName" SG_ 1174 CustMdPTCstmAvFlg6 "Custom Mode Powertrain Customization Availability Flag 6";
BA_ "SignalType" SG_ 1174 CustMdPTCstmAvFlg5 "ENM";
BA_ "SignalLongName" SG_ 1174 CustMdPTCstmAvFlg5 "Custom Mode Powertrain Customization Availability Flag 5";
BA_ "SignalType" SG_ 1174 CustMdPTCstmAvFlg4 "ENM";
BA_ "SignalLongName" SG_ 1174 CustMdPTCstmAvFlg4 "Custom Mode Powertrain Customization Availability Flag 4";
BA_ "SignalType" SG_ 1174 CustMdPTCstmAvFlg3 "ENM";
BA_ "SignalLongName" SG_ 1174 CustMdPTCstmAvFlg3 "Custom Mode Powertrain Customization Availability Flag 3";
BA_ "SignalType" SG_ 1174 CustMdPTCstmAvFlg2 "ENM";
BA_ "SignalLongName" SG_ 1174 CustMdPTCstmAvFlg2 "Custom Mode Powertrain Customization Availability Flag 2";
BA_ "SignalType" SG_ 1174 CustMdSndCstmAvFlg3 "ENM";
BA_ "SignalLongName" SG_ 1174 CustMdSndCstmAvFlg3 "Custom Mode Sound Customization Availability Flag 3";
BA_ "SignalType" SG_ 1174 CustMdSndCstmAvFlg2 "ENM";
BA_ "SignalLongName" SG_ 1174 CustMdSndCstmAvFlg2 "Custom Mode Sound Customization Availability Flag 2";
BA_ "SignalType" SG_ 1174 CustMdSndCstmAvFlg1 "ENM";
BA_ "SignalLongName" SG_ 1174 CustMdSndCstmAvFlg1 "Custom Mode Sound Customization Availability Flag 1";
BA_ "SignalType" SG_ 1174 CustMdRideHghtCstmAvFlg7 "ENM";
BA_ "SignalLongName" SG_ 1174 CustMdRideHghtCstmAvFlg7 "Custom Mode Ride Height Customization Availability Flag 7";
BA_ "SignalType" SG_ 1174 CustMdRideHghtCstmAvFlg6 "ENM";
BA_ "SignalLongName" SG_ 1174 CustMdRideHghtCstmAvFlg6 "Custom Mode Ride Height Customization Availability Flag 6";
BA_ "SignalType" SG_ 1174 CustMdRideHghtCstmAvFlg5 "ENM";
BA_ "SignalLongName" SG_ 1174 CustMdRideHghtCstmAvFlg5 "Custom Mode Ride Height Customization Availability Flag 5";
BA_ "SignalType" SG_ 1174 CustMdRideHghtCstmAvFlg4 "ENM";
BA_ "SignalLongName" SG_ 1174 CustMdRideHghtCstmAvFlg4 "Custom Mode Ride Height Customization Availability Flag 4";
BA_ "SignalType" SG_ 1174 CustMdRideHghtCstmAvFlg3 "ENM";
BA_ "SignalLongName" SG_ 1174 CustMdRideHghtCstmAvFlg3 "Custom Mode Ride Height Customization Availability Flag 3";
BA_ "SignalType" SG_ 1174 CustMdSpnCstmAvFlg4 "ENM";
BA_ "SignalLongName" SG_ 1174 CustMdSpnCstmAvFlg4 "Custom Mode Suspension Customization Availability Flag 4";
BA_ "SignalType" SG_ 1174 CustMdSpnCstmAvFlg3 "ENM";
BA_ "SignalLongName" SG_ 1174 CustMdSpnCstmAvFlg3 "Custom Mode Suspension Customization Availability Flag 3";
BA_ "SignalType" SG_ 1174 CustMdSpnCstmAvFlg2 "ENM";
BA_ "SignalLongName" SG_ 1174 CustMdSpnCstmAvFlg2 "Custom Mode Suspension Customization Availability Flag 2";
BA_ "SignalType" SG_ 1174 CustMdSpnCstmAvFlg1 "ENM";
BA_ "SignalLongName" SG_ 1174 CustMdSpnCstmAvFlg1 "Custom Mode Suspension Customization Availability Flag 1";
BA_ "SignalType" SG_ 1174 CustMdSndCstmAvFlg7 "ENM";
BA_ "SignalLongName" SG_ 1174 CustMdSndCstmAvFlg7 "Custom Mode Sound Customization Availability Flag 7";
BA_ "SignalType" SG_ 1174 CustMdSndCstmAvFlg6 "ENM";
BA_ "SignalLongName" SG_ 1174 CustMdSndCstmAvFlg6 "Custom Mode Sound Customization Availability Flag 6";
BA_ "SignalType" SG_ 1174 CustMdSndCstmAvFlg5 "ENM";
BA_ "SignalLongName" SG_ 1174 CustMdSndCstmAvFlg5 "Custom Mode Sound Customization Availability Flag 5";
BA_ "SignalType" SG_ 1174 CustMdSndCstmAvFlg4 "ENM";
BA_ "SignalLongName" SG_ 1174 CustMdSndCstmAvFlg4 "Custom Mode Sound Customization Availability Flag 4";
BA_ "SignalType" SG_ 1174 CustMdStrCstmAvFlg5 "ENM";
BA_ "SignalLongName" SG_ 1174 CustMdStrCstmAvFlg5 "Custom Mode Steering Customization Availability Flag 5";
BA_ "SignalType" SG_ 1174 CustMdStrCstmAvFlg4 "ENM";
BA_ "SignalLongName" SG_ 1174 CustMdStrCstmAvFlg4 "Custom Mode Steering Customization Availability Flag 4";
BA_ "SignalType" SG_ 1174 CustMdStrCstmAvFlg3 "ENM";
BA_ "SignalLongName" SG_ 1174 CustMdStrCstmAvFlg3 "Custom Mode Steering Customization Availability Flag 3";
BA_ "SignalType" SG_ 1174 CustMdStrCstmAvFlg2 "ENM";
BA_ "SignalLongName" SG_ 1174 CustMdStrCstmAvFlg2 "Custom Mode Steering Customization Availability Flag 2";
BA_ "SignalType" SG_ 1174 CustMdStrCstmAvFlg1 "ENM";
BA_ "SignalLongName" SG_ 1174 CustMdStrCstmAvFlg1 "Custom Mode Steering Customization Availability Flag 1";
BA_ "SignalType" SG_ 1174 CustMdSpnCstmAvFlg7 "ENM";
BA_ "SignalLongName" SG_ 1174 CustMdSpnCstmAvFlg7 "Custom Mode Suspension Customization Availability Flag 7";
BA_ "SignalType" SG_ 1174 CustMdSpnCstmAvFlg6 "ENM";
BA_ "SignalLongName" SG_ 1174 CustMdSpnCstmAvFlg6 "Custom Mode Suspension Customization Availability Flag 6";
BA_ "SignalType" SG_ 1174 CustMdSpnCstmAvFlg5 "ENM";
BA_ "SignalLongName" SG_ 1174 CustMdSpnCstmAvFlg5 "Custom Mode Suspension Customization Availability Flag 5";
BA_ "SignalType" SG_ 1174 CustMdStrCstmAvFlg7 "ENM";
BA_ "SignalLongName" SG_ 1174 CustMdStrCstmAvFlg7 "Custom Mode Steering Customization Availability Flag 7";
BA_ "SignalType" SG_ 1174 CustMdStrCstmAvFlg6 "ENM";
BA_ "SignalLongName" SG_ 1174 CustMdStrCstmAvFlg6 "Custom Mode Steering Customization Availability Flag 6";
VAL_ 1342 DTCI_WCM_CnfrmdDTC 0 "FALSE" 1 "TRUE" ;
VAL_ 1342 DTCI_WCM_DTCFaultType 0 "Not Supported" 1 "Type A" 2 "Type B" 3 "Type C" ;
VAL_ 1342 DTCI_WCM_TstNCmpltdOpCyc 0 "FALSE" 1 "TRUE" ;
VAL_ 1342 DTCI_WCM_TstNCmpltdLstClr 0 "FALSE" 1 "TRUE" ;
VAL_ 1342 DTCI_WCM_TstFldOpCyc 0 "FALSE" 1 "TRUE" ;
VAL_ 1342 DTCI_WCM_TstFldLstClr 0 "FALSE" 1 "TRUE" ;
VAL_ 1342 DTCI_WCM_TstFld 0 "FALSE" 1 "TRUE" ;
VAL_ 1342 DTCI_WCM_PndngDTC 0 "FALSE" 1 "TRUE" ;
VAL_ 1342 DTCI_WCM_DTCTriggered 0 "FALSE" 1 "TRUE" ;
VAL_ 1342 DTCI_WCM_WrnIndTrggrd 0 "FALSE" 1 "TRUE" ;
VAL_ 1342 DTCI_WCM_WrnIndRqd 0 "FALSE" 1 "TRUE" ;
VAL_ 1083 DDIP_SecAxl4WDAWDNonEmMlfIOAuth 0 "FALSE" 1 "TRUE" ;
VAL_ 1083 DDIP_SecAxl4WDAWDTmpInhbIOAuth 0 "FALSE" 1 "TRUE" ;
VAL_ 1083 DDIP_4AndAllWhlDrvIndReqAuth 0 "No Indication" 1 "Two Wheel Drive High Pending" 2 "Two Wheel Drive High Active" 3 "Four Wheel Drive High Auto Pending" 4 "Four Wheel Drive High Auto Active" 5 "Four Wheel Drive High Lock Pending" 6 "Four Wheel Drive High Lock Active" 7 "Four Wheel Drive Low Lock Pending" 8 "Four Wheel Drive Low Lock Active" 9 "Transfer Case Neutral Pending" 10 "Transfer Case Neutral Active" 11 "Position Undetermined Active" 12 "AWD Connected Mode Pending" 13 "AWD Connected Mode Active" 14 "Front Wheel Drive Mode Pending" 15 "Front Wheel Drive Mode Active" ;
VAL_ 56 ElecMtrASpd_Inv 0 "FALSE" 1 "TRUE" ;
VAL_ 1052 ESRSDP_ElecShftRngSecDispAuth 0 "No Display" 1 "Park Nominal" 2 "Reverse Nominal" 3 "Neutral Nominal" 4 "Drive Nominal" 5 "Low Nominal" 6 "Manual Nominal" 7 "Park Requested And In Progress" 8 "Reverse Requested And In Progress" 9 "Neutral Requested And In Progress" 10 "Drive Requested And In Progress" 11 "Manual Requested And In Progress" 12 "Park Requested And Denied" ;
VAL_ 591 ESCLP_StrgColLckdIndOnAuth 0 "FALSE" 1 "TRUE" ;
VAL_ 591 ESCLP_ServColLckIndOnAuth 0 "FALSE" 1 "TRUE" ;
VAL_ 591 ESCLP_ElecStrgColLckStsAuth 0 "Locked" 1 "Inbetween" 2 "Unlocked" 3 "Unknown" ;
VAL_ 55 EngActStdyStTrq_Inv 0 "FALSE" 1 "TRUE" ;
VAL_ 55 DslGlwPlgIO 0 "FALSE" 1 "TRUE" ;
VAL_ 55 ArbdEngTemp_Inv 0 "FALSE" 1 "TRUE" ;
VAL_ 605 ESVTSP_EnhdSrvsVhTpSpLimReqAuth 0 "No Action" 1 "Active" 2 "Inactive" ;
VAL_ 1031 FTPP_FrtCmptAjrWrnIndOnAuth 0 "FALSE" 1 "TRUE" ;
VAL_ 1031 FTPP_FrtCmptFaildToOpnIndOnAuth 0 "FALSE" 1 "TRUE" ;
VAL_ 1031 FTPP_TirePresLoIndOnAuth 0 "FALSE" 1 "TRUE" ;
VAL_ 1031 FTPP_TirePrsRFAuth_Inv 0 "FALSE" 1 "TRUE" ;
VAL_ 1031 FTPP_TirePrsLFAuth_Inv 0 "FALSE" 1 "TRUE" ;
VAL_ 1031 FTPP_ServWprSysCtlIndOnAuth 0 "FALSE" 1 "TRUE" ;
VAL_ 617 GPSQM_PPSAbsVelErrEst_Inv 0 "FALSE" 1 "TRUE" ;
VAL_ 617 GPSQM_PPSMode 0 "GNSS Standalone" 1 "GNSS and SBAS" 2 "GNSS and RTX" 3 "GNSS and DR" 4 "GNSS and SBAS and DR" 5 "GNSS and RTX and DR" 6 "DR ONLY" 7 "GNSS and RTX and DR and MM" ;
VAL_ 617 GPSQM_PPSPstnDilutnPrcsn_Inv 0 "FALSE" 1 "TRUE" ;
VAL_ 617 GPSQM_PPS2DAbsPstnErrEst_Inv 0 "FALSE" 1 "TRUE" ;
VAL_ 617 GPSQM_PPSMode_Inv 0 "FALSE" 1 "TRUE" ;
VAL_ 617 GPSQM_PPS3DAbsPstnErrEst_Inv 0 "FALSE" 1 "TRUE" ;
VAL_ 618 GPSC_PPSLat_Inv 0 "FALSE" 1 "TRUE" ;
VAL_ 618 GPSC_PPSLong_Inv 0 "FALSE" 1 "TRUE" ;
VAL_ 619 GPST_PPSCldrYr_Inv 0 "FALSE" 1 "TRUE" ;
VAL_ 619 GPST_PPSCldrDy_Inv 0 "FALSE" 1 "TRUE" ;
VAL_ 619 GPST_PPSTmOfDy_Inv 0 "FALSE" 1 "TRUE" ;
VAL_ 620 GPSV_PPSElvtn_Inv 0 "FALSE" 1 "TRUE" ;
VAL_ 620 GPSV_PPSCalcdSpd_Inv 0 "FALSE" 1 "TRUE" ;
VAL_ 620 GPSV_PPSHdg_Inv 0 "FALSE" 1 "TRUE" ;
VAL_ 1168 FrtRdHgtGPSCstAvlbltyFlg7 0 "FALSE" 1 "TRUE" ;
VAL_ 1168 FrtRdHgtGPSCstAvlbltyFlg6 0 "FALSE" 1 "TRUE" ;
VAL_ 1168 FrtRdHgtGPSCstAvlbltyFlg5 0 "FALSE" 1 "TRUE" ;
VAL_ 1168 FrtRdHgtGPSCstAvlbltyFlg4 0 "FALSE" 1 "TRUE" ;
VAL_ 1168 FrtRdHgtGPSCstAvlbltyFlg3 0 "FALSE" 1 "TRUE" ;
VAL_ 1168 FrtRdHgtGPSCstAvlbltyFlg2 0 "FALSE" 1 "TRUE" ;
VAL_ 1168 FrtRdHgtGPSCstAvlbltyFlg1 0 "FALSE" 1 "TRUE" ;
VAL_ 1231 APAWI_WrnIndReq 0 "OFF" 1 "SEARCHING_PARALLEL_RIGHT" 2 "SEARCHING_PARALLEL_LEFT" 3 "SEARCHING_CROSS_RIGHT" 4 "SEARCHING_CROSS_LEFT" 5 "SPOT_FOUND" 6 "SPOT_FOUND_PARALLEL_LEFT" 7 "SPOT_FOUND_CROSS_LEFT" 8 "SPOT_FOUND_PARALLEL_RIGHT" 9 "SPOT_FOUND_CROSS_RIGHT" 10 "MOVE_AHEAD" 11 "MOVE_AHEAD_PARALLEL_LEFT" 12 "MOVE_AHEAD_CROSS_LEFT" 13 "MOVE_AHEAD_PARALLEL_RIGHT" 14 "MOVE_AHEAD_CROSS_RIGHT" 15 "STOP_AND_R_PARALLEL_LEFT" 16 "STOP_AND_R_CROSS_BACK_LEFT" 17 "STOP_AND_R_CROSS_FRONT_LEFT" 18 "STOP_AND_R_PARALLEL_RIGHT" 19 "STOP_AND_R_CROSS_BACK_RIGHT" 20 "STOP_AND_R_CROSS_FRONT_RIGHT" 21 "SEARCH_SPEED_WARNING" 22 "SEARCH_DEACTIVATED" 23 "EXIT_PARK_TO_LEFT" 24 "EXIT_PARK_TO_RIGHT" 25 "SELECT_DRIVE_GEAR" 26 "AUTO_STEERING_ACTIVE" 27 "AUTO_PARKING_ACTIVE" 28 "DRIVE_BACKWARD" 29 "BACKWARD_MOVE" 30 "DRIVE_FORWARD" 31 "FORWARD_MOVE" 32 "STOP" 33 "SHIFTING" 34 "POSITION_REACHED" 35 "TAKE_CONTROL" 36 "PARKING_COMPLETE" 37 "EXIT_PARK_COMPLETE" 38 "DEACTIVATED" 39 "CANCELED_GENERAL" 40 "CANCELED_MOVES" 41 "CANCELED_SPEED" 42 "CANCELED_INTERFERENCE" 43 "CANCELED_EXIT_PARK" 44 "STOPPING" 45 "AUTO_PARKING_COMPLETE" 46 "RELEASE_BRAKE" 47 "RESERVED_01" 48 "RESERVED_02" 49 "RESERVED_03" 50 "RESERVED_04" 51 "RESERVED_05" 52 "RESERVED_06" 53 "RESERVED_07" 54 "RESERVED_08" 55 "RESERVED_09" ;
VAL_ 1231 APAWI_AutoStrgIconReq 0 "NO_ICON" 1 "ACTIVE" 2 "DEACTIVATED" ;
VAL_ 1231 APAWI_FcsReq 0 "NO_REQUEST" 1 "FOCUS_REQUEST_IPC" 2 "FOCUS_REQUEST_CSM" ;
VAL_ 1231 APALftSftBtnRqst 0 "HIDDEN" 1 "DISABLED" 2 "ENABLED" 3 "HIGHLIGHTED" ;
VAL_ 1231 APAExtPrkSftBtnRqst 0 "HIDDEN" 1 "DISABLED" 2 "ENABLED" 3 "HIGHLIGHTED" ;
VAL_ 1231 APACrssFrntInSftBtnRqst 0 "HIDDEN" 1 "DISABLED" 2 "ENABLED" 3 "HIGHLIGHTED" ;
VAL_ 1231 APACrssBckInSftBtnRqst 0 "HIDDEN" 1 "DISABLED" 2 "ENABLED" 3 "HIGHLIGHTED" ;
VAL_ 1231 APAVMR_NAvalIndOn 0 "FALSE" 1 "TRUE" ;
VAL_ 1231 APAVMR_SloDnIndOn 0 "FALSE" 1 "TRUE" ;
VAL_ 1231 APASrchSftBtnRqst 0 "HIDDEN" 1 "DISABLED" 2 "ENABLED" 3 "HIGHLIGHTED" ;
VAL_ 1231 APARghtSftBtnRqst 0 "HIDDEN" 1 "DISABLED" 2 "ENABLED" 3 "HIGHLIGHTED" ;
VAL_ 1231 APAPrllPrkSftBtnRqst 0 "HIDDEN" 1 "DISABLED" 2 "ENABLED" 3 "HIGHLIGHTED" ;
VAL_ 1232 DM2Name 0 "None" 1 "Tour" 2 "Sport" 3 "Track" 4 "Winter" 5 "Off Road" 6 "Tow/Haul" 7 "Hold" 8 "Mountain" 9 "Personal" 10 "Custom" 11 "AWD" 12 "Economy" 13 "Automatic" 14 "EV" 15 "grade braking" 16 "exhaust brake" 17 "active rev match" 18 "2WD" 19 "Comfort" 20 "start/stop disable" 21 "Crawl" 22 "Charge Plus" 23 "Reserved 1 - Reserved 9" ;
VAL_ 1232 DM1Name 0 "None" 1 "Tour" 2 "Sport" 3 "Track" 4 "Winter" 5 "Off Road" 6 "Tow/Haul" 7 "Hold" 8 "Mountain" 9 "Personal" 10 "Custom" 11 "AWD" 12 "Economy" 13 "Automatic" 14 "EV" 15 "grade braking" 16 "exhaust brake" 17 "active rev match" 18 "2WD" 19 "Comfort" 20 "start/stop disable" 21 "Crawl" 22 "Charge Plus" 23 "Reserved 1 - Reserved 9" ;
VAL_ 1232 DM4Name 0 "None" 1 "Tour" 2 "Sport" 3 "Track" 4 "Winter" 5 "Off Road" 6 "Tow/Haul" 7 "Hold" 8 "Mountain" 9 "Personal" 10 "Custom" 11 "AWD" 12 "Economy" 13 "Automatic" 14 "EV" 15 "grade braking" 16 "exhaust brake" 17 "active rev match" 18 "2WD" 19 "Comfort" 20 "start/stop disable" 21 "Crawl" 22 "Charge Plus" 23 "Reserved 1 - Reserved 9" ;
VAL_ 1232 DM3Name 0 "None" 1 "Tour" 2 "Sport" 3 "Track" 4 "Winter" 5 "Off Road" 6 "Tow/Haul" 7 "Hold" 8 "Mountain" 9 "Personal" 10 "Custom" 11 "AWD" 12 "Economy" 13 "Automatic" 14 "EV" 15 "grade braking" 16 "exhaust brake" 17 "active rev match" 18 "2WD" 19 "Comfort" 20 "start/stop disable" 21 "Crawl" 22 "Charge Plus" 23 "Reserved 1 - Reserved 9" ;
VAL_ 1232 DM5Name 0 "None" 1 "Tour" 2 "Sport" 3 "Track" 4 "Winter" 5 "Off Road" 6 "Tow/Haul" 7 "Hold" 8 "Mountain" 9 "Personal" 10 "Custom" 11 "AWD" 12 "Economy" 13 "Automatic" 14 "EV" 15 "grade braking" 16 "exhaust brake" 17 "active rev match" 18 "2WD" 19 "Comfort" 20 "start/stop disable" 21 "Crawl" 22 "Charge Plus" 23 "Reserved 1 - Reserved 9" ;
VAL_ 1232 DM7Name 0 "None" 1 "Tour" 2 "Sport" 3 "Track" 4 "Winter" 5 "Off Road" 6 "Tow/Haul" 7 "Hold" 8 "Mountain" 9 "Personal" 10 "Custom" 11 "AWD" 12 "Economy" 13 "Automatic" 14 "EV" 15 "grade braking" 16 "exhaust brake" 17 "active rev match" 18 "2WD" 19 "Comfort" 20 "start/stop disable" 21 "Crawl" 22 "Charge Plus" 23 "Reserved 1 - Reserved 9" ;
VAL_ 1232 DM6Name 0 "None" 1 "Tour" 2 "Sport" 3 "Track" 4 "Winter" 5 "Off Road" 6 "Tow/Haul" 7 "Hold" 8 "Mountain" 9 "Personal" 10 "Custom" 11 "AWD" 12 "Economy" 13 "Automatic" 14 "EV" 15 "grade braking" 16 "exhaust brake" 17 "active rev match" 18 "2WD" 19 "Comfort" 20 "start/stop disable" 21 "Crawl" 22 "Charge Plus" 23 "Reserved 1 - Reserved 9" ;
VAL_ 1232 DM8Name 0 "None" 1 "Tour" 2 "Sport" 3 "Track" 4 "Winter" 5 "Off Road" 6 "Tow/Haul" 7 "Hold" 8 "Mountain" 9 "Personal" 10 "Custom" 11 "AWD" 12 "Economy" 13 "Automatic" 14 "EV" 15 "grade braking" 16 "exhaust brake" 17 "active rev match" 18 "2WD" 19 "Comfort" 20 "start/stop disable" 21 "Crawl" 22 "Charge Plus" 23 "Reserved 1 - Reserved 9" ;
VAL_ 1232 DM6Status 0 "Inactive" 1 "Active" ;
VAL_ 1232 DM5Status 0 "Inactive" 1 "Active" ;
VAL_ 1232 DM4Status 0 "Inactive" 1 "Active" ;
VAL_ 1232 DM3Status 0 "Inactive" 1 "Active" ;
VAL_ 1232 DM2Status 0 "Inactive" 1 "Active" ;
VAL_ 1232 DM1Status 0 "Inactive" 1 "Active" ;
VAL_ 1232 EngCmptAjr 0 "FALSE" 1 "TRUE" ;
VAL_ 1232 EngCmptAjr_Inv 0 "FALSE" 1 "TRUE" ;
VAL_ 1232 FrtStrgeCmptAjr 0 "FALSE" 1 "TRUE" ;
VAL_ 1232 DM8Status 0 "Inactive" 1 "Active" ;
VAL_ 1232 DM7Status 0 "Inactive" 1 "Active" ;
VAL_ 1202 BrkPadLifeFrt_Inv 0 "FALSE" 1 "TRUE" ;
VAL_ 1202 BrkPadLifeRr_Inv 0 "FALSE" 1 "TRUE" ;
VAL_ 1202 ElecPrkBrkSysDisIndReq 0 "OFF" 1 "ALERT_1" 2 "ALERT_2" 3 "ALERT_3" 4 "ALERT_4" 5 "ALERT_5" 6 "ALERT_6" 7 "ALERT_7" ;
VAL_ 1202 EPBStpOnBrkToRelPrkBrkIndReq 0 "OFF" 1 "ON" 2 "0.5_Hz" 3 "1_Hz" 4 "2_Hz" 5 "4_Hz" 6 "RESERVED_1" 7 "RESERVED_2" ;
VAL_ 1202 BrkPadLifeStsIndReq 0 "No Action" 1 "Not Present" 2 "Ok" 3 "Change Soon" 4 "Change Now" 5 "Disabled" 6 "Service" ;
VAL_ 1202 AutoHldDsbldDrOpnIndOn 0 "FALSE" 1 "TRUE" ;
VAL_ 1202 AutoHldAppBrkPedIndOn 0 "FALSE" 1 "TRUE" ;
VAL_ 1202 AutoHldActv 0 "FALSE" 1 "TRUE" ;
VAL_ 1202 ABSActvIndOn 0 "FALSE" 1 "TRUE" ;
VAL_ 1202 PerfMdMainMenuTy 0 "No_Action" 1 "Main Menu Type 1" 2 "Main Menu Type 2" 3 "Main Menu Type 3" 4 "Main Menu Type 4" 5 "Main Menu Type 5" 6 "Main Menu Type 6" 7 "Main Menu Type 7" ;
VAL_ 1202 ESCOffIO 0 "FALSE" 1 "TRUE" ;
VAL_ 1202 ESCInitIO 0 "FALSE" 1 "TRUE" ;
VAL_ 1202 ESCCmptMdIO 0 "FALSE" 1 "TRUE" ;
VAL_ 1202 BrkPadWrnIO 0 "FALSE" 1 "TRUE" ;
VAL_ 1202 BrkPadLifeRrRstAval 0 "FALSE" 1 "TRUE" ;
VAL_ 1202 BrkPadLifeFrtRstAval 0 "FALSE" 1 "TRUE" ;
VAL_ 1202 AutoHldServIndOn 0 "FALSE" 1 "TRUE" ;
VAL_ 1202 AutoHldDsbldStBltIndOn 0 "FALSE" 1 "TRUE" ;
VAL_ 1202 TrlrStbAsstActIO 0 "FALSE" 1 "TRUE" ;
VAL_ 1202 SrvESCMdIO 0 "FALSE" 1 "TRUE" ;
VAL_ 1202 ServTracCtlIndOn 0 "FALSE" 1 "TRUE" ;
VAL_ 1202 HillStrtAstActIO 0 "FALSE" 1 "TRUE" ;
VAL_ 1202 HillRollCntrlActIO 0 "FALSE" 1 "TRUE" ;
VAL_ 1202 ESCPrfMdIO 0 "FALSE" 1 "TRUE" ;
VAL_ 1202 VehStbEnhcmntCustAv 0 "FALSE" 1 "TRUE" ;
VAL_ 1202 VehStbEnhcmntCurStat 0 "On" 1 "Off" ;
VAL_ 1202 VehStbCompMdCustAv 0 "FALSE" 1 "TRUE" ;
VAL_ 1202 VehStbCompMdCurStat 0 "On" 1 "Off" ;
VAL_ 1203 FllwgTmDsplyMd 0 "NO DISPLAY" 1 "DEFAULT" 2 "NORMAL" 3 "LESS THAN MINIMUM" 4 "GREATER THAN MAXIMUM" ;
VAL_ 1203 AdpAndCnvntlCruzCtlIndReq 0 "No Action" 1 "Cruise Control and Adaptive Cruise Control Telltale Off" 2 "Cruise Control Unavailable Telltale On" 3 "Cruise Control White Telltale On" 4 "Cruise Control Green Telltale On" 5 "Cruise Control Blue Telltale On" 6 "Adaptive Cruise Control Unavailable Telltale On" 7 "Adaptive Cruise Control White Telltale On" 8 "Adaptive Cruise Control Green Telltale On" 9 "Adaptive Cruise Control Blue Telltale On" ;
VAL_ 1203 LtAstStsIndRq 0 "No Indication" 1 "Off" 2 "LDW" 3 "LKA" 4 "HoLF" ;
VAL_ 1203 FCAGpSet 0 "FAR" 1 "MEDIUM" 2 "NEAR" 3 "OFF" 4 "UNKNOWN" 5 "FAULTED" ;
VAL_ 1203 LAOA_LatAsstLDWOptAval 0 "FALSE" 1 "TRUE" ;
VAL_ 1203 LAOA_LatAsstHoLFOptAval 0 "FALSE" 1 "TRUE" ;
VAL_ 1203 LAOA_LatAsstLKAOptAval 0 "FALSE" 1 "TRUE" ;
VAL_ 1203 LAOA_LatAsstOffOptAval 0 "FALSE" 1 "TRUE" ;
VAL_ 1203 PdWrnIndRqst 0 "OFF" 1 "PEDESTRIAN ADVISORY" 2 "PEDESTRIAN ALERT" 3 "RESERVED" ;
VAL_ 1203 FrwdHdwyVisIndCtl 0 "FCA" 1 "ACC" 2 "None" ;
VAL_ 1203 ACCHdwySttng 0 "FAR" 1 "MEDIUM" 2 "NEAR" ;
VAL_ 1203 FCA_ACCGapSetIndOn 0 "FALSE" 1 "TRUE" ;
VAL_ 1203 ACCTmpUnvIndOn 0 "FALSE" 1 "TRUE" ;
VAL_ 1203 ACCSysSlctdMdDspIndOn 0 "FALSE" 1 "TRUE" ;
VAL_ 1203 ACCShftToPrkBfrExIndOn 0 "FALSE" 1 "TRUE" ;
VAL_ 1203 ACCRtSpdAdVsIndOn 0 "FALSE" 1 "TRUE" ;
VAL_ 1203 ACCHdwySttngIndOn 0 "FALSE" 1 "TRUE" ;
VAL_ 1203 ACCDsngIndOn 0 "FALSE" 1 "TRUE" ;
VAL_ 1203 ACCDrSlctdSpdIndOn 0 "FALSE" 1 "TRUE" ;
VAL_ 1203 LnKpAsstUnAvIndOn 0 "FALSE" 1 "TRUE" ;
VAL_ 1203 LnDprtrWrngUnAvIndOn 0 "FALSE" 1 "TRUE" ;
VAL_ 1203 FrwdClsnSysIndOn 0 "FALSE" 1 "TRUE" ;
VAL_ 1203 FrwdCllsnSysUnIndOn 0 "FALSE" 1 "TRUE" ;
VAL_ 1203 FrwdCllsnSysRdIndOn 0 "FALSE" 1 "TRUE" ;
VAL_ 1203 FrwdCllsnSysOffIndOn 0 "FALSE" 1 "TRUE" ;
VAL_ 1203 FrwdCllsnAlrtOffIndOn 0 "FALSE" 1 "TRUE" ;
VAL_ 1203 FrtPedtrnBrkgWrnIndOn 0 "FALSE" 1 "TRUE" ;
VAL_ 1203 TnDrvGapAdjUnvIndOn 0 "FALSE" 1 "TRUE" ;
VAL_ 1203 TeenDrvrLnDprtrWrnOffUnvIndOn 0 "FALSE" 1 "TRUE" ;
VAL_ 1203 SrvFrwdCllsnSysIndOn 0 "FALSE" 1 "TRUE" ;
VAL_ 1337 HVACTCR_RrDfgSet 0 "NoAction" 1 "RearDefogOFF" 2 "RearDefogON" ;
VAL_ 1337 HVACTCR_RecircSet 0 "NoAction" 1 "FreshAir" 2 "Recirc" ;
VAL_ 1337 HVACTCR_AirDstLtSet 0 "NoAction" 1 "Auto" 2 "Floor" 3 "FloorAndVent" 4 "Vent" 5 "VentAndWindshield" 6 "Windshield" 7 "FloorAndWindshield" 8 "FloorAndVentAndWindshield" ;
VAL_ 1337 HVACTCR_CompSet 0 "NoAction" 1 "COMP_OFF" 2 "COMP_ON" 3 "COMP_ECON" ;
VAL_ 1337 HVACTCR_TempFrtLtLvlActv 0 "FALSE" 1 "TRUE" ;
VAL_ 1337 HVACTCR_AirDstRtSet 0 "NoAction" 1 "Auto" 2 "Floor" 3 "FloorAndVent" 4 "Vent" 5 "VentAndWindshield" 6 "Windshield" 7 "FloorAndWindshield" 8 "FloorAndVentAndWindshield" ;
VAL_ 1337 HVACTCR_TempFrtRtLvlActv 0 "FALSE" 1 "TRUE" ;
VAL_ 1337 HVACTCR_RmtClmCtlReqingSets 0 "Active" 1 "Inactive" ;
VAL_ 1337 HVACTCR_FrtAutoSetChg 0 "FALSE" 1 "TRUE" ;
VAL_ 1337 HVACTCR_PwrSet 0 "NoAction" 1 "FrontOFF_RearOFF" 2 "FrontON_RearON" 3 "FrontON_RearOFF" 4 "FrontOFF_RearON" ;
VAL_ 1337 HVACTCR_SyncSet 0 "NoAction" 1 "SYNC_all" 2 "UnSYNC_all" 3 "SYNC_RearToDriver" 4 "UnSYNC_RearToDriver" ;
VAL_ 1337 HVACTCR_MaxDefrSet 0 "NoAction" 1 "MaxDefrostOff" 2 "MaxDefrostOn" ;
VAL_ 1337 RmtTrlrLtngSeqReq 0 "No Action" 1 "Off" 2 "On" ;
VAL_ 1337 HVACTCR_BlwLvlFrtActv 0 "FALSE" 1 "TRUE" ;
VAL_ 1337 TeleAlrmVisReq 0 "NO_ACTION" 1 "ACTIVE" 2 "CANCEL_FLASH" ;
VAL_ 1337 TeleAlrmHrnReq 0 "NO_ACTION" 1 "ACTIVE" 2 "CANCEL_HORN" ;
VAL_ 1204 LnCntrCntrlIndRqst 0 "Indication Off" 1 "White Indicator" 2 "Green Indicator" 3 "Yellow Indicator" 4 "Red Indicator" 5 "Blue Indicator" ;
VAL_ 1204 LnCntrCnvMsgIndRqst 0 "No Indication" 1 "Behind Slow Vehicle" 2 "Being Passed on Left" 3 "Being Passed on Right" 4 "Tailgater Detected" 5 "Left Blind Spot Occupied" 6 "Right Blind Spot Occupied" 7 "Heavy Traffic" 8 "Merging Vehicle" 9 "Slow Moving Traffic in Left Lane" 10 "Slow Moving Traffic Ahead" 11 "Slow Moving Traffic in Right Lane" 12 "Major Road Interchange Ahead" 13 "Road Exit Detected Ahead" 14 "Exit Only Lane Ahead" 15 "Lane Ending Ahead" 16 "Road Detour Detected" 17 "Take Time to Look at Road" 18 "Show Fuel Level" 19 "Show Fuel Range Normal" 20 "Show Fuel Range Low" 21 "Take Steering Active With Muting" ;
VAL_ 1204 SrvDvrAsstSystVslMsgRqstOn 0 "FALSE" 1 "TRUE" ;
VAL_ 1204 LnCntrArrwBlck5Act 0 "FALSE" 1 "TRUE" ;
VAL_ 1204 LnCntrArrwBlck4Act 0 "FALSE" 1 "TRUE" ;
VAL_ 1204 LnCntrArrwBlck3Act 0 "FALSE" 1 "TRUE" ;
VAL_ 1204 LnCntrArrwBlck2Act 0 "FALSE" 1 "TRUE" ;
VAL_ 1204 LnCntrArrwBlck1Act 0 "FALSE" 1 "TRUE" ;
VAL_ 1204 LnCntrSpchPrmtReq 0 "No Prompt" 1 "Take Steering" 2 "Take Vehicle Control" ;
VAL_ 1306 ReqAirDstRRRr 0 "NoAction" 1 "Auto" 2 "Floor" 3 "FloorAndVent" 4 "Vent" 5 "VentAndRoof" 6 "Roof" 7 "RoofAndFloor" 8 "FloorAndVentAndRoof" ;
VAL_ 1306 ReqAirDstRLRr 0 "NoAction" 1 "Auto" 2 "Floor" 3 "FloorAndVent" 4 "Vent" 5 "VentAndRoof" 6 "Roof" 7 "RoofAndFloor" 8 "FloorAndVentAndRoof" ;
VAL_ 1306 ReqAirDstChgNxtRLRr 0 "FALSE" 1 "TRUE" ;
VAL_ 1306 RrAirHandlingDrActrPwrFdbk 0 "No Action" 1 "Power Off" 2 "Power On" ;
VAL_ 1306 RrHVACCtrlInitFin 0 "FALSE" 1 "TRUE" ;
VAL_ 1306 ReqTmpLvlRRAtvRr 0 "FALSE" 1 "TRUE" ;
VAL_ 1306 ReqTmpLvlRLAtvRr 0 "FALSE" 1 "TRUE" ;
VAL_ 1306 ReqSYNC_RrChgRr 0 "FALSE" 1 "TRUE" ;
VAL_ 1306 ReqRrHVAC_PwrChgRr 0 "FALSE" 1 "TRUE" ;
VAL_ 1306 ReqRrAutoRr 0 "FALSE" 1 "TRUE" ;
VAL_ 1306 ReqBlwLvlRrAtvRr 0 "FALSE" 1 "TRUE" ;
VAL_ 1306 ReqAirDstChgNxtRRRr 0 "FALSE" 1 "TRUE" ;
VAL_ 1205 TSMEurDispSgn2Mn 0 "UnKnown" 1 "No Sign Detected" 2 "End of Speed Limit" 3 "End of All Restrictions" 4 "Begin of Motorway" 5 "End of Motorway" 6 "Begin of Expressway" 7 "End of Expressway" 8 "Begin of Play Street Zone" 9 "End of Play Street Zone" 10 "Begin of Passing Restriction" 11 "End of Passing Restriction" 12 "No Entry" 13 "Begin of City Limits" 14 "End of City Limits" 15 "Speed Limit 5" 16 "Speed Limit 10" 17 "Speed Limit 15" 18 "Speed Limit 20" 19 "Speed Limit 25" 20 "Speed Limit 30" 21 "Speed Limit 35" 22 "Speed Limit 40" 23 "Speed Limit 45" 24 "Speed Limit 50" 25 "Speed Limit 55" 26 "Speed Limit 60" 27 "Speed Limit 65" 28 "Speed Limit 70" 29 "Speed Limit 75" 30 "Speed Limit 80" 31 "Speed Limit 85" 32 "Speed Limit 90" 33 "Speed Limit 95" 34 "Speed Limit 100" 35 "Speed Limit 105" 36 "Speed Limit 110" 37 "Speed Limit 115" 38 "Speed Limit 120" 39 "Speed Limit 125" 40 "Speed Limit 130" 41 "Speed Limit 135" 42 "Speed Limit 140" 43 "Speed Limit 145" 44 "Speed Limit 150" 45 "Speed Limit 155" 46 "Speed Limit 160" 47 "Speed Limit 165" 48 "Speed Limit 170" 49 "Speed Limit 175" 50 "Speed Limit 180" 51 "Speed Limit 185" 52 "Speed Limit 190" 53 "Speed Limit 195" 54 "Speed Limit 200" ;
VAL_ 1205 TSMEurDispSgn1Mn 0 "UnKnown" 1 "No Sign Detected" 2 "End of Speed Limit" 3 "End of All Restrictions" 4 "Begin of Motorway" 5 "End of Motorway" 6 "Begin of Expressway" 7 "End of Expressway" 8 "Begin of Play Street Zone" 9 "End of Play Street Zone" 10 "Begin of Passing Restriction" 11 "End of Passing Restriction" 12 "No Entry" 13 "Begin of City Limits" 14 "End of City Limits" 15 "Speed Limit 5" 16 "Speed Limit 10" 17 "Speed Limit 15" 18 "Speed Limit 20" 19 "Speed Limit 25" 20 "Speed Limit 30" 21 "Speed Limit 35" 22 "Speed Limit 40" 23 "Speed Limit 45" 24 "Speed Limit 50" 25 "Speed Limit 55" 26 "Speed Limit 60" 27 "Speed Limit 65" 28 "Speed Limit 70" 29 "Speed Limit 75" 30 "Speed Limit 80" 31 "Speed Limit 85" 32 "Speed Limit 90" 33 "Speed Limit 95" 34 "Speed Limit 100" 35 "Speed Limit 105" 36 "Speed Limit 110" 37 "Speed Limit 115" 38 "Speed Limit 120" 39 "Speed Limit 125" 40 "Speed Limit 130" 41 "Speed Limit 135" 42 "Speed Limit 140" 43 "Speed Limit 145" 44 "Speed Limit 150" 45 "Speed Limit 155" 46 "Speed Limit 160" 47 "Speed Limit 165" 48 "Speed Limit 170" 49 "Speed Limit 175" 50 "Speed Limit 180" 51 "Speed Limit 185" 52 "Speed Limit 190" 53 "Speed Limit 195" 54 "Speed Limit 200" ;
VAL_ 1205 TSMUSAndCADispSgn1Mn 0 "UnKnown" 1 "No Sign Detected" 2 "Begin of Passing Restriction US" 3 "End of Passing Restriction US" 4 "Begin of Passing Restriction Canada" 5 "End of Passing Restriction Canada" 6 "Speed Limit 5" 7 "Speed Limit 10" 8 "Speed Limit 15" 9 "Speed Limit 20" 10 "Speed Limit 25" 11 "Speed Limit 30" 12 "Speed Limit 35" 13 "Speed Limit 40" 14 "Speed Limit 45" 15 "Speed Limit 50" 16 "Speed Limit 55" 17 "Speed Limit 60" 18 "Speed Limit 65" 19 "Speed Limit 70" 20 "Speed Limit 75" 21 "Speed Limit 80" 22 "Speed Limit 85" 23 "Speed Limit 90" 24 "Speed Limit 95" 25 "Speed Limit 100" 26 "Speed Limit 105" 27 "Speed Limit 110" 28 "Speed Limit 115" 29 "Speed Limit 120" 30 "Speed Limit 125" 31 "Speed Limit 130" 32 "Speed Limit 135" 33 "Speed Limit 140" 34 "Speed Limit 145" 35 "Speed Limit 150" 36 "Speed Limit 155" 37 "Speed Limit 160" 38 "Speed Limit 165" 39 "Speed Limit 170" 40 "Speed Limit 175" 41 "Speed Limit 180" 42 "Speed Limit 185" 43 "Speed Limit 190" 44 "Speed Limit 195" 45 "Speed Limit 200" ;
VAL_ 1205 TSMUSAndCADispSgn2Mn 0 "UnKnown" 1 "No Sign Detected" 2 "Begin of Passing Restriction US" 3 "End of Passing Restriction US" 4 "Begin of Passing Restriction Canada" 5 "End of Passing Restriction Canada" 6 "Speed Limit 5" 7 "Speed Limit 10" 8 "Speed Limit 15" 9 "Speed Limit 20" 10 "Speed Limit 25" 11 "Speed Limit 30" 12 "Speed Limit 35" 13 "Speed Limit 40" 14 "Speed Limit 45" 15 "Speed Limit 50" 16 "Speed Limit 55" 17 "Speed Limit 60" 18 "Speed Limit 65" 19 "Speed Limit 70" 20 "Speed Limit 75" 21 "Speed Limit 80" 22 "Speed Limit 85" 23 "Speed Limit 90" 24 "Speed Limit 95" 25 "Speed Limit 100" 26 "Speed Limit 105" 27 "Speed Limit 110" 28 "Speed Limit 115" 29 "Speed Limit 120" 30 "Speed Limit 125" 31 "Speed Limit 130" 32 "Speed Limit 135" 33 "Speed Limit 140" 34 "Speed Limit 145" 35 "Speed Limit 150" 36 "Speed Limit 155" 37 "Speed Limit 160" 38 "Speed Limit 165" 39 "Speed Limit 170" 40 "Speed Limit 175" 41 "Speed Limit 180" 42 "Speed Limit 185" 43 "Speed Limit 190" 44 "Speed Limit 195" 45 "Speed Limit 200" ;
VAL_ 1205 TSMEurDispSgn2AddOn 0 "UnKnown" 1 "None" 2 "Supp Sign Generic" 3 "Rain" 4 "Snow" 5 "Snow Rain" 6 "Rain Cloud" 7 "Fog" 8 "Time" 9 "Wet Conditions" 10 "Trailer" 11 "Tractor Passable" 12 "Arrow Left" 13 "Arrow Right" 14 "Distance Arrow" 15 "School" ;
VAL_ 1205 TSMEurDispSgn1AddOn 0 "UnKnown" 1 "None" 2 "Supp Sign Generic" 3 "Rain" 4 "Snow" 5 "Snow Rain" 6 "Rain Cloud" 7 "Fog" 8 "Time" 9 "Wet Conditions" 10 "Trailer" 11 "Tractor Passable" 12 "Arrow Left" 13 "Arrow Right" 14 "Distance Arrow" 15 "School" ;
VAL_ 1205 FrwdVsFlDtcnIndOn 0 "FALSE" 1 "TRUE" ;
VAL_ 1205 FrwdVsAdvWthrIndOn 0 "FALSE" 1 "TRUE" ;
VAL_ 1205 TSMUSAndCADispSgn2AddOn 0 "None" 1 "Supp Sign Generic" 2 "School" 3 "School When Flashing" 4 "End of Speed Limit" 5 "Where Workers Present" ;
VAL_ 1205 TSMUSAndCADispSgn1AddOn 0 "None" 1 "Supp Sign Generic" 2 "School" 3 "School When Flashing" 4 "End of Speed Limit" 5 "Where Workers Present" ;
VAL_ 1205 TrffcLgtAsstHUDWrnIndOn 0 "FALSE" 1 "TRUE" ;
VAL_ 1205 TrffcLgtAsstClstrWrnIndOn 0 "FALSE" 1 "TRUE" ;
VAL_ 1205 TSMSgnNtfnIndOn 0 "FALSE" 1 "TRUE" ;
VAL_ 1205 TSMPDAMnSgnFlshgReq 0 "FALSE" 1 "TRUE" ;
VAL_ 1205 TSMNoEntryIndOn 0 "FALSE" 1 "TRUE" ;
VAL_ 1205 TSMIcePsblIndOn 0 "FALSE" 1 "TRUE" ;
VAL_ 1205 TSMAddTrfSgnAvIndOn 0 "FALSE" 1 "TRUE" ;
VAL_ 1205 FrwdVsFllBlckIndOn 0 "FALSE" 1 "TRUE" ;
VAL_ 1205 TrffcLgtAsstRLADWrnIndOn 0 "FALSE" 1 "TRUE" ;
VAL_ 1233 FrtRdHgtGPSCstCurrSetVal 0 "SETTING_UNKNOWN" 1 "OFF" 2 "ON" 3 "RESERVED_3" 4 "RESERVED_4" 5 "RESERVED_5" 6 "RESERVED_6" 7 "RESERVED_7" ;
VAL_ 1233 FrtRdHgtGPSCstSetAval 0 "FALSE" 1 "TRUE" ;
VAL_ 607 EngIntkArBstPr_Inv 0 "FALSE" 1 "TRUE" ;
VAL_ 607 EngBstPrsInd_Inv 0 "FALSE" 1 "TRUE" ;
VAL_ 607 FlInjRlCtRstOcc 0 "FALSE" 1 "TRUE" ;
VAL_ 1270 ADASIS_NAVILINK_DgtlMpEfSpdLm 0 "UNKNOWN" 1 "<= 5 KM/H [MPH]" 2 "7 KM/H [MPH]" 3 "10 KM/H [MPH]" 4 "15 KM/H [MPH]" 5 "20 KM/H [MPH]" 6 "25 KM/H [MPH]" 7 "30 KM/H [MPH]" 8 "35 KM/H [MPH]" 9 "40 KM/H [MPH]" 10 "45 KM/H [MPH]" 11 "50 KM/H [MPH]" 12 "55 KM/H [MPH]" 13 "60 KM/H" 14 "MPH]65 KM/H [MPH]" 15 "70 KM/H [MPH]" 16 "75 KM/H [MPH]" 17 "80 KM/H [MPH]" 18 "85 KM/H [MPH]" 19 "90 KM/H [MPH]" 20 "95 KM/H [MPH]" 21 "100 KM/H [MPH]" 22 "105 KM/H [MPH]" 23 "110 KM/H [MPH]" 24 "115 KM/H [MPH]" 25 "120 KM/H[MPH]" 26 "130 KM/H [MPH]" 27 "140 KM/H [MPH]" 28 "150 KM/H [MPH]" 29 "160 KM/H [MPH]" 30 "UNLIMITED" 31 "NOT AVAILABLE" ;
VAL_ 1270 ADASIS_NAVILINK_CntryCd 0 "AD" 1 "AT" 2 "BE" 3 "CZ" 4 "DK" 5 "EE" 6 "FR" 7 "DE" 8 "GR" 9 "HU" 10 "IE" 11 "IT" 12 "BY" 13 "BG" 14 "CY" 15 "MT" 16 "HR" 17 "TR" 18 "RS" 19 "ME" 20 "LV" 21 "LT" 22 "LU" 23 "NL" 24 "NO" 25 "PL" 26 "PT" 27 "UK" 28 "SK" 29 "SI" 30 "ES" 31 "SE" 32 "CH" 33 "RO" 34 "RU" 35 "UA" 36 "BA" 37 "AL" 38 "MD" 39 "IS" 40 "MK" 41 "US" 42 "ZA" 43 "AU" 44 "NZ" 45 "KR" 46 "CN" ;
VAL_ 1270 ADASIS_NAVILINK_DigMpCndlSpdLmt 0 "UNKNOWN" 1 "<= 5 KM/H [MPH]" 2 "7 KM/H [MPH]" 3 "10 KM/H [MPH]" 4 "15 KM/H [MPH]" 5 "20 KM/H [MPH]" 6 "25 KM/H [MPH]" 7 "30 KM/H [MPH]" 8 "35 KM/H [MPH]" 9 "40 KM/H [MPH]" 10 "45 KM/H [MPH]" 11 "50 KM/H [MPH]" 12 "55 KM/H [MPH]" 13 "60 KM/H" 14 "MPH]65 KM/H [MPH]" 15 "70 KM/H [MPH]" 16 "75 KM/H [MPH]" 17 "80 KM/H [MPH]" 18 "85 KM/H [MPH]" 19 "90 KM/H [MPH]" 20 "95 KM/H [MPH]" 21 "100 KM/H [MPH]" 22 "105 KM/H [MPH]" 23 "110 KM/H [MPH]" 24 "115 KM/H [MPH]" 25 "120 KM/H[MPH]" 26 "130 KM/H [MPH]" 27 "140 KM/H [MPH]" 28 "150 KM/H [MPH]" 29 "160 KM/H [MPH]" 30 "UNLIMITED" 31 "NOT AVAILABLE" ;
VAL_ 1270 ADASIS_NAVILINK_DgtlMpSpdCtgry 0 "> 130 KPH OR > 80 MPH" 1 "101-130 KPH OR 65\???80 MPH" 2 "91-100 KPH OR 55\???64 MPH" 3 "71-90 KPH OR 41\???54 MPH" 4 "51-70 KPH OR 31\???40 MPH" 5 "31-50 KPH OR 21\???30 MPH" 6 "11-30 KPH OR 6 \???20 MPH" 7 "<11 KPH OR < 6 MPH" 8 "UNKNOWN" ;
VAL_ 1270 ADASIS_NAVILINK_DgtlMpPsngRst 0 "NO PASSING RESTRICTIONS" 1 "GENERAL NO OVERTAKE" 2 "FLUCTUATING (E.G. LED SIGNS)" 3 "CONDITIONAL PASSENGER CAR WITH TRAILER" 4 "CONDITIONAL TRACTORS ARE ALLOWED TO OVERTAKE" 5 "CONDITIONAL WHEN WET" 6 "CONDITIONAL WHEN SNOW" 7 "UNKNOWN CONDITION" ;
VAL_ 1270 ADASIS_NAVILINK_DigMpEfSpdLmTyp 0 "IMPLICIT" 1 "ON TRAFFIC SIGN" 2 "ONLY BY NIGHT" 3 "ONLY BY DAY" 4 "TIME OF DAY" 5 "ONLY BY RAIN" 6 "ONLY BY SNOW OR FOG" 7 "UNKOWN" ;
VAL_ 1270 ADASIS_NAVILINK_DgMpCnSpdLmTyp 0 "LANE DEPENDENT" 1 "ONLY BY FOG" 2 "ONLY BY NIGHT" 3 "ONLY BY DAY" 4 "BY TIME OF DAY" 5 "ONLY BY RAIN" 6 "ONLY BY SNOW" 7 "UNKNOWN" ;
VAL_ 1270 ADASIS_NAVILINK_DigMpPstSpdLmAs 0 "NOT ASSURED" 1 "ASSURED" ;
VAL_ 1270 ADASIS_NAVILINK_DigMpDrvngSd 0 "DRIVING SIDE LEFT" 1 "DRIVING SIDE RIGHT" ;
VAL_ 1270 ADASIS_NAVILINK_CntrldAccssRd 0 "ROAD IS NOT CONTROLLED ACCESS ROAD" 1 "ROAD IS CONTROLLED ACCESS ROAD" ;
VAL_ 1270 ADASIS_NAVILINK_BldUpFlg 0 "NOT VALID" 1 "VALID" ;
VAL_ 1234 CustMdDrvlCstmCurSetVal 0 "SETTING_UNKNOWN" 1 "CUSTOM_MODE_1" 2 "CUSTOM_MODE_2" 3 "CUSTOM_MODE_3" 4 "CUSTOM_MODE_4" 5 "CUSTOM_MODE_5" 6 "CUSTOM_MODE_6" 7 "CUSTOM_MODE_7" ;
VAL_ 1234 CustMdBrkPdlCstmCurSetVal 0 "SETTING_UNKNOWN" 1 "CUSTOM_MODE_1" 2 "CUSTOM_MODE_2" 3 "CUSTOM_MODE_3" 4 "CUSTOM_MODE_4" 5 "CUSTOM_MODE_5" 6 "CUSTOM_MODE_6" 7 "CUSTOM_MODE_7" ;
VAL_ 1234 CustMdActAeroCstmCurSetVal 0 "SETTING_UNKNOWN" 1 "CUSTOM_MODE_1" 2 "CUSTOM_MODE_2" 3 "CUSTOM_MODE_3" 4 "CUSTOM_MODE_4" 5 "CUSTOM_MODE_5" 6 "CUSTOM_MODE_6" 7 "CUSTOM_MODE_7" ;
VAL_ 1234 CustMdRideHghtCstmCurSetVal 0 "SETTING_UNKNOWN" 1 "CUSTOM_MODE_1" 2 "CUSTOM_MODE_2" 3 "CUSTOM_MODE_3" 4 "CUSTOM_MODE_4" 5 "CUSTOM_MODE_5" 6 "CUSTOM_MODE_6" 7 "CUSTOM_MODE_7" ;
VAL_ 1234 CustMdPTCstmPndSetVal 0 "SETTING_UNKNOWN" 1 "CUSTOM_MODE_1" 2 "CUSTOM_MODE_2" 3 "CUSTOM_MODE_3" 4 "CUSTOM_MODE_4" 5 "CUSTOM_MODE_5" 6 "CUSTOM_MODE_6" 7 "CUSTOM_MODE_7" ;
VAL_ 1234 CustMdPTCstmCurSetVal 0 "SETTING_UNKNOWN" 1 "CUSTOM_MODE_1" 2 "CUSTOM_MODE_2" 3 "CUSTOM_MODE_3" 4 "CUSTOM_MODE_4" 5 "CUSTOM_MODE_5" 6 "CUSTOM_MODE_6" 7 "CUSTOM_MODE_7" ;
VAL_ 1234 CustMdSpnCstmCurSetVal 0 "SETTING_UNKNOWN" 1 "CUSTOM_MODE_1" 2 "CUSTOM_MODE_2" 3 "CUSTOM_MODE_3" 4 "CUSTOM_MODE_4" 5 "CUSTOM_MODE_5" 6 "CUSTOM_MODE_6" 7 "CUSTOM_MODE_7" ;
VAL_ 1234 CustMdSndCstmCurSetVal 0 "SETTING_UNKNOWN" 1 "CUSTOM_MODE_1" 2 "CUSTOM_MODE_2" 3 "CUSTOM_MODE_3" 4 "CUSTOM_MODE_4" 5 "CUSTOM_MODE_5" 6 "CUSTOM_MODE_6" 7 "CUSTOM_MODE_7" ;
VAL_ 1234 CustMdBrkPdlCstmSetAv 0 "FALSE" 1 "TRUE" ;
VAL_ 1234 CustMdActAeroCstmSetAv 0 "FALSE" 1 "TRUE" ;
VAL_ 1234 CustMdTrcStbCstmCurSetVal 0 "SETTING_UNKNOWN" 1 "CUSTOM_MODE_1" 2 "CUSTOM_MODE_2" 3 "CUSTOM_MODE_3" 4 "CUSTOM_MODE_4" 5 "CUSTOM_MODE_5" 6 "CUSTOM_MODE_6" 7 "CUSTOM_MODE_7" ;
VAL_ 1234 CustMdStrCstmCurSetVal 0 "SETTING_UNKNOWN" 1 "CUSTOM_MODE_1" 2 "CUSTOM_MODE_2" 3 "CUSTOM_MODE_3" 4 "CUSTOM_MODE_4" 5 "CUSTOM_MODE_5" 6 "CUSTOM_MODE_6" 7 "CUSTOM_MODE_7" ;
VAL_ 1234 CustMdTrcStbCstmSetAv 0 "FALSE" 1 "TRUE" ;
VAL_ 1234 CustMdStrCstmSetAv 0 "FALSE" 1 "TRUE" ;
VAL_ 1234 CustMdSpnCstmSetAv 0 "FALSE" 1 "TRUE" ;
VAL_ 1234 CustMdSndCstmSetAv 0 "FALSE" 1 "TRUE" ;
VAL_ 1234 CustMdRideHghtCstmSetAv 0 "FALSE" 1 "TRUE" ;
VAL_ 1234 CustMdPTCstmSetAv 0 "FALSE" 1 "TRUE" ;
VAL_ 1234 CustMdDrvlCstmSetAv 0 "FALSE" 1 "TRUE" ;
VAL_ 1235 PrsnlMdActAeroCstmCurSetVal 0 "SETTING_UNKNOWN" 1 "PERSONAL_MODE_1" 2 "PERSONAL_MODE_2" 3 "PERSONAL_MODE_3" 4 "PERSONAL_MODE_4" 5 "PERSONAL_MODE_5" 6 "PERSONAL_MODE_6" 7 "PERSONAL_MODE_7" ;
VAL_ 1235 ExtdHillStrtAstCustCurSetVal 0 "SETTING_UNKNOWN" 1 "EXTENDED_HOLD" 2 "STANDARD_HOLD" 3 "RESERVED_3" 4 "RESERVED_4" 5 "RESERVED_5" 6 "RESERVED_6" 7 "RESERVED_7" ;
VAL_ 1235 DisPrfMdRq 0 "No Action" 1 "Normal" 2 "Tour" 3 "Sport" 4 "Track" 5 "Performance Mode 5" 6 "Performance Mode 6" 7 "Performance Mode 7" ;
VAL_ 1235 PrsnlMdRideHghtCstmCurSetVal 0 "SETTING_UNKNOWN" 1 "PERSONAL_MODE_1" 2 "PERSONAL_MODE_2" 3 "PERSONAL_MODE_3" 4 "PERSONAL_MODE_4" 5 "PERSONAL_MODE_5" 6 "PERSONAL_MODE_6" 7 "PERSONAL_MODE_7" ;
VAL_ 1235 PrsnlMdDrvlCstmCurSetVal 0 "SETTING_UNKNOWN" 1 "PERSONAL_MODE_1" 2 "PERSONAL_MODE_2" 3 "PERSONAL_MODE_3" 4 "PERSONAL_MODE_4" 5 "PERSONAL_MODE_5" 6 "PERSONAL_MODE_6" 7 "PERSONAL_MODE_7" ;
VAL_ 1235 PrsnlMdBrkPdlCstmCurSetVal 0 "SETTING_UNKNOWN" 1 "PERSONAL_MODE_1" 2 "PERSONAL_MODE_2" 3 "PERSONAL_MODE_3" 4 "PERSONAL_MODE_4" 5 "PERSONAL_MODE_5" 6 "PERSONAL_MODE_6" 7 "PERSONAL_MODE_7" ;
VAL_ 1235 PrsnlMdSpnCstmCurSetVal 0 "SETTING_UNKNOWN" 1 "PERSONAL_MODE_1" 2 "PERSONAL_MODE_2" 3 "PERSONAL_MODE_3" 4 "PERSONAL_MODE_4" 5 "PERSONAL_MODE_5" 6 "PERSONAL_MODE_6" 7 "PERSONAL_MODE_7" ;
VAL_ 1235 PrsnlMdSndCstmCurSetVal 0 "SETTING_UNKNOWN" 1 "PERSONAL_MODE_1" 2 "PERSONAL_MODE_2" 3 "PERSONAL_MODE_3" 4 "PERSONAL_MODE_4" 5 "PERSONAL_MODE_5" 6 "PERSONAL_MODE_6" 7 "PERSONAL_MODE_7" ;
VAL_ 1235 PrsnlMdRideHghtCstmSetAv 0 "FALSE" 1 "TRUE" ;
VAL_ 1235 PrsnlMdDrvlCstmSetAv 0 "FALSE" 1 "TRUE" ;
VAL_ 1235 PrsnlMdBrkPdlCstmSetAv 0 "FALSE" 1 "TRUE" ;
VAL_ 1235 PrsnlMdActAeroCstmSetAv 0 "FALSE" 1 "TRUE" ;
VAL_ 1235 ExtdHillStrtAstCustSetAvl 0 "FALSE" 1 "TRUE" ;
VAL_ 1235 PrsnlMdStrCstmCurSetVal 0 "SETTING_UNKNOWN" 1 "PERSONAL_MODE_1" 2 "PERSONAL_MODE_2" 3 "PERSONAL_MODE_3" 4 "PERSONAL_MODE_4" 5 "PERSONAL_MODE_5" 6 "PERSONAL_MODE_6" 7 "PERSONAL_MODE_7" ;
VAL_ 1235 TrlrBrkDtd 0 "FALSE" 1 "TRUE" ;
VAL_ 1235 PrsnlMdStrCstmSetAv 0 "FALSE" 1 "TRUE" ;
VAL_ 1235 PrsnlMdSpnCstmSetAv 0 "FALSE" 1 "TRUE" ;
VAL_ 1235 PrsnlMdSndCstmSetAv 0 "FALSE" 1 "TRUE" ;
VAL_ 1170 JckKnfDtnCstAvlFlg1 0 "FALSE" 1 "TRUE" ;
VAL_ 1170 CrgBedVwAutoLgtCstAvlFlg7 0 "FALSE" 1 "TRUE" ;
VAL_ 1170 CrgBedVwAutoLgtCstAvlFlg6 0 "FALSE" 1 "TRUE" ;
VAL_ 1170 CrgBedVwAutoLgtCstAvlFlg5 0 "FALSE" 1 "TRUE" ;
VAL_ 1170 CrgBedVwAutoLgtCstAvlFlg4 0 "FALSE" 1 "TRUE" ;
VAL_ 1170 CrgBedVwAutoLgtCstAvlFlg3 0 "FALSE" 1 "TRUE" ;
VAL_ 1170 CrgBedVwAutoLgtCstAvlFlg2 0 "FALSE" 1 "TRUE" ;
VAL_ 1170 CrgBedVwAutoLgtCstAvlFlg1 0 "FALSE" 1 "TRUE" ;
VAL_ 1170 RrVwPrkAstSymCsAvlFlg2 0 "FALSE" 1 "TRUE" ;
VAL_ 1170 RrVwPrkAstSymCsAvlFlg1 0 "FALSE" 1 "TRUE" ;
VAL_ 1170 JckKnfDtnCstAvlFlg7 0 "FALSE" 1 "TRUE" ;
VAL_ 1170 JckKnfDtnCstAvlFlg6 0 "FALSE" 1 "TRUE" ;
VAL_ 1170 JckKnfDtnCstAvlFlg5 0 "FALSE" 1 "TRUE" ;
VAL_ 1170 JckKnfDtnCstAvlFlg4 0 "FALSE" 1 "TRUE" ;
VAL_ 1170 JckKnfDtnCstAvlFlg3 0 "FALSE" 1 "TRUE" ;
VAL_ 1170 JckKnfDtnCstAvlFlg2 0 "FALSE" 1 "TRUE" ;
VAL_ 1170 SrrndVwLghtCsAvlFlg3 0 "FALSE" 1 "TRUE" ;
VAL_ 1170 SrrndVwLghtCsAvlFlg2 0 "FALSE" 1 "TRUE" ;
VAL_ 1170 SrrndVwLghtCsAvlFlg1 0 "FALSE" 1 "TRUE" ;
VAL_ 1170 RrVwPrkAstSymCsAvlFlg7 0 "FALSE" 1 "TRUE" ;
VAL_ 1170 RrVwPrkAstSymCsAvlFlg6 0 "FALSE" 1 "TRUE" ;
VAL_ 1170 RrVwPrkAstSymCsAvlFlg5 0 "FALSE" 1 "TRUE" ;
VAL_ 1170 RrVwPrkAstSymCsAvlFlg4 0 "FALSE" 1 "TRUE" ;
VAL_ 1170 RrVwPrkAstSymCsAvlFlg3 0 "FALSE" 1 "TRUE" ;
VAL_ 1170 TrlrMirVidEnblCstAvlFlg4 0 "FALSE" 1 "TRUE" ;
VAL_ 1170 TrlrMirVidEnblCstAvlFlg3 0 "FALSE" 1 "TRUE" ;
VAL_ 1170 TrlrMirVidEnblCstAvlFlg2 0 "FALSE" 1 "TRUE" ;
VAL_ 1170 TrlrMirVidEnblCstAvlFlg1 0 "FALSE" 1 "TRUE" ;
VAL_ 1170 SrrndVwLghtCsAvlFlg7 0 "FALSE" 1 "TRUE" ;
VAL_ 1170 SrrndVwLghtCsAvlFlg6 0 "FALSE" 1 "TRUE" ;
VAL_ 1170 SrrndVwLghtCsAvlFlg5 0 "FALSE" 1 "TRUE" ;
VAL_ 1170 SrrndVwLghtCsAvlFlg4 0 "FALSE" 1 "TRUE" ;
VAL_ 1170 TrlrMirVidGdlnsCstAvlFlg5 0 "FALSE" 1 "TRUE" ;
VAL_ 1170 TrlrMirVidGdlnsCstAvlFlg4 0 "FALSE" 1 "TRUE" ;
VAL_ 1170 TrlrMirVidGdlnsCstAvlFlg3 0 "FALSE" 1 "TRUE" ;
VAL_ 1170 TrlrMirVidGdlnsCstAvlFlg2 0 "FALSE" 1 "TRUE" ;
VAL_ 1170 TrlrMirVidGdlnsCstAvlFlg1 0 "FALSE" 1 "TRUE" ;
VAL_ 1170 TrlrMirVidEnblCstAvlFlg7 0 "FALSE" 1 "TRUE" ;
VAL_ 1170 TrlrMirVidEnblCstAvlFlg6 0 "FALSE" 1 "TRUE" ;
VAL_ 1170 TrlrMirVidEnblCstAvlFlg5 0 "FALSE" 1 "TRUE" ;
VAL_ 1170 TrlrMirVidGdlnsCstAvlFlg7 0 "FALSE" 1 "TRUE" ;
VAL_ 1170 TrlrMirVidGdlnsCstAvlFlg6 0 "FALSE" 1 "TRUE" ;
VAL_ 1195 IndTmpStngStFR 0 "Off" 1 "Auto" 2 "Auto Lo" 3 "Auto Hi" 4 "Manual" ;
VAL_ 1195 IndTmpStngStFL 0 "Off" 1 "Auto" 2 "Auto Lo" 3 "Auto Hi" 4 "Manual" ;
VAL_ 1195 IndTmpStngStRR 0 "Off" 1 "Auto" 2 "Auto Lo" 3 "Auto Hi" 4 "Manual" ;
VAL_ 1195 IndTmpStngStRL 0 "Off" 1 "Auto" 2 "Auto Lo" 3 "Auto Hi" 4 "Manual" ;
VAL_ 1195 NoRtDetWrngChmEvSt 0 "NO_ACTION" 1 "ACTIVE" 2 "CANCEL_CHIME" ;
VAL_ 1195 ManlPrkLmpChmEvtSt 0 "NO ACTION" 1 "ACTIVE" 2 "CANCEL CHIME" ;
VAL_ 1195 LDCLDlydLkChmEvSt 0 "NO_ACTION" 1 "ACTIVE" 2 "CANCEL_CHIME" ;
VAL_ 1195 KeyInRmdrChmEvntSt 0 "NO_ACTION" 1 "ACTIVE" 2 "CANCEL_CHIME" ;
VAL_ 1195 PwrRrClsrObstclChmEvntStat 0 "No_Action" 1 "Active" 2 "Cancel_Chime" ;
VAL_ 1195 PwrRrClsrNtfnChmEvntStat 0 "No_Action" 1 "Active" 2 "Cancel_Chime" ;
VAL_ 1195 PwrRrClsrNormOpChmEvntStat 0 "No_Action" 1 "Active" 2 "Cancel_Chime" ;
VAL_ 1195 OneSidedPrkLmpActvnChmEvtSt 0 "NO_ACTION" 1 "ACTIVE" 2 "CANCEL_CHIME" ;
VAL_ 1195 StrgLckd 0 "FALSE" 1 "TRUE" ;
VAL_ 1195 WlkAwyLkInhbtChmEvSt 0 "NO_ACTION" 1 "ACTIVE" 2 "CANCEL_CHIME" ;
VAL_ 1195 ShfttoPrkChmEvntSt 0 "NO_ACTION" 1 "ACTIVE" 2 "CANCEL_CHIME" ;
VAL_ 1195 RemLtInVhWrngChmEvSt 0 "NO_ACTION" 1 "ACTIVE" 2 "CANCEL_CHIME" ;
VAL_ 1196 IndAirDstFR 0 "Off" 1 "Auto" 2 "Floor" 3 "Floor And Vent" 4 "Vent" 5 "Vent And Windshield" 6 "Windshield" 7 "Floor And Windshield" 8 "Floor And Vent And Windshield" 9 "Max Defrost" ;
VAL_ 1196 IndAirDstFL 0 "Off" 1 "Auto" 2 "Floor" 3 "Floor And Vent" 4 "Vent" 5 "Vent And Windshield" 6 "Windshield" 7 "Floor And Windshield" 8 "Floor And Vent And Windshield" 9 "Max Defrost" ;
VAL_ 1196 IndBlwStngStFrt 0 "Off" 1 "Auto" 2 "Manual" ;
VAL_ 1196 IndRecircStng 0 "Off" 1 "Fresh Air" 2 "Recirc" ;
VAL_ 1196 IndCompStng 0 "OFF" 1 "COMP_OFF" 2 "COMP_ON" 3 "COMP_ECON" ;
VAL_ 1196 IndClmMdStng 0 "OFF" 1 "Comfort" 2 "ECO" 3 "Fan Only" ;
VAL_ 1196 IndBlwStngStRr 0 "Off" 1 "Auto" 2 "Manual" ;
VAL_ 1196 IndAirDstRL 0 "Off" 1 "Auto" 2 "Floor" 3 "Floor And Vent" 4 "Vent" 5 "Vent And Roof" 6 "Roof" 7 "Roof And Floor" 8 "Floor And Vent And Roof" ;
VAL_ 1196 IndSYNC_Rr 0 "FALSE" 1 "TRUE" ;
VAL_ 1196 IndSYNC_All 0 "FALSE" 1 "TRUE" ;
VAL_ 1196 IndRrWndDfgStng 0 "Rear Defog OFF" 1 "Rear Defog ON" ;
VAL_ 1196 IndRrHVAC_On 0 "FALSE" 1 "TRUE" ;
VAL_ 1196 IndRrHVAC_Lckd 0 "FALSE" 1 "TRUE" ;
VAL_ 1196 IndHtdFrtWshldSet 0 "HFWS_OFF" 1 "HFWS_ON" ;
VAL_ 1196 IndFrtHVAC_On 0 "FALSE" 1 "TRUE" ;
VAL_ 1196 IndAirDstRR 0 "Off" 1 "Auto" 2 "Floor" 3 "Floor And Vent" 4 "Vent" 5 "Vent And Roof" 6 "Roof" 7 "Roof And Floor" 8 "Floor And Vent And Roof" ;
VAL_ 1171 DslExhFldRmnDist_Inv 0 "FALSE" 1 "TRUE" ;
VAL_ 1350 FI_FiltdDispTotFlLvlPct_Inv 0 "FALSE" 1 "TRUE" ;
VAL_ 1350 FI_FiltdDispTotFlLvlTnk2Pct_Inv 0 "FALSE" 1 "TRUE" ;
VAL_ 1206 EngIntAirTmp_Inv 0 "FALSE" 1 "TRUE" ;
VAL_ 1206 ASIRI_Ind08 0 "FALSE" 1 "TRUE" ;
VAL_ 1206 ASIRI_Ind06 0 "FALSE" 1 "TRUE" ;
VAL_ 1206 ASIRI_Ind04 0 "FALSE" 1 "TRUE" ;
VAL_ 1206 ASIRI_Ind01 0 "FALSE" 1 "TRUE" ;
VAL_ 1206 ASIRI_Ind05 0 "FALSE" 1 "TRUE" ;
VAL_ 1206 ASIRI_Ind07 0 "FALSE" 1 "TRUE" ;
VAL_ 1206 ASIRI_Ind02 0 "FALSE" 1 "TRUE" ;
VAL_ 1206 VhSpdCntlSystmTyp 0 "No Vehicle Speed Control" 1 "Conventional Cruise Control" 2 "Adaptive Cruise Control" ;
VAL_ 1206 MnlTrnsIndReq 0 "No Indication" 1 "Indication 1" 2 "Indication 2" 3 "Indication 3" ;
VAL_ 1206 EngEmsRltMlfIndRq 0 "Continuous Indication" 1 "No Indication" 2 "Flashing 1 Hertz Indication" 3 "Flashing 2 Hertz Indication" 4 "Flashing 0.5 Hertz Indication" ;
VAL_ 1206 ASIRI_Ind03 0 "FALSE" 1 "TRUE" ;
VAL_ 1206 ElecShfPriTransCtlrMalfIndOn 0 "FALSE" 1 "TRUE" ;
VAL_ 1206 ElecShfPriShfToDrvTryAgnIndOn 0 "FALSE" 1 "TRUE" ;
VAL_ 1206 EngCmptHotWrnIndReq 0 "Off" 1 "Service" 2 "Hot Idle" 3 "Hot" ;
VAL_ 1206 ElecShftPrTwoGrsSelIndRq 0 "OFF" 1 "PARK" 2 "NEUTRAL" 3 "DRIVE" ;
VAL_ 1206 ElecShftPrLtdPrfMdIO 0 "FALSE" 1 "TRUE" ;
VAL_ 1206 ElecShftPrHldShftLevEngRngIO 0 "FALSE" 1 "TRUE" ;
VAL_ 1206 ElecShftPrDrPrkIntShftAtmpIO 0 "FALSE" 1 "TRUE" ;
VAL_ 1206 ElecShftPrDrIntShftAtmpIO 0 "FALSE" 1 "TRUE" ;
VAL_ 1206 ElecShftPrDrExitIO 0 "FALSE" 1 "TRUE" ;
VAL_ 1206 ElecShftPrDrDoorStIndIO 0 "FALSE" 1 "TRUE" ;
VAL_ 1206 ElecShftPrAtPrkIO 0 "FALSE" 1 "TRUE" ;
VAL_ 1206 ElecShfPriTrnVehOffForPrkIndOn 0 "FALSE" 1 "TRUE" ;
VAL_ 1206 EngOilChngIO 0 "FALSE" 1 "TRUE" ;
VAL_ 1206 EngNEmsnsRltMlfnAct 0 "FALSE" 1 "TRUE" ;
VAL_ 1206 EngHtStpEngIO 0 "FALSE" 1 "TRUE" ;
VAL_ 1206 EngHtFlEnrchmntIO 0 "FALSE" 1 "TRUE" ;
VAL_ 1206 EngCstFlCtOffAct 0 "FALSE" 1 "TRUE" ;
VAL_ 1206 ElecShftPrTrnMlfIO 0 "FALSE" 1 "TRUE" ;
VAL_ 1206 ElecShftPrRngInvRqIO 0 "FALSE" 1 "TRUE" ;
VAL_ 1206 ElecShftPrPrkInvRqIO 0 "FALSE" 1 "TRUE" ;
VAL_ 1206 GenFld 0 "FALSE" 1 "TRUE" ;
VAL_ 1206 EngWtrInFlIO 0 "FALSE" 1 "TRUE" ;
VAL_ 1206 EngSpdLmtnMdAct 0 "FALSE" 1 "TRUE" ;
VAL_ 1206 EngShtdwnPndgIO 0 "FALSE" 1 "TRUE" ;
VAL_ 1206 EngOilStrvtnIO 0 "FALSE" 1 "TRUE" ;
VAL_ 1206 EngOilPrsLwIO 0 "FALSE" 1 "TRUE" ;
VAL_ 1206 EngOilLvlLwIO 0 "FALSE" 1 "TRUE" ;
VAL_ 1206 EngOilHotIO 0 "FALSE" 1 "TRUE" ;
VAL_ 1206 TrnsSkpShftIO 0 "FALSE" 1 "TRUE" ;
VAL_ 1206 PTWrmgWtToShftIO 0 "FALSE" 1 "TRUE" ;
VAL_ 1206 PTExPrtclFltrWrnIO 0 "FALSE" 1 "TRUE" ;
VAL_ 1206 PTExPrtclFltrWrn2IO 0 "FALSE" 1 "TRUE" ;
VAL_ 1207 DslExFldCnWrngIndRq 0 "No Indication" 1 "Warning Level 1" 2 "Warning Level 2" 3 "Warning Level 3" 4 "Warning Level 4" 5 "Warning Level 5" 6 "Warning Level 6" 7 "Warning Level 7" 8 "Warning Level 8" 9 "Warning Level 9" 10 "Warning Level 10" 11 "Warning Level 11" 12 "Warning Level 12" 13 "Warning Level 13" 14 "Warning Level 14" 15 "Warning Level 15" ;
VAL_ 1207 DslExNxEmWrngIndRq 0 "No Indication" 1 "Warning Level 1" 2 "Warning Level 2" 3 "Warning Level 3" 4 "Warning Level 4" 5 "Warning Level 5" 6 "Warning Level 6" 7 "Warning Level 7" 8 "Warning Level 8" 9 "Warning Level 9" 10 "Warning Level 10" 11 "Warning Level 11" 12 "Warning Level 12" 13 "Warning Level 13" 14 "Warning Level 14" 15 "Warning Level 15" ;
VAL_ 1207 DslExFldTpWrngIndRq 0 "No Indication" 1 "Warning Level 1" 2 "Warning Level 2" 3 "Warning Level 3" 4 "Warning Level 4" 5 "Warning Level 5" 6 "Warning Level 6" 7 "Warning Level 7" 8 "Warning Level 8" 9 "Warning Level 9" 10 "Warning Level 10" 11 "Warning Level 11" 12 "Warning Level 12" 13 "Warning Level 13" 14 "Warning Level 14" 15 "Warning Level 15" ;
VAL_ 1207 DslExhFldWrngIdRqER 0 "No Indication" 1 "Warning Level 1" 2 "Warning Level 2" 3 "Warning Level 3" 4 "Warning Level 4" 5 "Warning Level 5" 6 "Warning Level 6" 7 "Warning Level 7" 8 "Warning Level 8" 9 "Warning Level 9" 10 "Warning Level 10" 11 "Warning Level 11" 12 "Warning Level 12" 13 "Warning Level 13" 14 "Warning Level 14" 15 "Warning Level 15" ;
VAL_ 1207 DslExhFldQlyWrngIReq 0 "No Indication" 1 "Warning Level 1" 2 "Warning Level 2" 3 "Warning Level 3" 4 "Warning Level 4" 5 "Warning Level 5" 6 "Warning Level 6" 7 "Warning Level 7" 8 "Warning Level 8" 9 "Warning Level 9" 10 "Warning Level 10" 11 "Warning Level 11" 12 "Warning Level 12" 13 "Warning Level 13" 14 "Warning Level 14" 15 "Warning Level 15" ;
VAL_ 1207 DslExhFldDiagWrnIdRq 0 "No Indication" 1 "Warning Level 1" 2 "Warning Level 2" 3 "Warning Level 3" 4 "Warning Level 4" 5 "Warning Level 5" 6 "Warning Level 6" 7 "Warning Level 7" ;
VAL_ 1207 DrvrSeltdSpdLmtrIndReq 0 "No Action" 1 "Driver Selected Speed Limiter Telltale Off" 2 "Driver Selected Speed Limiter Unavailable Telltale On" 3 "Driver Selected Speed Limiter White Telltale On" 4 "Driver Selected Speed Limiter Green Telltale On" ;
VAL_ 1207 CnvntlCruzCtlIndReq 0 "No Action" 1 "Cruise Control Telltale Off" 2 "Cruise Control Unavailable Telltale On" 3 "Cruise Control White Telltale On" 4 "Cruise Control Green Telltale On" 5 "Cruise Control Blue Telltale On" ;
VAL_ 1207 ACCompCmnd 0 "Off" 1 "On" ;
VAL_ 1207 DslEmnsOBDMrkt 0 "North America" 1 "Europe" ;
VAL_ 1207 DrSlctdSpdLmtrStSpdLmtRchd 0 "No Limit Reached" 1 "High Limit Reached" 2 "Low Limit Reached" 3 "Reserved" ;
VAL_ 1207 DrSlctdSpdLmtrSetTypActv 0 "Off" 1 "Manual" 2 "Auto" 3 "Reserved" ;
VAL_ 1207 ElecShfPriRdcSpdForReqdShfIndOn 0 "FALSE" 1 "TRUE" ;
VAL_ 1207 CbnHtrWrmUpIndOn 0 "FALSE" 1 "TRUE" ;
VAL_ 1207 DrSlctdSpdLmtrEnbld 0 "FALSE" 1 "TRUE" ;
VAL_ 1207 DrSlctdSpdLmtrActv 0 "FALSE" 1 "TRUE" ;
VAL_ 1207 CkFlFilrCapIO 0 "FALSE" 1 "TRUE" ;
VAL_ 1207 Bat12VSysUnStab 0 "FALSE" 1 "TRUE" ;
VAL_ 1207 AppCltchAutSrtIO 0 "FALSE" 1 "TRUE" ;
VAL_ 1207 AirCndOffIO 0 "FALSE" 1 "TRUE" ;
VAL_ 1173 EBDFld 0 "FALSE" 1 "TRUE" ;
VAL_ 1173 CustMdTrcStbCstmAvFlg7 0 "FALSE" 1 "TRUE" ;
VAL_ 1173 CustMdTrcStbCstmAvFlg6 0 "FALSE" 1 "TRUE" ;
VAL_ 1173 CustMdTrcStbCstmAvFlg5 0 "FALSE" 1 "TRUE" ;
VAL_ 1173 CustMdTrcStbCstmAvFlg4 0 "FALSE" 1 "TRUE" ;
VAL_ 1173 CustMdTrcStbCstmAvFlg3 0 "FALSE" 1 "TRUE" ;
VAL_ 1173 CustMdTrcStbCstmAvFlg2 0 "FALSE" 1 "TRUE" ;
VAL_ 1173 CustMdTrcStbCstmAvFlg1 0 "FALSE" 1 "TRUE" ;
VAL_ 1173 PrsnlMdActAeroCstmAvFlg1 0 "FALSE" 1 "TRUE" ;
VAL_ 1173 ExtdHillStrtAstCustAvlFlg7 0 "FALSE" 1 "TRUE" ;
VAL_ 1173 ExtdHillStrtAstCustAvlFlg6 0 "FALSE" 1 "TRUE" ;
VAL_ 1173 ExtdHillStrtAstCustAvlFlg5 0 "FALSE" 1 "TRUE" ;
VAL_ 1173 ExtdHillStrtAstCustAvlFlg4 0 "FALSE" 1 "TRUE" ;
VAL_ 1173 ExtdHillStrtAstCustAvlFlg3 0 "FALSE" 1 "TRUE" ;
VAL_ 1173 ExtdHillStrtAstCustAvlFlg2 0 "FALSE" 1 "TRUE" ;
VAL_ 1173 ExtdHillStrtAstCustAvlFlg1 0 "FALSE" 1 "TRUE" ;
VAL_ 1173 PrsnlMdBrkPdlCstmAvFlg2 0 "FALSE" 1 "TRUE" ;
VAL_ 1173 PrsnlMdBrkPdlCstmAvFlg1 0 "FALSE" 1 "TRUE" ;
VAL_ 1173 PrsnlMdActAeroCstmAvFlg7 0 "FALSE" 1 "TRUE" ;
VAL_ 1173 PrsnlMdActAeroCstmAvFlg6 0 "FALSE" 1 "TRUE" ;
VAL_ 1173 PrsnlMdActAeroCstmAvFlg5 0 "FALSE" 1 "TRUE" ;
VAL_ 1173 PrsnlMdActAeroCstmAvFlg4 0 "FALSE" 1 "TRUE" ;
VAL_ 1173 PrsnlMdActAeroCstmAvFlg3 0 "FALSE" 1 "TRUE" ;
VAL_ 1173 PrsnlMdActAeroCstmAvFlg2 0 "FALSE" 1 "TRUE" ;
VAL_ 1173 PrsnlMdDrvlCstmAvFlg3 0 "FALSE" 1 "TRUE" ;
VAL_ 1173 PrsnlMdDrvlCstmAvFlg2 0 "FALSE" 1 "TRUE" ;
VAL_ 1173 PrsnlMdDrvlCstmAvFlg1 0 "FALSE" 1 "TRUE" ;
VAL_ 1173 PrsnlMdBrkPdlCstmAvFlg7 0 "FALSE" 1 "TRUE" ;
VAL_ 1173 PrsnlMdBrkPdlCstmAvFlg6 0 "FALSE" 1 "TRUE" ;
VAL_ 1173 PrsnlMdBrkPdlCstmAvFlg5 0 "FALSE" 1 "TRUE" ;
VAL_ 1173 PrsnlMdBrkPdlCstmAvFlg4 0 "FALSE" 1 "TRUE" ;
VAL_ 1173 PrsnlMdBrkPdlCstmAvFlg3 0 "FALSE" 1 "TRUE" ;
VAL_ 1173 PrsnlMdRideHghtCstmAvFlg4 0 "FALSE" 1 "TRUE" ;
VAL_ 1173 PrsnlMdRideHghtCstmAvFlg3 0 "FALSE" 1 "TRUE" ;
VAL_ 1173 PrsnlMdRideHghtCstmAvFlg2 0 "FALSE" 1 "TRUE" ;
VAL_ 1173 PrsnlMdRideHghtCstmAvFlg1 0 "FALSE" 1 "TRUE" ;
VAL_ 1173 PrsnlMdDrvlCstmAvFlg7 0 "FALSE" 1 "TRUE" ;
VAL_ 1173 PrsnlMdDrvlCstmAvFlg6 0 "FALSE" 1 "TRUE" ;
VAL_ 1173 PrsnlMdDrvlCstmAvFlg5 0 "FALSE" 1 "TRUE" ;
VAL_ 1173 PrsnlMdDrvlCstmAvFlg4 0 "FALSE" 1 "TRUE" ;
VAL_ 1173 PrsnlMdSndCstmAvFlg5 0 "FALSE" 1 "TRUE" ;
VAL_ 1173 PrsnlMdSndCstmAvFlg4 0 "FALSE" 1 "TRUE" ;
VAL_ 1173 PrsnlMdSndCstmAvFlg3 0 "FALSE" 1 "TRUE" ;
VAL_ 1173 PrsnlMdSndCstmAvFlg2 0 "FALSE" 1 "TRUE" ;
VAL_ 1173 PrsnlMdSndCstmAvFlg1 0 "FALSE" 1 "TRUE" ;
VAL_ 1173 PrsnlMdRideHghtCstmAvFlg7 0 "FALSE" 1 "TRUE" ;
VAL_ 1173 PrsnlMdRideHghtCstmAvFlg6 0 "FALSE" 1 "TRUE" ;
VAL_ 1173 PrsnlMdRideHghtCstmAvFlg5 0 "FALSE" 1 "TRUE" ;
VAL_ 1173 PrsnlMdSpnCstmAvFlg6 0 "FALSE" 1 "TRUE" ;
VAL_ 1173 PrsnlMdSpnCstmAvFlg5 0 "FALSE" 1 "TRUE" ;
VAL_ 1173 PrsnlMdSpnCstmAvFlg4 0 "FALSE" 1 "TRUE" ;
VAL_ 1173 PrsnlMdSpnCstmAvFlg3 0 "FALSE" 1 "TRUE" ;
VAL_ 1173 PrsnlMdSpnCstmAvFlg2 0 "FALSE" 1 "TRUE" ;
VAL_ 1173 PrsnlMdSpnCstmAvFlg1 0 "FALSE" 1 "TRUE" ;
VAL_ 1173 PrsnlMdSndCstmAvFlg7 0 "FALSE" 1 "TRUE" ;
VAL_ 1173 PrsnlMdSndCstmAvFlg6 0 "FALSE" 1 "TRUE" ;
VAL_ 1173 PrsnlMdStrCstmAvFlg7 0 "FALSE" 1 "TRUE" ;
VAL_ 1173 PrsnlMdStrCstmAvFlg6 0 "FALSE" 1 "TRUE" ;
VAL_ 1173 PrsnlMdStrCstmAvFlg5 0 "FALSE" 1 "TRUE" ;
VAL_ 1173 PrsnlMdStrCstmAvFlg4 0 "FALSE" 1 "TRUE" ;
VAL_ 1173 PrsnlMdStrCstmAvFlg3 0 "FALSE" 1 "TRUE" ;
VAL_ 1173 PrsnlMdStrCstmAvFlg2 0 "FALSE" 1 "TRUE" ;
VAL_ 1173 PrsnlMdStrCstmAvFlg1 0 "FALSE" 1 "TRUE" ;
VAL_ 1173 PrsnlMdSpnCstmAvFlg7 0 "FALSE" 1 "TRUE" ;
VAL_ 1174 CustMdActAeroCstmAvFlg6 0 "FALSE" 1 "TRUE" ;
VAL_ 1174 CustMdActAeroCstmAvFlg5 0 "FALSE" 1 "TRUE" ;
VAL_ 1174 CustMdActAeroCstmAvFlg4 0 "FALSE" 1 "TRUE" ;
VAL_ 1174 CustMdActAeroCstmAvFlg3 0 "FALSE" 1 "TRUE" ;
VAL_ 1174 CustMdActAeroCstmAvFlg2 0 "FALSE" 1 "TRUE" ;
VAL_ 1174 CustMdActAeroCstmAvFlg1 0 "FALSE" 1 "TRUE" ;
VAL_ 1174 BrkFldLvlSt 0 "Normal" 1 "Low" 2 "Unknown" ;
VAL_ 1174 CustMdBrkPdlCstmAvFlg7 0 "FALSE" 1 "TRUE" ;
VAL_ 1174 CustMdBrkPdlCstmAvFlg6 0 "FALSE" 1 "TRUE" ;
VAL_ 1174 CustMdBrkPdlCstmAvFlg5 0 "FALSE" 1 "TRUE" ;
VAL_ 1174 CustMdBrkPdlCstmAvFlg4 0 "FALSE" 1 "TRUE" ;
VAL_ 1174 CustMdBrkPdlCstmAvFlg3 0 "FALSE" 1 "TRUE" ;
VAL_ 1174 CustMdBrkPdlCstmAvFlg2 0 "FALSE" 1 "TRUE" ;
VAL_ 1174 CustMdBrkPdlCstmAvFlg1 0 "FALSE" 1 "TRUE" ;
VAL_ 1174 CustMdActAeroCstmAvFlg7 0 "FALSE" 1 "TRUE" ;
VAL_ 1174 CustMdPTCstmAvFlg1 0 "FALSE" 1 "TRUE" ;
VAL_ 1174 CustMdDrvlCstmAvFlg7 0 "FALSE" 1 "TRUE" ;
VAL_ 1174 CustMdDrvlCstmAvFlg6 0 "FALSE" 1 "TRUE" ;
VAL_ 1174 CustMdDrvlCstmAvFlg5 0 "FALSE" 1 "TRUE" ;
VAL_ 1174 CustMdDrvlCstmAvFlg4 0 "FALSE" 1 "TRUE" ;
VAL_ 1174 CustMdDrvlCstmAvFlg3 0 "FALSE" 1 "TRUE" ;
VAL_ 1174 CustMdDrvlCstmAvFlg2 0 "FALSE" 1 "TRUE" ;
VAL_ 1174 CustMdDrvlCstmAvFlg1 0 "FALSE" 1 "TRUE" ;
VAL_ 1174 CustMdRideHghtCstmAvFlg2 0 "FALSE" 1 "TRUE" ;
VAL_ 1174 CustMdRideHghtCstmAvFlg1 0 "FALSE" 1 "TRUE" ;
VAL_ 1174 CustMdPTCstmAvFlg7 0 "FALSE" 1 "TRUE" ;
VAL_ 1174 CustMdPTCstmAvFlg6 0 "FALSE" 1 "TRUE" ;
VAL_ 1174 CustMdPTCstmAvFlg5 0 "FALSE" 1 "TRUE" ;
VAL_ 1174 CustMdPTCstmAvFlg4 0 "FALSE" 1 "TRUE" ;
VAL_ 1174 CustMdPTCstmAvFlg3 0 "FALSE" 1 "TRUE" ;
VAL_ 1174 CustMdPTCstmAvFlg2 0 "FALSE" 1 "TRUE" ;
VAL_ 1174 CustMdSndCstmAvFlg3 0 "FALSE" 1 "TRUE" ;
VAL_ 1174 CustMdSndCstmAvFlg2 0 "FALSE" 1 "TRUE" ;
VAL_ 1174 CustMdSndCstmAvFlg1 0 "FALSE" 1 "TRUE" ;
VAL_ 1174 CustMdRideHghtCstmAvFlg7 0 "FALSE" 1 "TRUE" ;
VAL_ 1174 CustMdRideHghtCstmAvFlg6 0 "FALSE" 1 "TRUE" ;
VAL_ 1174 CustMdRideHghtCstmAvFlg5 0 "FALSE" 1 "TRUE" ;
VAL_ 1174 CustMdRideHghtCstmAvFlg4 0 "FALSE" 1 "TRUE" ;
VAL_ 1174 CustMdRideHghtCstmAvFlg3 0 "FALSE" 1 "TRUE" ;
VAL_ 1174 CustMdSpnCstmAvFlg4 0 "FALSE" 1 "TRUE" ;
VAL_ 1174 CustMdSpnCstmAvFlg3 0 "FALSE" 1 "TRUE" ;
VAL_ 1174 CustMdSpnCstmAvFlg2 0 "FALSE" 1 "TRUE" ;
VAL_ 1174 CustMdSpnCstmAvFlg1 0 "FALSE" 1 "TRUE" ;
VAL_ 1174 CustMdSndCstmAvFlg7 0 "FALSE" 1 "TRUE" ;
VAL_ 1174 CustMdSndCstmAvFlg6 0 "FALSE" 1 "TRUE" ;
VAL_ 1174 CustMdSndCstmAvFlg5 0 "FALSE" 1 "TRUE" ;
VAL_ 1174 CustMdSndCstmAvFlg4 0 "FALSE" 1 "TRUE" ;
VAL_ 1174 CustMdStrCstmAvFlg5 0 "FALSE" 1 "TRUE" ;
VAL_ 1174 CustMdStrCstmAvFlg4 0 "FALSE" 1 "TRUE" ;
VAL_ 1174 CustMdStrCstmAvFlg3 0 "FALSE" 1 "TRUE" ;
VAL_ 1174 CustMdStrCstmAvFlg2 0 "FALSE" 1 "TRUE" ;
VAL_ 1174 CustMdStrCstmAvFlg1 0 "FALSE" 1 "TRUE" ;
VAL_ 1174 CustMdSpnCstmAvFlg7 0 "FALSE" 1 "TRUE" ;
VAL_ 1174 CustMdSpnCstmAvFlg6 0 "FALSE" 1 "TRUE" ;
VAL_ 1174 CustMdSpnCstmAvFlg5 0 "FALSE" 1 "TRUE" ;
VAL_ 1174 CustMdStrCstmAvFlg7 0 "FALSE" 1 "TRUE" ;
VAL_ 1174 CustMdStrCstmAvFlg6 0 "FALSE" 1 "TRUE" ;
